VERSION ""

NS_ :

BS_:

BU_: PowertrainControlModule AtmosphericSensor SafetyRestraintSystem2 Aftertreatment_2_GasOutlet Aftertreatment_2_GasIntake DieselParticulateFilterControl Turbocharger SafetyRestraintSystem1 CabDisplay2 Aftertreatment_1_GasOutlet Aftertreatment_1_GasIntake OnBoardDataLogger OffBoardDiagnosticTool2 OffBoardDiagnosticTool1 FileServer ParkingBrakeController SeatController2 FanDriveController SteeringColumnUnit CommunicationUnitRadio CommunicationUnitSatellite CommunicationUnitCellular PropulsionBatteryCharger ChassisController2 ChassisController1 EngineValveControl AuxiliaryHeater2 AuxiliaryHeater1 ClutchUnit RampControl InformationSystem1 SuspensionSystemController2 OilSensor VehicleDynamicStability ExhaustEmissionController TransmissionDisplay2 TransmissionDisplay1 ClimateControl2 WaterPumpController RearAxleSteeringController LightingOperatorControl SeatController1 IgnitionController2 IgnitionController1 TirePressureController CabController2 CabController1 PneumaticSystemController SuspensionSystemController1 HydraulicPumpController EnduranceBrakingSystem RetarderExhaustEngine2 OnBoardDiagnosticUnit HeadwayController RetarderExhaustEngine1 CabDisplay1 ManagementComputer VirtualTerminal OffVehicleGateway PowerTakeOffFront HitchControl AuxiliaryValveControl BodyController TractorTrailerBridge1 StarterSystem ElectricalSystem VehicleSecurity VehicleNavigation AerodynamicControl ElectricalChargingSystem ClimateControl1 TripRecorder InstrumentCluster SuspensionDriveAxle2 SuspensionDriveAxle1 SuspensionSteerAxle SteeringController FuelSystem CruiseControl RetarderDriveline RetarderEngine BrakesDriveAxle2 BrakesDriveAxle1 BrakesSystemController BrakesSteerAxle AxleDrive2 AxleDrive1 AxleSteering PowerTakeOff ShiftConsoleSecondary ShiftConsolePrimary Transmission2 Transmission1 Engine2 Engine1

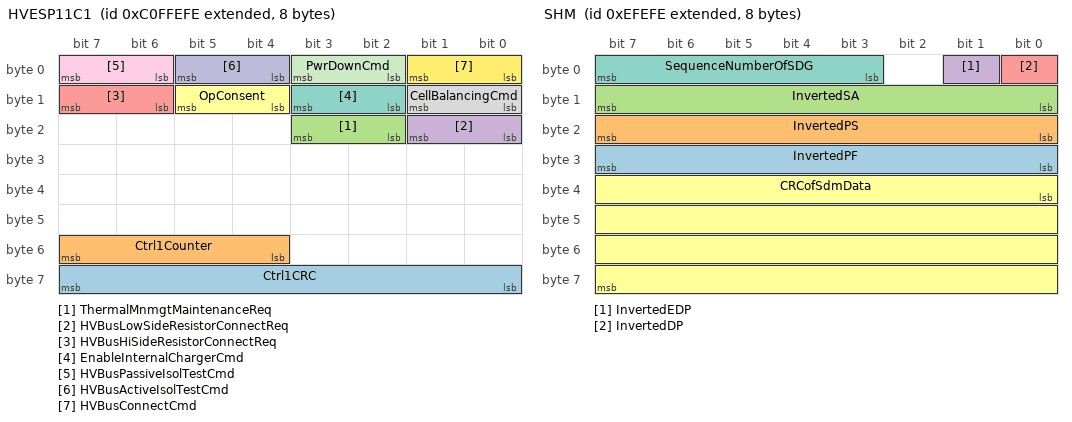
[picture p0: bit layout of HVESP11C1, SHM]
BO_ 2349858558 HVESP11C1: 8 Vector__XXX
 SG_ Ctrl1CRC : 56|8@1+ (1,0) [0|255] "" Vector__XXX
 SG_ Ctrl1Counter : 52|4@1+ (1,0) [0|15] "" Vector__XXX
 SG_ ThermalMnmgtMaintenanceReq : 18|2@1+ (1,0) [0|3] "" Vector__XXX
 SG_ HVBusLowSideResistorConnectReq : 16|2@1+ (1,0) [0|3] "" Vector__XXX
 SG_ HVBusHiSideResistorConnectReq : 14|2@1+ (1,0) [0|3] "" Vector__XXX
 SG_ OpConsent : 12|2@1+ (1,0) [0|3] "" Vector__XXX
 SG_ EnableInternalChargerCmd : 10|2@1+ (1,0) [0|3] "" Vector__XXX
 SG_ CellBalancingCmd : 8|2@1+ (1,0) [0|3] "" Vector__XXX
 SG_ HVBusPassiveIsolTestCmd : 6|2@1+ (1,0) [0|3] "" Vector__XXX
 SG_ HVBusActiveIsolTestCmd : 4|2@1+ (1,0) [0|3] "" Vector__XXX
 SG_ PwrDownCmd : 2|2@1+ (1,0) [0|3] "" Vector__XXX
 SG_ HVBusConnectCmd : 0|2@1+ (1,0) [0|3] "" Vector__XXX

BO_ 2148466430 SHM: 8 Vector__XXX
 SG_ InvertedPF : 24|8@1+ (-1,255) [0|0] "" Vector__XXX
 SG_ InvertedPS : 16|8@1+ (-1,255) [0|0] "" Vector__XXX
 SG_ InvertedSA : 8|8@1+ (-1,255) [0|0] "" Vector__XXX
 SG_ InvertedEDP : 1|1@1+ (-1,1) [0|0] "" Vector__XXX
 SG_ InvertedDP : 0|1@1+ (-1,1) [0|0] "" Vector__XXX
 SG_ CRCofSdmData : 32|32@1+ (1,0) [0|0] "" Vector__XXX
 SG_ SequenceNumberOfSDG : 3|5@1+ (1,0) [0|0] "" Vector__XXX

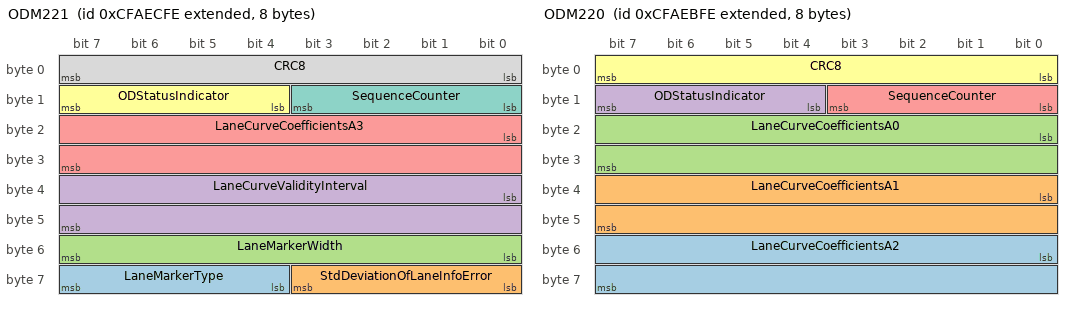
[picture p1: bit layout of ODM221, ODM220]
BO_ 2365254910 ODM221: 8 Vector__XXX
 SG_ LaneMarkerType : 60|4@1- (1,0) [0|15] "" Vector__XXX
 SG_ StdDeviationOfLaneInfoError : 56|4@1- (1,0) [0|15] "" Vector__XXX
 SG_ LaneMarkerWidth : 48|8@1+ (0.01,0) [0|2.5] "m" Vector__XXX
 SG_ LaneCurveValidityInterval : 32|16@1- (0.01,0) [-321.28|321.27] "m" Vector__XXX
 SG_ LaneCurveCoefficientsA3 : 16|16@1- (0.01,0) [-321.28|321.27] "" Vector__XXX
 SG_ ODStatusIndicator : 12|4@1+ (1,0) [0|0] "" Vector__XXX
 SG_ SequenceCounter : 8|4@1+ (1,0) [0|15] "" Vector__XXX
 SG_ CRC8 : 0|8@1+ (1,0) [0|255] "" Vector__XXX

BO_ 2365254654 ODM220: 8 Vector__XXX
 SG_ LaneCurveCoefficientsA2 : 48|16@1- (0.01,0) [-321.28|321.27] "" Vector__XXX
 SG_ LaneCurveCoefficientsA1 : 32|16@1- (0.01,0) [-321.28|321.27] "" Vector__XXX
 SG_ LaneCurveCoefficientsA0 : 16|16@1- (0.01,0) [-321.28|321.27] "" Vector__XXX
 SG_ ODStatusIndicator : 12|4@1+ (1,0) [0|0] "" Vector__XXX
 SG_ SequenceCounter : 8|4@1+ (1,0) [0|15] "" Vector__XXX
 SG_ CRC8 : 0|8@1+ (1,0) [0|255] "" Vector__XXX

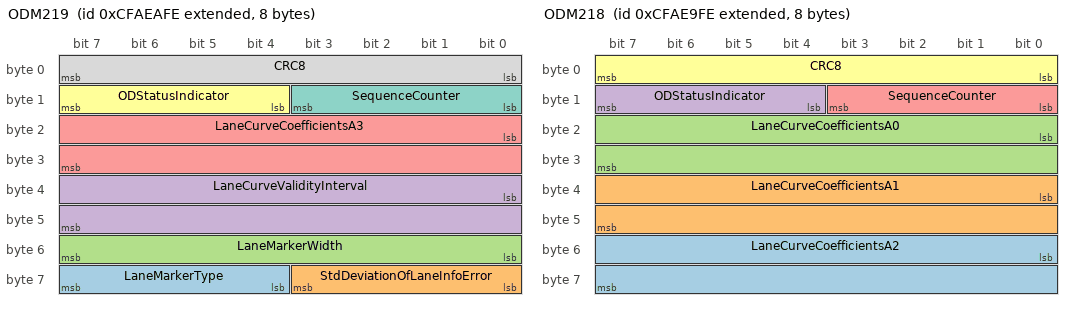
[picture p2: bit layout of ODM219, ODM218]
BO_ 2365254398 ODM219: 8 Vector__XXX
 SG_ LaneMarkerType : 60|4@1- (1,0) [0|15] "" Vector__XXX
 SG_ StdDeviationOfLaneInfoError : 56|4@1- (1,0) [0|15] "" Vector__XXX
 SG_ LaneMarkerWidth : 48|8@1+ (0.01,0) [0|2.5] "m" Vector__XXX
 SG_ LaneCurveValidityInterval : 32|16@1- (0.01,0) [-321.28|321.27] "m" Vector__XXX
 SG_ LaneCurveCoefficientsA3 : 16|16@1- (0.01,0) [-321.28|321.27] "" Vector__XXX
 SG_ ODStatusIndicator : 12|4@1+ (1,0) [0|0] "" Vector__XXX
 SG_ SequenceCounter : 8|4@1+ (1,0) [0|15] "" Vector__XXX
 SG_ CRC8 : 0|8@1+ (1,0) [0|255] "" Vector__XXX

BO_ 2365254142 ODM218: 8 Vector__XXX
 SG_ LaneCurveCoefficientsA2 : 48|16@1- (0.01,0) [-321.28|321.27] "" Vector__XXX
 SG_ LaneCurveCoefficientsA1 : 32|16@1- (0.01,0) [-321.28|321.27] "" Vector__XXX
 SG_ LaneCurveCoefficientsA0 : 16|16@1- (0.01,0) [-321.28|321.27] "" Vector__XXX
 SG_ ODStatusIndicator : 12|4@1+ (1,0) [0|0] "" Vector__XXX
 SG_ SequenceCounter : 8|4@1+ (1,0) [0|15] "" Vector__XXX
 SG_ CRC8 : 0|8@1+ (1,0) [0|255] "" Vector__XXX

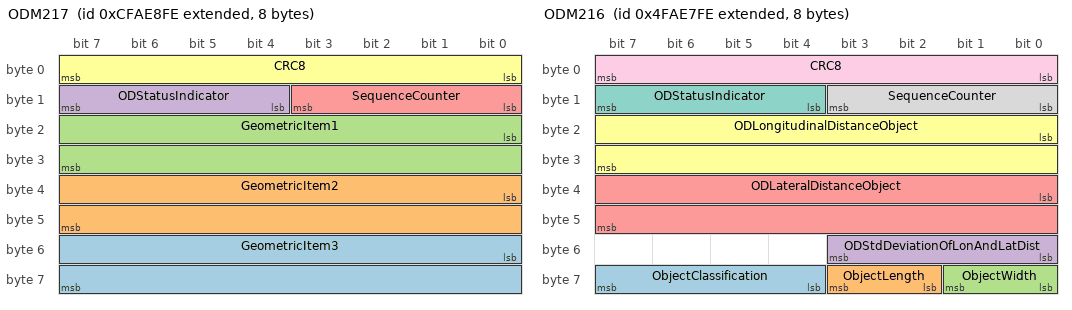
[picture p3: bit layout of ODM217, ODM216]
BO_ 2365253886 ODM217: 8 Vector__XXX
 SG_ GeometricItem3 : 48|16@1- (0.01,0) [-321.28|321.27] "m" Vector__XXX
 SG_ GeometricItem2 : 32|16@1- (0.01,0) [-321.28|321.27] "m" Vector__XXX
 SG_ GeometricItem1 : 16|16@1- (0.01,0) [-321.28|321.27] "m" Vector__XXX
 SG_ ODStatusIndicator : 12|4@1+ (1,0) [0|0] "" Vector__XXX
 SG_ SequenceCounter : 8|4@1+ (1,0) [0|15] "" Vector__XXX
 SG_ CRC8 : 0|8@1+ (1,0) [0|255] "" Vector__XXX

BO_ 2231035902 ODM216: 8 Vector__XXX
 SG_ ObjectClassification : 60|4@1+ (1,0) [0|15] "" Vector__XXX
 SG_ ObjectLength : 58|2@1+ (1,0) [0|3] "" Vector__XXX
 SG_ ObjectWidth : 56|2@1+ (1,0) [0|3] "" Vector__XXX
 SG_ ODStdDeviationOfLonAndLatDist : 48|4@1+ (1,0) [0|15] "" Vector__XXX
 SG_ ODLateralDistanceObject : 32|16@1- (0.01,0) [-321.28|321.27] "m" Vector__XXX
 SG_ ODLongitudinalDistanceObject : 16|16@1- (0.01,0) [-321.28|321.27] "m" Vector__XXX
 SG_ ODStatusIndicator : 12|4@1+ (1,0) [0|0] "" Vector__XXX
 SG_ SequenceCounter : 8|4@1+ (1,0) [0|15] "" Vector__XXX
 SG_ CRC8 : 0|8@1+ (1,0) [0|255] "" Vector__XXX

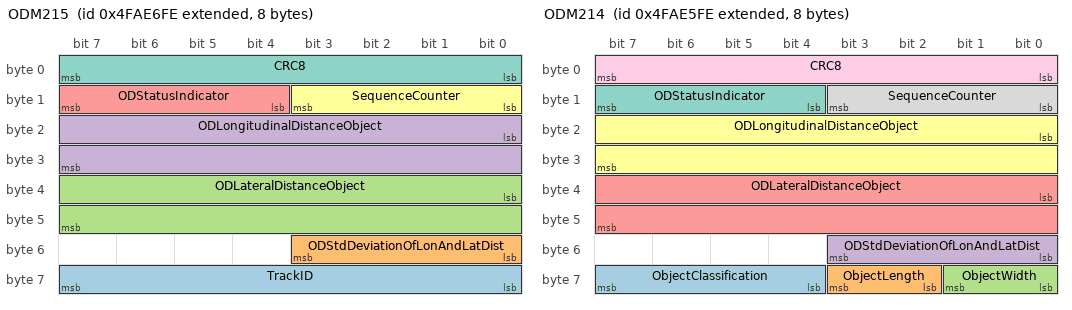
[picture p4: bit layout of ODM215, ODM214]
BO_ 2231035646 ODM215: 8 Vector__XXX
 SG_ TrackID : 56|8@1+ (1,0) [1|250] "" Vector__XXX
 SG_ ODStdDeviationOfLonAndLatDist : 48|4@1+ (1,0) [0|15] "" Vector__XXX
 SG_ ODLateralDistanceObject : 32|16@1- (0.01,0) [-321.28|321.27] "m" Vector__XXX
 SG_ ODLongitudinalDistanceObject : 16|16@1- (0.01,0) [-321.28|321.27] "m" Vector__XXX
 SG_ ODStatusIndicator : 12|4@1+ (1,0) [0|0] "" Vector__XXX
 SG_ SequenceCounter : 8|4@1+ (1,0) [0|15] "" Vector__XXX
 SG_ CRC8 : 0|8@1+ (1,0) [0|255] "" Vector__XXX

BO_ 2231035390 ODM214: 8 Vector__XXX
 SG_ ObjectClassification : 60|4@1+ (1,0) [0|15] "" Vector__XXX
 SG_ ObjectLength : 58|2@1+ (1,0) [0|3] "" Vector__XXX
 SG_ ObjectWidth : 56|2@1+ (1,0) [0|3] "" Vector__XXX
 SG_ ODStdDeviationOfLonAndLatDist : 48|4@1+ (1,0) [0|15] "" Vector__XXX
 SG_ ODLateralDistanceObject : 32|16@1- (0.01,0) [-321.28|321.27] "m" Vector__XXX
 SG_ ODLongitudinalDistanceObject : 16|16@1- (0.01,0) [-321.28|321.27] "m" Vector__XXX
 SG_ ODStatusIndicator : 12|4@1+ (1,0) [0|0] "" Vector__XXX
 SG_ SequenceCounter : 8|4@1+ (1,0) [0|15] "" Vector__XXX
 SG_ CRC8 : 0|8@1+ (1,0) [0|255] "" Vector__XXX

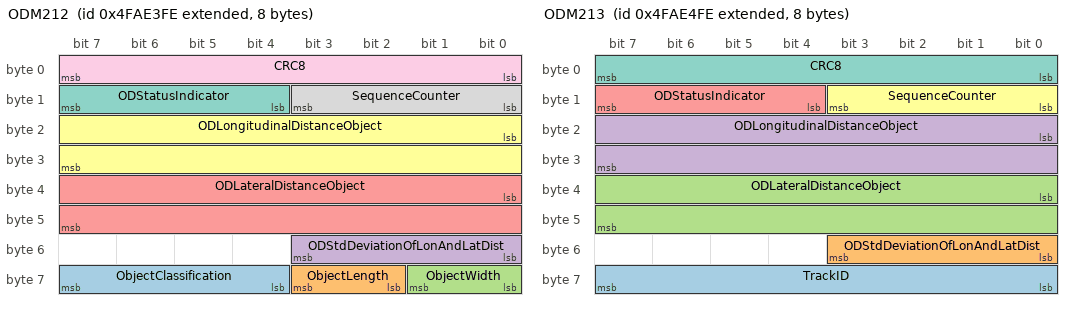
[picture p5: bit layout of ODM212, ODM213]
BO_ 2231034878 ODM212: 8 Vector__XXX
 SG_ ObjectClassification : 60|4@1+ (1,0) [0|15] "" Vector__XXX
 SG_ ObjectLength : 58|2@1+ (1,0) [0|3] "" Vector__XXX
 SG_ ObjectWidth : 56|2@1+ (1,0) [0|3] "" Vector__XXX
 SG_ ODStdDeviationOfLonAndLatDist : 48|4@1+ (1,0) [0|15] "" Vector__XXX
 SG_ ODLateralDistanceObject : 32|16@1- (0.01,0) [-321.28|321.27] "m" Vector__XXX
 SG_ ODLongitudinalDistanceObject : 16|16@1- (0.01,0) [-321.28|321.27] "m" Vector__XXX
 SG_ ODStatusIndicator : 12|4@1+ (1,0) [0|0] "" Vector__XXX
 SG_ SequenceCounter : 8|4@1+ (1,0) [0|15] "" Vector__XXX
 SG_ CRC8 : 0|8@1+ (1,0) [0|255] "" Vector__XXX

BO_ 2231035134 ODM213: 8 Vector__XXX
 SG_ TrackID : 56|8@1+ (1,0) [1|250] "" Vector__XXX
 SG_ ODStdDeviationOfLonAndLatDist : 48|4@1+ (1,0) [0|15] "" Vector__XXX
 SG_ ODLateralDistanceObject : 32|16@1- (0.01,0) [-321.28|321.27] "m" Vector__XXX
 SG_ ODLongitudinalDistanceObject : 16|16@1- (0.01,0) [-321.28|321.27] "m" Vector__XXX
 SG_ ODStatusIndicator : 12|4@1+ (1,0) [0|0] "" Vector__XXX
 SG_ SequenceCounter : 8|4@1+ (1,0) [0|15] "" Vector__XXX
 SG_ CRC8 : 0|8@1+ (1,0) [0|255] "" Vector__XXX

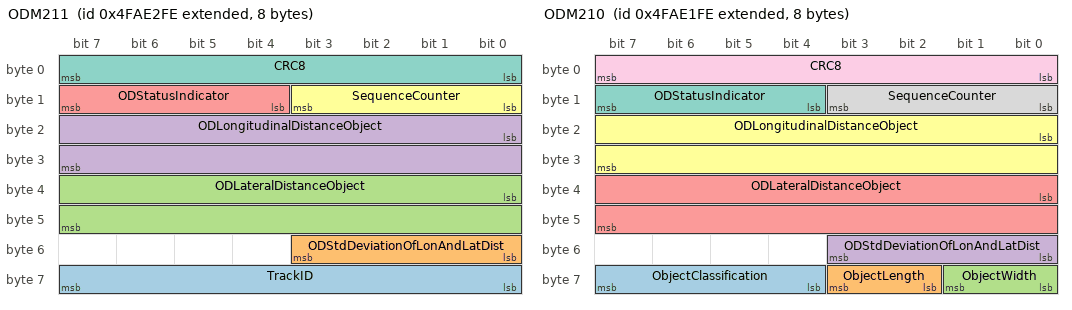
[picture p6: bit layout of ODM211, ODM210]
BO_ 2231034622 ODM211: 8 Vector__XXX
 SG_ TrackID : 56|8@1+ (1,0) [1|250] "" Vector__XXX
 SG_ ODStdDeviationOfLonAndLatDist : 48|4@1+ (1,0) [0|15] "" Vector__XXX
 SG_ ODLateralDistanceObject : 32|16@1- (0.01,0) [-321.28|321.27] "m" Vector__XXX
 SG_ ODLongitudinalDistanceObject : 16|16@1- (0.01,0) [-321.28|321.27] "m" Vector__XXX
 SG_ ODStatusIndicator : 12|4@1+ (1,0) [0|0] "" Vector__XXX
 SG_ SequenceCounter : 8|4@1+ (1,0) [0|15] "" Vector__XXX
 SG_ CRC8 : 0|8@1+ (1,0) [0|255] "" Vector__XXX

BO_ 2231034366 ODM210: 8 Vector__XXX
 SG_ ObjectClassification : 60|4@1+ (1,0) [0|15] "" Vector__XXX
 SG_ ObjectLength : 58|2@1+ (1,0) [0|3] "" Vector__XXX
 SG_ ObjectWidth : 56|2@1+ (1,0) [0|3] "" Vector__XXX
 SG_ ODStdDeviationOfLonAndLatDist : 48|4@1+ (1,0) [0|15] "" Vector__XXX
 SG_ ODLateralDistanceObject : 32|16@1- (0.01,0) [-321.28|321.27] "m" Vector__XXX
 SG_ ODLongitudinalDistanceObject : 16|16@1- (0.01,0) [-321.28|321.27] "m" Vector__XXX
 SG_ ODStatusIndicator : 12|4@1+ (1,0) [0|0] "" Vector__XXX
 SG_ SequenceCounter : 8|4@1+ (1,0) [0|15] "" Vector__XXX
 SG_ CRC8 : 0|8@1+ (1,0) [0|255] "" Vector__XXX

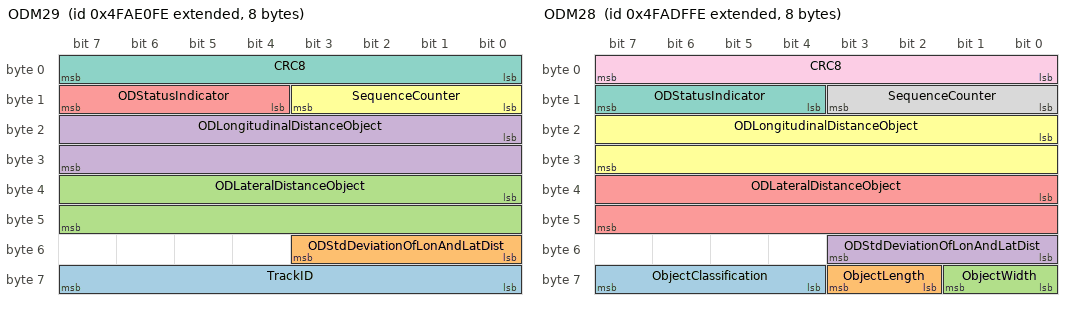
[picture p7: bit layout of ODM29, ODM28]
BO_ 2231034110 ODM29: 8 Vector__XXX
 SG_ TrackID : 56|8@1+ (1,0) [1|250] "" Vector__XXX
 SG_ ODStdDeviationOfLonAndLatDist : 48|4@1+ (1,0) [0|15] "" Vector__XXX
 SG_ ODLateralDistanceObject : 32|16@1- (0.01,0) [-321.28|321.27] "m" Vector__XXX
 SG_ ODLongitudinalDistanceObject : 16|16@1- (0.01,0) [-321.28|321.27] "m" Vector__XXX
 SG_ ODStatusIndicator : 12|4@1+ (1,0) [0|0] "" Vector__XXX
 SG_ SequenceCounter : 8|4@1+ (1,0) [0|15] "" Vector__XXX
 SG_ CRC8 : 0|8@1+ (1,0) [0|255] "" Vector__XXX

BO_ 2231033854 ODM28: 8 Vector__XXX
 SG_ ObjectClassification : 60|4@1+ (1,0) [0|15] "" Vector__XXX
 SG_ ObjectLength : 58|2@1+ (1,0) [0|3] "" Vector__XXX
 SG_ ObjectWidth : 56|2@1+ (1,0) [0|3] "" Vector__XXX
 SG_ ODStdDeviationOfLonAndLatDist : 48|4@1+ (1,0) [0|15] "" Vector__XXX
 SG_ ODLateralDistanceObject : 32|16@1- (0.01,0) [-321.28|321.27] "m" Vector__XXX
 SG_ ODLongitudinalDistanceObject : 16|16@1- (0.01,0) [-321.28|321.27] "m" Vector__XXX
 SG_ ODStatusIndicator : 12|4@1+ (1,0) [0|0] "" Vector__XXX
 SG_ SequenceCounter : 8|4@1+ (1,0) [0|15] "" Vector__XXX
 SG_ CRC8 : 0|8@1+ (1,0) [0|255] "" Vector__XXX

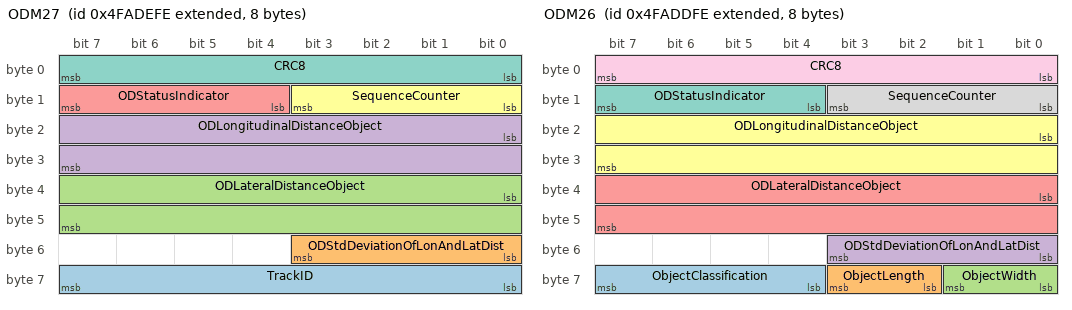
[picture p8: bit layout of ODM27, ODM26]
BO_ 2231033598 ODM27: 8 Vector__XXX
 SG_ TrackID : 56|8@1+ (1,0) [1|250] "" Vector__XXX
 SG_ ODStdDeviationOfLonAndLatDist : 48|4@1+ (1,0) [0|15] "" Vector__XXX
 SG_ ODLateralDistanceObject : 32|16@1- (0.01,0) [-321.28|321.27] "m" Vector__XXX
 SG_ ODLongitudinalDistanceObject : 16|16@1- (0.01,0) [-321.28|321.27] "m" Vector__XXX
 SG_ ODStatusIndicator : 12|4@1+ (1,0) [0|0] "" Vector__XXX
 SG_ SequenceCounter : 8|4@1+ (1,0) [0|15] "" Vector__XXX
 SG_ CRC8 : 0|8@1+ (1,0) [0|255] "" Vector__XXX

BO_ 2231033342 ODM26: 8 Vector__XXX
 SG_ ObjectClassification : 60|4@1+ (1,0) [0|15] "" Vector__XXX
 SG_ ObjectLength : 58|2@1+ (1,0) [0|3] "" Vector__XXX
 SG_ ObjectWidth : 56|2@1+ (1,0) [0|3] "" Vector__XXX
 SG_ ODStdDeviationOfLonAndLatDist : 48|4@1+ (1,0) [0|15] "" Vector__XXX
 SG_ ODLateralDistanceObject : 32|16@1- (0.01,0) [-321.28|321.27] "m" Vector__XXX
 SG_ ODLongitudinalDistanceObject : 16|16@1- (0.01,0) [-321.28|321.27] "m" Vector__XXX
 SG_ ODStatusIndicator : 12|4@1+ (1,0) [0|0] "" Vector__XXX
 SG_ SequenceCounter : 8|4@1+ (1,0) [0|15] "" Vector__XXX
 SG_ CRC8 : 0|8@1+ (1,0) [0|255] "" Vector__XXX

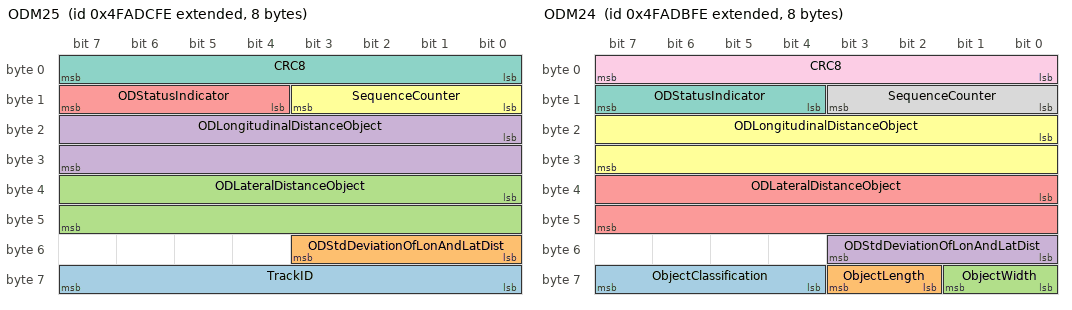
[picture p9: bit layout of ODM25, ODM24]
BO_ 2231033086 ODM25: 8 Vector__XXX
 SG_ TrackID : 56|8@1+ (1,0) [1|250] "" Vector__XXX
 SG_ ODStdDeviationOfLonAndLatDist : 48|4@1+ (1,0) [0|15] "" Vector__XXX
 SG_ ODLateralDistanceObject : 32|16@1- (0.01,0) [-321.28|321.27] "m" Vector__XXX
 SG_ ODLongitudinalDistanceObject : 16|16@1- (0.01,0) [-321.28|321.27] "m" Vector__XXX
 SG_ ODStatusIndicator : 12|4@1+ (1,0) [0|0] "" Vector__XXX
 SG_ SequenceCounter : 8|4@1+ (1,0) [0|15] "" Vector__XXX
 SG_ CRC8 : 0|8@1+ (1,0) [0|255] "" Vector__XXX

BO_ 2231032830 ODM24: 8 Vector__XXX
 SG_ ObjectClassification : 60|4@1+ (1,0) [0|15] "" Vector__XXX
 SG_ ObjectLength : 58|2@1+ (1,0) [0|3] "" Vector__XXX
 SG_ ObjectWidth : 56|2@1+ (1,0) [0|3] "" Vector__XXX
 SG_ ODStdDeviationOfLonAndLatDist : 48|4@1+ (1,0) [0|15] "" Vector__XXX
 SG_ ODLateralDistanceObject : 32|16@1- (0.01,0) [-321.28|321.27] "m" Vector__XXX
 SG_ ODLongitudinalDistanceObject : 16|16@1- (0.01,0) [-321.28|321.27] "m" Vector__XXX
 SG_ ODStatusIndicator : 12|4@1+ (1,0) [0|0] "" Vector__XXX
 SG_ SequenceCounter : 8|4@1+ (1,0) [0|15] "" Vector__XXX
 SG_ CRC8 : 0|8@1+ (1,0) [0|255] "" Vector__XXX

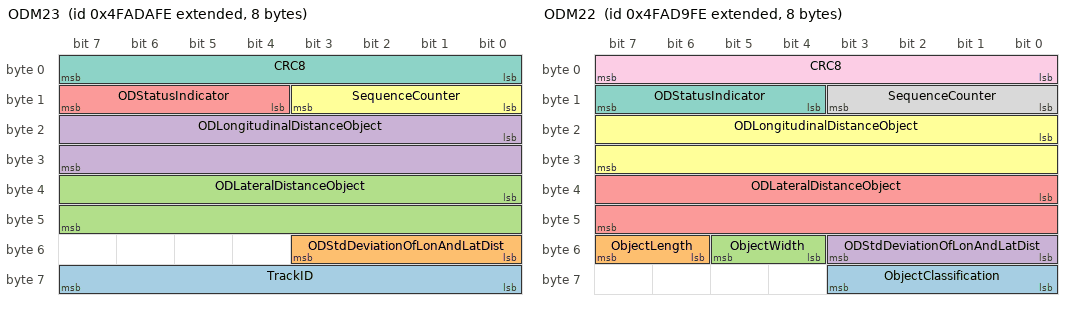
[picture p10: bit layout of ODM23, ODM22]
BO_ 2231032574 ODM23: 8 Vector__XXX
 SG_ TrackID : 56|8@1+ (1,0) [1|250] "" Vector__XXX
 SG_ ODStdDeviationOfLonAndLatDist : 48|4@1+ (1,0) [0|15] "" Vector__XXX
 SG_ ODLateralDistanceObject : 32|16@1- (0.01,0) [-321.28|321.27] "m" Vector__XXX
 SG_ ODLongitudinalDistanceObject : 16|16@1- (0.01,0) [-321.28|321.27] "m" Vector__XXX
 SG_ ODStatusIndicator : 12|4@1+ (1,0) [0|0] "" Vector__XXX
 SG_ SequenceCounter : 8|4@1+ (1,0) [0|15] "" Vector__XXX
 SG_ CRC8 : 0|8@1+ (1,0) [0|255] "" Vector__XXX

BO_ 2231032318 ODM22: 8 Vector__XXX
 SG_ ObjectClassification : 56|4@1+ (1,0) [0|15] "" Vector__XXX
 SG_ ObjectLength : 54|2@1+ (1,0) [0|3] "" Vector__XXX
 SG_ ObjectWidth : 52|2@1+ (1,0) [0|3] "" Vector__XXX
 SG_ ODStdDeviationOfLonAndLatDist : 48|4@1+ (1,0) [0|15] "" Vector__XXX
 SG_ ODLateralDistanceObject : 32|16@1- (0.01,0) [-321.28|321.27] "m" Vector__XXX
 SG_ ODLongitudinalDistanceObject : 16|16@1- (0.01,0) [-321.28|321.27] "m" Vector__XXX
 SG_ ODStatusIndicator : 12|4@1+ (1,0) [0|0] "" Vector__XXX
 SG_ SequenceCounter : 8|4@1+ (1,0) [0|15] "" Vector__XXX
 SG_ CRC8 : 0|8@1+ (1,0) [0|255] "" Vector__XXX

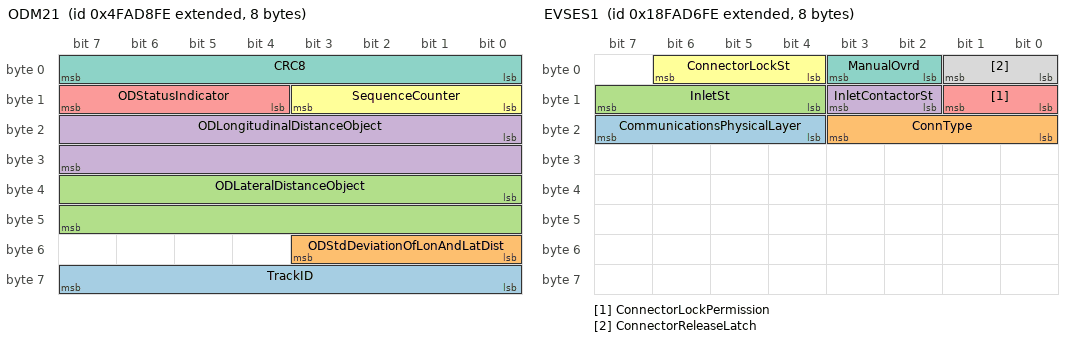
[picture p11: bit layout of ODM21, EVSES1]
BO_ 2231032062 ODM21: 8 Vector__XXX
 SG_ TrackID : 56|8@1+ (1,0) [1|250] "" Vector__XXX
 SG_ ODStdDeviationOfLonAndLatDist : 48|4@1+ (1,0) [0|15] "" Vector__XXX
 SG_ ODLateralDistanceObject : 32|16@1- (0.01,0) [-321.28|321.27] "m" Vector__XXX
 SG_ ODLongitudinalDistanceObject : 16|16@1- (0.01,0) [-321.28|321.27] "m" Vector__XXX
 SG_ ODStatusIndicator : 12|4@1+ (1,0) [0|0] "" Vector__XXX
 SG_ SequenceCounter : 8|4@1+ (1,0) [0|15] "" Vector__XXX
 SG_ CRC8 : 0|8@1+ (1,0) [0|255] "" Vector__XXX

BO_ 2566575870 EVSES1: 8 Vector__XXX
 SG_ CommunicationsPhysicalLayer : 20|4@1+ (1,0) [0|15] "" Vector__XXX
 SG_ ConnType : 16|4@1+ (1,0) [0|15] "" Vector__XXX
 SG_ InletSt : 12|4@1+ (1,0) [0|15] "" Vector__XXX
 SG_ InletContactorSt : 10|2@1+ (1,0) [0|3] "" Vector__XXX
 SG_ ConnectorLockPermission : 8|2@1+ (1,0) [0|3] "" Vector__XXX
 SG_ ConnectorLockSt : 4|3@1+ (1,0) [0|7] "" Vector__XXX
 SG_ ManualOvrd : 2|2@1+ (1,0) [0|3] "" Vector__XXX
 SG_ ConnectorReleaseLatch : 0|2@1+ (1,0) [0|3] "" Vector__XXX

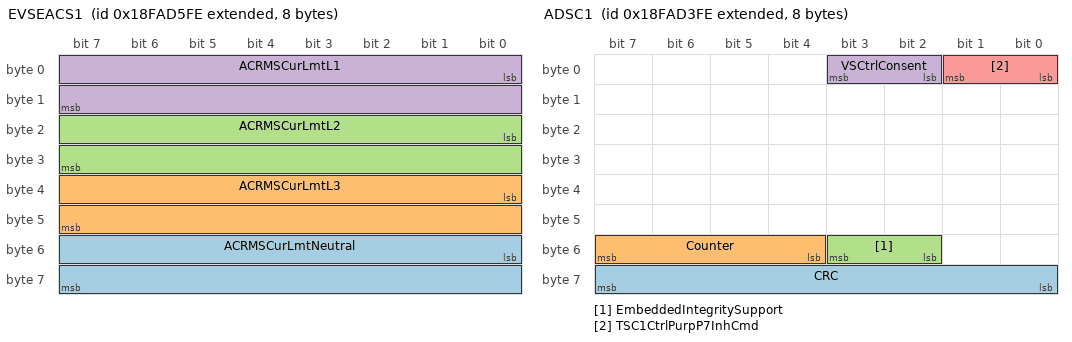
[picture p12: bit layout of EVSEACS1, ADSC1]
BO_ 2566575614 EVSEACS1: 8 Vector__XXX
 SG_ ACRMSCurLmtNeutral : 48|16@1+ (0.0625,0) [0|4015.9375] "A" Vector__XXX
 SG_ ACRMSCurLmtL3 : 32|16@1+ (0.0625,0) [0|4015.9375] "A" Vector__XXX
 SG_ ACRMSCurLmtL2 : 16|16@1+ (0.0625,0) [0|4015.9375] "A" Vector__XXX
 SG_ ACRMSCurLmtL1 : 0|16@1+ (0.0625,0) [0|4015.9375] "A" Vector__XXX

BO_ 2566575358 EVSEACS2: 8 Vector__XXX
 SG_ RMSV : 16|16@1+ (0.05,0) [0|3212.75] "V" Vector__XXX
 SG_ RMSCur : 0|16@1+ (0.05,-1600) [-1600|1612.75] "A" Vector__XXX

BO_ 2566575102 ADSC1: 8 Vector__XXX
 SG_ CRC : 56|8@1+ (1,0) [0|255] "" Vector__XXX
 SG_ Counter : 52|4@1+ (1,0) [0|15] "" Vector__XXX
 SG_ EmbeddedIntegritySupport : 50|2@1+ (1,0) [0|3] "" Vector__XXX
 SG_ VSCtrlConsent : 2|2@1+ (1,0) [0|3] "" Vector__XXX
 SG_ TSC1CtrlPurpP7InhCmd : 0|2@1+ (1,0) [0|3] "" Vector__XXX

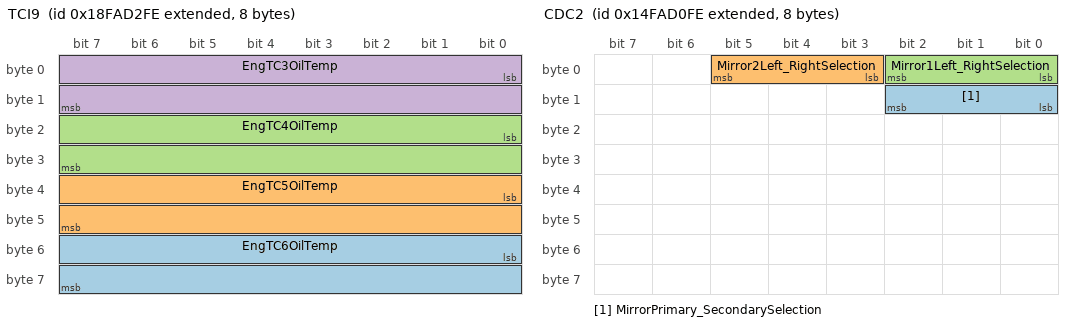
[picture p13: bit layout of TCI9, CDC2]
BO_ 2566574846 TCI9: 8 Vector__XXX
 SG_ EngTC6OilTemp : 48|16@1+ (0.03125,-273) [-273|1734.96875] "°C" Vector__XXX
 SG_ EngTC5OilTemp : 32|16@1+ (0.03125,-273) [-273|1734.96875] "°C" Vector__XXX
 SG_ EngTC4OilTemp : 16|16@1+ (0.03125,-273) [-273|1734.96875] "°C" Vector__XXX
 SG_ EngTC3OilTemp : 0|16@1+ (0.03125,-273) [-273|1734.96875] "°C" Vector__XXX

BO_ 2499465726 EAI2: 8 Vector__XXX
 SG_ CylBank2TempAvg : 32|16@1+ (0.03125,-273) [-273|1734.96875] "°C" Vector__XXX
 SG_ CylBank1TempAvg : 16|16@1+ (0.03125,-273) [-273|1734.96875] "°C" Vector__XXX
 SG_ CylTempAvg : 0|16@1+ (0.03125,-273) [-273|1734.96875] "°C" Vector__XXX

BO_ 2499465470 CDC2: 8 Vector__XXX
 SG_ MirrorPrimary_SecondarySelection : 8|3@1+ (1,0) [0|7] "" Vector__XXX
 SG_ Mirror2Left_RightSelection : 3|3@1+ (1,0) [0|7] "" Vector__XXX
 SG_ Mirror1Left_RightSelection : 0|3@1+ (1,0) [0|7] "" Vector__XXX

BO_ 2566574078 EVCCD1: 12 Vector__XXX
 SG_ CompatibilityCode : 88|4@1+ (1,0) [0|15] "" Vector__XXX
 SG_ InletConnectorTemp : 80|8@1+ (1,-40) [-40|210] "°C" Vector__XXX
 SG_ ProximityCircV : 64|16@1+ (0.01,0) [0|642.55] "V" Vector__XXX
 SG_ CtrlPilotSubSt : 60|4@1+ (1,0) [0|15] "" Vector__XXX
 SG_ CtrlPilotSt : 56|4@1+ (1,0) [0|15] "" Vector__XXX
 SG_ CtrlPilotDutyCycle : 48|8@1+ (0.5,0) [0|125] "%" Vector__XXX
 SG_ CtrlPilotPWMFreq : 32|16@1+ (1,0) [0|64255] "Hz" Vector__XXX
 SG_ CtrlPilotMinV : 16|16@1+ (0.05,-1606) [-1606|1606.75] "V" Vector__XXX
 SG_ CtrlPilotMaxV : 0|16@1+ (0.05,-1606) [-1606|1606.75] "V" Vector__XXX

BO_ 2566573822 PTO2: 8 Vector__XXX
 SG_ TransPTOGearboxStatus : 16|4@1+ (1,0) [0|15] "" Vector__XXX
 SG_ TransPTOGearboxOSS : 0|16@1+ (0.125,0) [0|8031.875] "rpm" Vector__XXX

BO_ 2499464702 A1SCREGP2: 8 Vector__XXX
 SG_ OutPress : 16|16@1+ (0.1,0) [0|6425.5] "kPa" Vector__XXX
 SG_ OutAbsPress : 0|16@1+ (0.1,0) [0|6425.5] "kPa" Vector__XXX

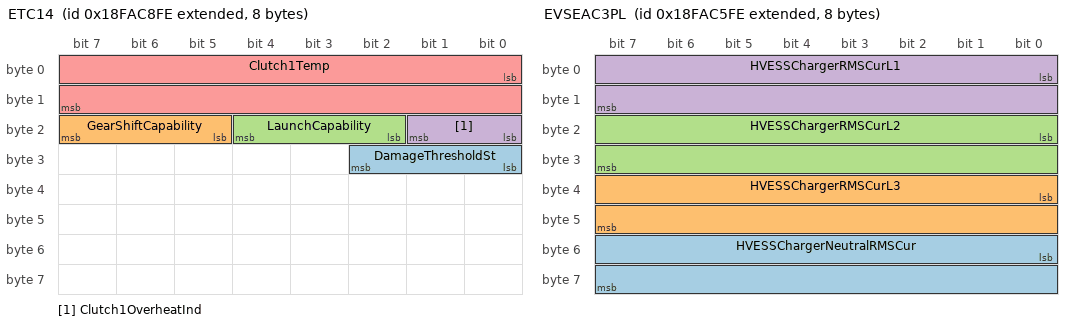
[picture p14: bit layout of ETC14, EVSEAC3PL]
BO_ 2566572286 ETC14: 8 Vector__XXX
 SG_ DamageThresholdSt : 24|3@1+ (1,0) [0|7] "" Vector__XXX
 SG_ GearShiftCapability : 21|3@1+ (1,0) [0|7] "" Vector__XXX
 SG_ LaunchCapability : 18|3@1+ (1,0) [0|7] "" Vector__XXX
 SG_ Clutch1OverheatInd : 16|2@1+ (1,0) [0|3] "" Vector__XXX
 SG_ Clutch1Temp : 0|16@1+ (0.03125,-273) [-273|1734.96875] "°C" Vector__XXX

BO_ 2566572030 DSCVS1: 8 Vector__XXX

BO_ 2499462910 ERC3: 8 Vector__XXX
 SG_ RoadSpdAccelerateSw : 2|2@1+ (1,0) [0|3] "" Vector__XXX
 SG_ RoadSpdDecelerateSw : 0|2@1+ (1,0) [0|3] "" Vector__XXX

BO_ 2566571518 EVSEAC3PL: 8 Vector__XXX
 SG_ HVESSChargerNeutralRMSCur : 48|16@1+ (0.0625,0) [0|4015.9375] "A" Vector__XXX
 SG_ HVESSChargerRMSCurL3 : 32|16@1+ (0.0625,0) [0|4015.9375] "A" Vector__XXX
 SG_ HVESSChargerRMSCurL2 : 16|16@1+ (0.0625,0) [0|4015.9375] "A" Vector__XXX
 SG_ HVESSChargerRMSCurL1 : 0|16@1+ (0.0625,0) [0|4015.9375] "A" Vector__XXX

BO_ 2566571262 EVSEACSV: 8 Vector__XXX
 SG_ NomSupplyFreq : 32|8@1+ (1,0) [0|255] "" Vector__XXX
 SG_ NomRMSVLineToLine : 16|16@1+ (0.05,0) [0|3212.75] "V" Vector__XXX
 SG_ NomRMSVLineToNeutral : 0|16@1+ (0.05,0) [0|3212.75] "V" Vector__XXX

BO_ 2566571006 AIR3: 8 Vector__XXX
 SG_ SuspensionSupplyPress2 : 8|8@1+ (8,0) [0|2000] "kPa" Vector__XXX
 SG_ DryerCartridgeLifeRemaining : 0|8@1+ (0.4,0) [0|100] "%" Vector__XXX

BO_ 2566570750 MG6LD: 16 Vector__XXX
 SG_ TotalChargeGenerated : 96|32@1+ (100,0) [0|421108121500] "Ah" Vector__XXX
 SG_ TotalChargeConsumed : 64|32@1+ (100,0) [0|421108121500] "Ah" Vector__XXX
 SG_ TotalEnergyGenerated : 32|32@1+ (100,0) [0|421108121500] "Wh" Vector__XXX
 SG_ TotalEnergyConsumed : 0|32@1+ (100,0) [0|421108121500] "Wh" Vector__XXX

BO_ 2566570494 MG5LD: 16 Vector__XXX
 SG_ TotalChargeGenerated : 96|32@1+ (100,0) [0|421108121500] "Ah" Vector__XXX
 SG_ TotalChargeConsumed : 64|32@1+ (100,0) [0|421108121500] "Ah" Vector__XXX
 SG_ TotalEnergyGenerated : 32|32@1+ (100,0) [0|421108121500] "Wh" Vector__XXX
 SG_ TotalEnergyConsumed : 0|32@1+ (100,0) [0|421108121500] "Wh" Vector__XXX

BO_ 2566570238 MG4LD: 16 Vector__XXX
 SG_ TotalChargeGenerated : 96|32@1+ (100,0) [0|421108121500] "Ah" Vector__XXX
 SG_ TotalChargeConsumed : 64|32@1+ (100,0) [0|421108121500] "Ah" Vector__XXX
 SG_ TotalEnergyGenerated : 32|32@1+ (100,0) [0|421108121500] "Wh" Vector__XXX
 SG_ TotalEnergyConsumed : 0|32@1+ (100,0) [0|421108121500] "Wh" Vector__XXX

BO_ 2566569982 MG3LD: 16 Vector__XXX
 SG_ TotalChargeGenerated : 96|32@1+ (100,0) [0|421108121500] "Ah" Vector__XXX
 SG_ TotalChargeConsumed : 64|32@1+ (100,0) [0|421108121500] "Ah" Vector__XXX
 SG_ TotalEnergyGenerated : 32|32@1+ (100,0) [0|421108121500] "Wh" Vector__XXX
 SG_ TotalEnergyConsumed : 0|32@1+ (100,0) [0|421108121500] "Wh" Vector__XXX

BO_ 2566569726 MG2LD: 16 Vector__XXX
 SG_ TotalChargeGenerated : 96|32@1+ (100,0) [0|421108121500] "Ah" Vector__XXX
 SG_ TotalChargeConsumed : 64|32@1+ (100,0) [0|421108121500] "Ah" Vector__XXX
 SG_ TotalEnergyGenerated : 32|32@1+ (100,0) [0|421108121500] "Wh" Vector__XXX
 SG_ TotalEnergyConsumed : 0|32@1+ (100,0) [0|421108121500] "Wh" Vector__XXX

BO_ 2566569470 MG1LD: 16 Vector__XXX
 SG_ TotalChargeGenerated : 96|32@1+ (100,0) [0|421108121500] "Ah" Vector__XXX
 SG_ TotalChargeConsumed : 64|32@1+ (100,0) [0|421108121500] "Ah" Vector__XXX
 SG_ TotalEnergyGenerated : 32|32@1+ (100,0) [0|421108121500] "Wh" Vector__XXX
 SG_ TotalEnergyConsumed : 0|32@1+ (100,0) [0|421108121500] "Wh" Vector__XXX

BO_ 2566569214 DLCD3: 8 Vector__XXX
 SG_ TransOilPressLowLamp : 2|2@1+ (1,0) [0|3] "" Vector__XXX
 SG_ TransOilTempHiLamp : 0|2@1+ (1,0) [0|3] "" Vector__XXX

BO_ 2566568958 DLCC3: 8 Vector__XXX
 SG_ TransOilPressLowLamp : 2|2@1+ (1,0) [0|3] "" Vector__XXX
 SG_ TransOilTempHiLamp : 0|2@1+ (1,0) [0|3] "" Vector__XXX

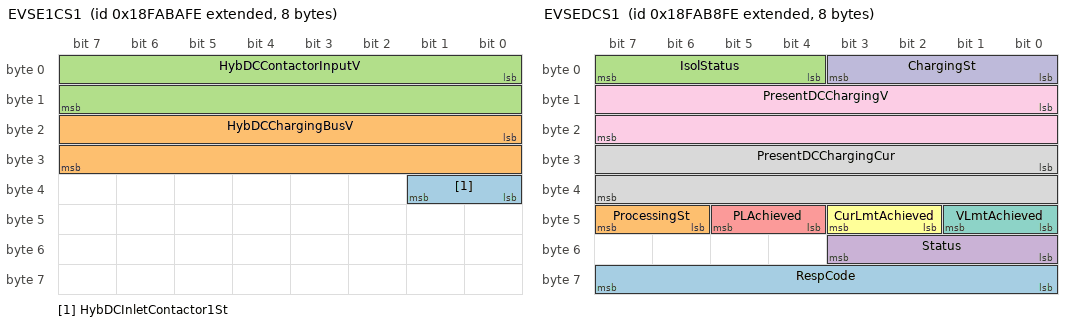
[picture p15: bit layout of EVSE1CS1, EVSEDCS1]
BO_ 2566568702 EVSE1CS1: 8 Vector__XXX
 SG_ HybDCInletContactor1St : 32|2@1+ (1,0) [0|3] "" Vector__XXX
 SG_ HybDCChargingBusV : 16|16@1+ (0.05,0) [0|3212.75] "V" Vector__XXX
 SG_ HybDCContactorInputV : 0|16@1+ (0.05,0) [0|3212.75] "V" Vector__XXX

BO_ 2566568446 EVSE1CC1: 8 Vector__XXX
 SG_ HybDCInletContactor1Cmd : 0|2@1+ (1,0) [0|3] "" Vector__XXX

BO_ 2566568190 EVSEDCS1: 8 Vector__XXX
 SG_ RespCode : 56|8@1+ (1,0) [0|255] "" Vector__XXX
 SG_ ProcessingSt : 46|2@1+ (1,0) [0|3] "" Vector__XXX
 SG_ IsolStatus : 4|4@1+ (1,0) [0|15] "" Vector__XXX
 SG_ Status : 48|4@1+ (1,0) [0|15] "" Vector__XXX
 SG_ PLAchieved : 44|2@1+ (1,0) [0|3] "" Vector__XXX
 SG_ CurLmtAchieved : 42|2@1+ (1,0) [0|3] "" Vector__XXX
 SG_ VLmtAchieved : 40|2@1+ (1,0) [0|3] "" Vector__XXX
 SG_ PresentDCChargingCur : 24|16@1+ (0.05,-1600) [-1600|1612.75] "A" Vector__XXX
 SG_ PresentDCChargingV : 8|16@1+ (0.05,0) [0|3212.75] "V" Vector__XXX
 SG_ ChargingSt : 0|4@1+ (1,0) [0|15] "" Vector__XXX

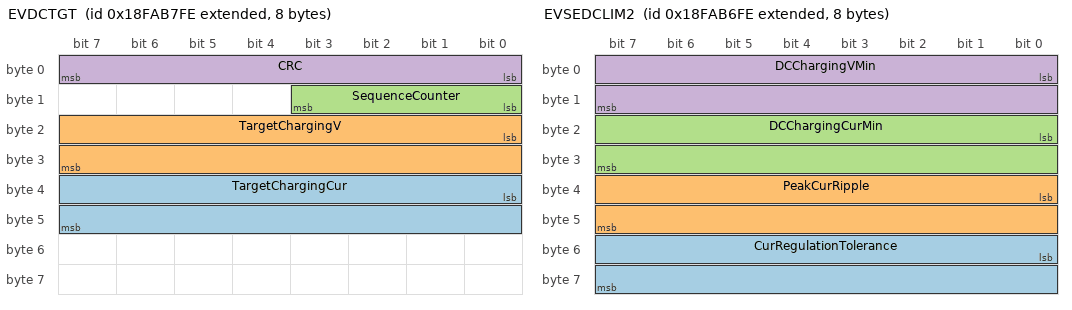
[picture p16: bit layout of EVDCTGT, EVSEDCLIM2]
BO_ 2566567934 EVDCTGT: 8 Vector__XXX
 SG_ TargetChargingCur : 32|16@1+ (0.0625,0) [0|4015.9375] "A" Vector__XXX
 SG_ TargetChargingV : 16|16@1+ (0.05,0) [0|3212.75] "V" Vector__XXX
 SG_ SequenceCounter : 8|4@1+ (1,0) [0|15] "" Vector__XXX
 SG_ CRC : 0|8@1+ (1,0) [0|255] "" Vector__XXX

BO_ 2566567678 EVSEDCLIM2: 8 Vector__XXX
 SG_ CurRegulationTolerance : 48|16@1+ (0.0625,0) [0|4015.9375] "A" Vector__XXX
 SG_ PeakCurRipple : 32|16@1+ (0.0625,0) [0|4015.9375] "A" Vector__XXX
 SG_ DCChargingCurMin : 16|16@1+ (0.0625,0) [0|4015.9375] "A" Vector__XXX
 SG_ DCChargingVMin : 0|16@1+ (0.05,0) [0|3212.75] "V" Vector__XXX

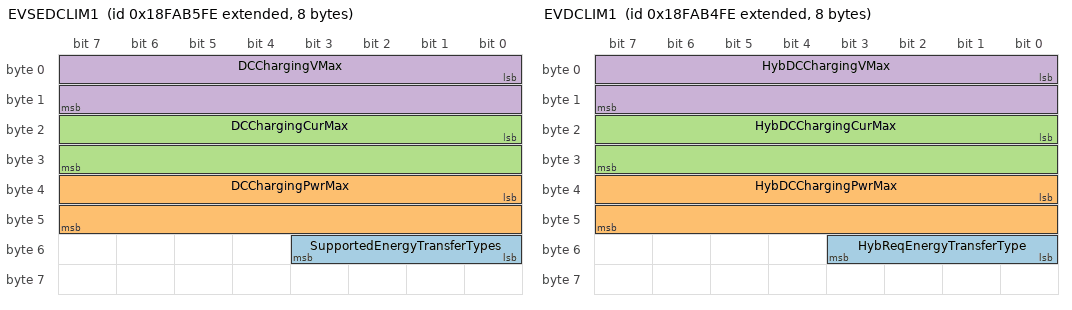
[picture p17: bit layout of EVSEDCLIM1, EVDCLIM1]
BO_ 2566567422 EVSEDCLIM1: 8 Vector__XXX
 SG_ SupportedEnergyTransferTypes : 48|4@1+ (1,0) [0|15] "" Vector__XXX
 SG_ DCChargingPwrMax : 32|16@1+ (0.05,0) [0|3212.75] "kW" Vector__XXX
 SG_ DCChargingCurMax : 16|16@1+ (0.0625,0) [0|4015.9375] "A" Vector__XXX
 SG_ DCChargingVMax : 0|16@1+ (0.05,0) [0|3212.75] "V" Vector__XXX

BO_ 2566567166 EVDCLIM1: 8 Vector__XXX
 SG_ HybReqEnergyTransferType : 48|4@1+ (1,0) [0|15] "" Vector__XXX
 SG_ HybDCChargingPwrMax : 32|16@1+ (0.05,0) [0|3212.75] "kW" Vector__XXX
 SG_ HybDCChargingCurMax : 16|16@1+ (0.0625,0) [0|4015.9375] "A" Vector__XXX
 SG_ HybDCChargingVMax : 0|16@1+ (0.05,0) [0|3212.75] "V" Vector__XXX

BO_ 2566566910 CanTSyn: 8 Vector__XXX

BO_ 2633675518 HVESP7HIST: 19 Vector__XXX
 SG_ TotalEnergyOut : 120|32@1+ (1,0) [0|4211081215] "kWh" Vector__XXX
 SG_ TotalEnergyInput : 88|32@1+ (1,0) [0|4211081215] "kWh" Vector__XXX
 SG_ TotalAccumulatedCharge : 56|32@1+ (100,0) [0|421108121500] "Ah" Vector__XXX
 SG_ TotalEnergyThroughput : 24|32@1+ (100,0) [0|421108121500] "Wh" Vector__XXX
 SG_ ContactorOpenUnderLoadCount : 8|16@1+ (1,0) [0|64255] "" Vector__XXX
 SG_ StOfHealth : 0|8@1+ (0.4,0) [0|100] "%" Vector__XXX

BO_ 2566566398 HVESP7CFG: 19 Vector__XXX
 SG_ NomRatedCapacity : 128|24@1+ (0.001,0) [0|16449.535] "kWh" Vector__XXX
 SG_ CellMinVLmt : 120|8@1+ (0.02044,0) [0|5.11] "V" Vector__XXX
 SG_ CellMaxVLmt : 112|8@1+ (0.02044,0) [0|5.11] "V" Vector__XXX
 SG_ RecommendedMinOperatingTemp : 96|16@1+ (0.03125,-273) [-273|1734.96875] "°C" Vector__XXX
 SG_ RecommendedMaxOperatingTemp : 80|16@1+ (0.03125,-273) [-273|1734.96875] "°C" Vector__XXX
 SG_ RecommendedMaxStOfCharge : 64|16@1+ (0.0015625,0) [0|100.3984375] "%" Vector__XXX
 SG_ RecommendedMinStOfCharge : 48|16@1+ (0.0015625,0) [0|100.3984375] "%" Vector__XXX
 SG_ RecommendedMaxOperatingV : 32|16@1+ (0.05,0) [0|3212.75] "V" Vector__XXX
 SG_ RecommendedMinOperatingV : 16|16@1+ (0.05,0) [0|3212.75] "V" Vector__XXX
 SG_ NomV : 0|16@1+ (0.05,0) [0|3212.75] "V" Vector__XXX

BO_ 2633675006 HVESP8HIST: 19 Vector__XXX
 SG_ TotalEnergyOut : 120|32@1+ (1,0) [0|4211081215] "kWh" Vector__XXX
 SG_ TotalEnergyInput : 88|32@1+ (1,0) [0|4211081215] "kWh" Vector__XXX
 SG_ TotalAccumulatedCharge : 56|32@1+ (100,0) [0|421108121500] "Ah" Vector__XXX
 SG_ TotalEnergyThroughput : 24|32@1+ (100,0) [0|421108121500] "Wh" Vector__XXX
 SG_ ContactorOpenUnderLoadCount : 8|16@1+ (1,0) [0|64255] "" Vector__XXX
 SG_ StOfHealth : 0|8@1+ (0.4,0) [0|100] "%" Vector__XXX

BO_ 2566565886 HVESP8CFG: 19 Vector__XXX
 SG_ NomRatedCapacity : 128|24@1+ (0.001,0) [0|16449.535] "kWh" Vector__XXX
 SG_ CellMinVLmt : 120|8@1+ (0.02044,0) [0|5.11] "V" Vector__XXX
 SG_ CellMaxVLmt : 112|8@1+ (0.02044,0) [0|5.11] "V" Vector__XXX
 SG_ RecommendedMinOperatingTemp : 96|16@1+ (0.03125,-273) [-273|1734.96875] "°C" Vector__XXX
 SG_ RecommendedMaxOperatingTemp : 80|16@1+ (0.03125,-273) [-273|1734.96875] "°C" Vector__XXX
 SG_ RecommendedMaxStOfCharge : 64|16@1+ (0.0015625,0) [0|100.3984375] "%" Vector__XXX
 SG_ RecommendedMinStOfCharge : 48|16@1+ (0.0015625,0) [0|100.3984375] "%" Vector__XXX
 SG_ RecommendedMaxOperatingV : 32|16@1+ (0.05,0) [0|3212.75] "V" Vector__XXX
 SG_ RecommendedMinOperatingV : 16|16@1+ (0.05,0) [0|3212.75] "V" Vector__XXX
 SG_ NomV : 0|16@1+ (0.05,0) [0|3212.75] "V" Vector__XXX

BO_ 2633674494 HVESP9HIST: 19 Vector__XXX
 SG_ TotalEnergyOut : 120|32@1+ (1,0) [0|4211081215] "kWh" Vector__XXX
 SG_ TotalEnergyInput : 88|32@1+ (1,0) [0|4211081215] "kWh" Vector__XXX
 SG_ TotalAccumulatedCharge : 56|32@1+ (100,0) [0|421108121500] "Ah" Vector__XXX
 SG_ TotalEnergyThroughput : 24|32@1+ (100,0) [0|421108121500] "Wh" Vector__XXX
 SG_ ContactorOpenUnderLoadCount : 8|16@1+ (1,0) [0|64255] "" Vector__XXX
 SG_ StOfHealth : 0|8@1+ (0.4,0) [0|100] "%" Vector__XXX

BO_ 2566565374 HVESP9CFG: 19 Vector__XXX
 SG_ NomRatedCapacity : 128|24@1+ (0.001,0) [0|16449.535] "kWh" Vector__XXX
 SG_ CellMinVLmt : 120|8@1+ (0.02044,0) [0|5.11] "V" Vector__XXX
 SG_ CellMaxVLmt : 112|8@1+ (0.02044,0) [0|5.11] "V" Vector__XXX
 SG_ RecommendedMinOperatingTemp : 96|16@1+ (0.03125,-273) [-273|1734.96875] "°C" Vector__XXX
 SG_ RecommendedMaxOperatingTemp : 80|16@1+ (0.03125,-273) [-273|1734.96875] "°C" Vector__XXX
 SG_ RecommendedMaxStOfCharge : 64|16@1+ (0.0015625,0) [0|100.3984375] "%" Vector__XXX
 SG_ RecommendedMinStOfCharge : 48|16@1+ (0.0015625,0) [0|100.3984375] "%" Vector__XXX
 SG_ RecommendedMaxOperatingV : 32|16@1+ (0.05,0) [0|3212.75] "V" Vector__XXX
 SG_ RecommendedMinOperatingV : 16|16@1+ (0.05,0) [0|3212.75] "V" Vector__XXX
 SG_ NomV : 0|16@1+ (0.05,0) [0|3212.75] "V" Vector__XXX

BO_ 2633673982 HVESP10HIST: 19 Vector__XXX
 SG_ TotalEnergyOut : 120|32@1+ (1,0) [0|4211081215] "kWh" Vector__XXX
 SG_ TotalEnergyInput : 88|32@1+ (1,0) [0|4211081215] "kWh" Vector__XXX
 SG_ TotalAccumulatedCharge : 56|32@1+ (100,0) [0|421108121500] "Ah" Vector__XXX
 SG_ TotalEnergyThroughput : 24|32@1+ (100,0) [0|421108121500] "Wh" Vector__XXX
 SG_ ContactorOpenUnderLoadCount : 8|16@1+ (1,0) [0|64255] "" Vector__XXX
 SG_ StOfHealth : 0|8@1+ (0.4,0) [0|100] "%" Vector__XXX

BO_ 2566564862 HVESP10CFG: 19 Vector__XXX
 SG_ NomRatedCapacity : 128|24@1+ (0.001,0) [0|16449.535] "kWh" Vector__XXX
 SG_ CellMinVLmt : 120|8@1+ (0.02044,0) [0|5.11] "V" Vector__XXX
 SG_ CellMaxVLmt : 112|8@1+ (0.02044,0) [0|5.11] "V" Vector__XXX
 SG_ RecommendedMinOperatingTemp : 96|16@1+ (0.03125,-273) [-273|1734.96875] "°C" Vector__XXX
 SG_ RecommendedMaxOperatingTemp : 80|16@1+ (0.03125,-273) [-273|1734.96875] "°C" Vector__XXX
 SG_ RecommendedMaxStOfCharge : 64|16@1+ (0.0015625,0) [0|100.3984375] "%" Vector__XXX
 SG_ RecommendedMinStOfCharge : 48|16@1+ (0.0015625,0) [0|100.3984375] "%" Vector__XXX
 SG_ RecommendedMaxOperatingV : 32|16@1+ (0.05,0) [0|3212.75] "V" Vector__XXX
 SG_ RecommendedMinOperatingV : 16|16@1+ (0.05,0) [0|3212.75] "V" Vector__XXX
 SG_ NomV : 0|16@1+ (0.05,0) [0|3212.75] "V" Vector__XXX

BO_ 2364690430 HVESP10D11: 8 Vector__XXX
 SG_ ActualChargeRate : 32|16@1+ (0.05,0) [0|3212.75] "kW" Vector__XXX
 SG_ LvlNegToChassisGroundV : 16|16@1+ (0.05,0) [0|3212.75] "V" Vector__XXX
 SG_ BusVNegToChassisGroundV : 0|16@1+ (0.05,0) [0|3212.75] "V" Vector__XXX

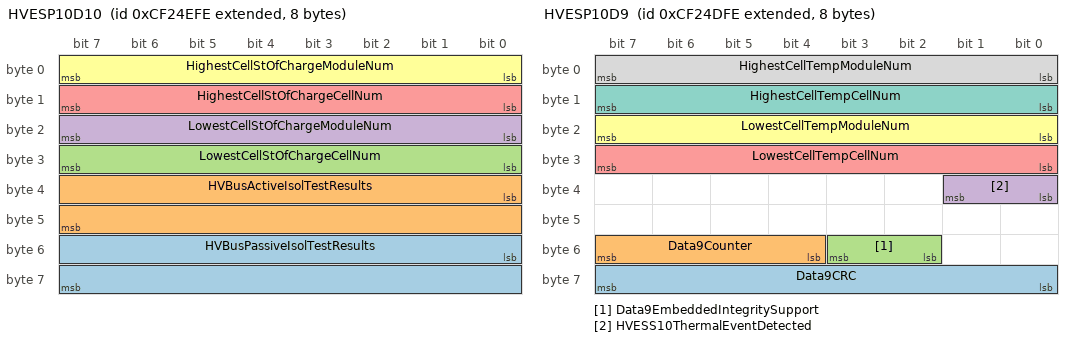
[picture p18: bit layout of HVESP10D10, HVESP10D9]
BO_ 2364690174 HVESP10D10: 8 Vector__XXX
 SG_ HVBusPassiveIsolTestResults : 48|16@1+ (0.1,0) [0|6425.5] "Ohm/V" Vector__XXX
 SG_ HVBusActiveIsolTestResults : 32|16@1+ (0.1,0) [0|6425.5] "Ohm/V" Vector__XXX
 SG_ LowestCellStOfChargeCellNum : 24|8@1+ (1,0) [0|250] "" Vector__XXX
 SG_ LowestCellStOfChargeModuleNum : 16|8@1+ (1,0) [0|250] "" Vector__XXX
 SG_ HighestCellStOfChargeCellNum : 8|8@1+ (1,0) [0|250] "" Vector__XXX
 SG_ HighestCellStOfChargeModuleNum : 0|8@1+ (1,0) [0|250] "" Vector__XXX

BO_ 2364689918 HVESP10D9: 8 Vector__XXX
 SG_ Data9CRC : 56|8@1+ (1,0) [0|255] "" Vector__XXX
 SG_ Data9Counter : 52|4@1+ (1,0) [0|15] "" Vector__XXX
 SG_ Data9EmbeddedIntegritySupport : 50|2@1+ (1,0) [0|3] "" Vector__XXX
 SG_ HVESS10ThermalEventDetected : 32|2@1+ (1,0) [0|3] "" Vector__XXX
 SG_ LowestCellTempCellNum : 24|8@1+ (1,0) [0|250] "" Vector__XXX
 SG_ LowestCellTempModuleNum : 16|8@1+ (1,0) [0|250] "" Vector__XXX
 SG_ HighestCellTempCellNum : 8|8@1+ (1,0) [0|250] "" Vector__XXX
 SG_ HighestCellTempModuleNum : 0|8@1+ (1,0) [0|250] "" Vector__XXX

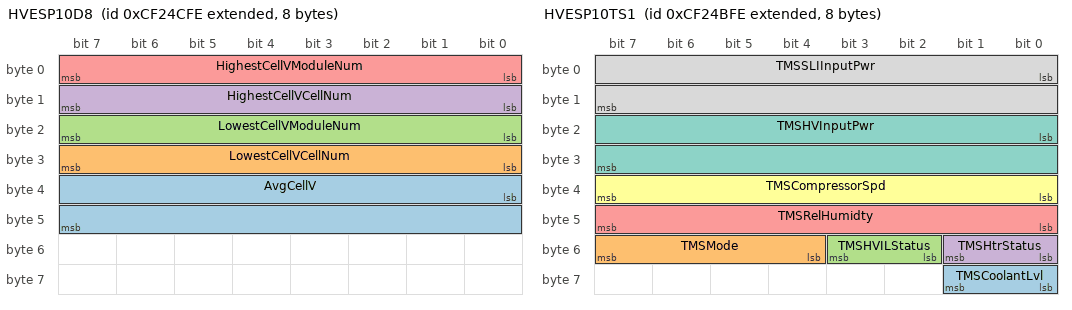
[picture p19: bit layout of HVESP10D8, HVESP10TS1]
BO_ 2364689662 HVESP10D8: 8 Vector__XXX
 SG_ AvgCellV : 32|16@1+ (0.001,0) [0|64.255] "V" Vector__XXX
 SG_ LowestCellVCellNum : 24|8@1+ (1,0) [0|250] "" Vector__XXX
 SG_ LowestCellVModuleNum : 16|8@1+ (1,0) [0|250] "" Vector__XXX
 SG_ HighestCellVCellNum : 8|8@1+ (1,0) [0|250] "" Vector__XXX
 SG_ HighestCellVModuleNum : 0|8@1+ (1,0) [0|250] "" Vector__XXX

BO_ 2364689406 HVESP10TS1: 8 Vector__XXX
 SG_ TMSCoolantLvl : 56|2@1+ (1,0) [0|3] "" Vector__XXX
 SG_ TMSMode : 52|4@1+ (1,0) [0|15] "" Vector__XXX
 SG_ TMSHVILStatus : 50|2@1+ (1,0) [0|3] "" Vector__XXX
 SG_ TMSHtrStatus : 48|2@1+ (1,0) [0|3] "" Vector__XXX
 SG_ TMSRelHumidty : 40|8@1+ (0.4,0) [0|100] "%" Vector__XXX
 SG_ TMSCompressorSpd : 32|8@1+ (32,0) [0|8000] "rpm" Vector__XXX
 SG_ TMSHVInputPwr : 16|16@1+ (0.5,0) [0|32127.5] "W" Vector__XXX
 SG_ TMSSLIInputPwr : 0|16@1+ (0.5,0) [0|32127.5] "W" Vector__XXX

BO_ 2364689150 HVESP10MS1: 8 Vector__XXX
 SG_ Module32OperationalStatus : 62|2@1+ (1,0) [0|3] "" Vector__XXX
 SG_ Module31OperationalStatus : 60|2@1+ (1,0) [0|3] "" Vector__XXX
 SG_ Module30OperationalStatus : 58|2@1+ (1,0) [0|3] "" Vector__XXX
 SG_ Module29OperationalStatus : 56|2@1+ (1,0) [0|3] "" Vector__XXX
 SG_ Module28OperationalStatus : 54|2@1+ (1,0) [0|3] "" Vector__XXX
 SG_ Module27OperationalStatus : 52|2@1+ (1,0) [0|3] "" Vector__XXX
 SG_ Module26OperationalStatus : 50|2@1+ (1,0) [0|3] "" Vector__XXX
 SG_ Module25OperationalStatus : 48|2@1+ (1,0) [0|3] "" Vector__XXX
 SG_ Module24OperationalStatus : 46|2@1+ (1,0) [0|3] "" Vector__XXX
 SG_ Module23OperationalStatus : 44|2@1+ (1,0) [0|3] "" Vector__XXX
 SG_ Module22OperationalStatus : 42|2@1+ (1,0) [0|3] "" Vector__XXX
 SG_ Module21OperationalStatus : 40|2@1+ (1,0) [0|3] "" Vector__XXX
 SG_ Module20OperationalStatus : 38|2@1+ (1,0) [0|3] "" Vector__XXX
 SG_ Module19OperationalStatus : 36|2@1+ (1,0) [0|3] "" Vector__XXX
 SG_ Module18OperationalStatus : 34|2@1+ (1,0) [0|3] "" Vector__XXX
 SG_ Module17OperationalStatus : 32|2@1+ (1,0) [0|3] "" Vector__XXX
 SG_ Module16OperationalStatus : 30|2@1+ (1,0) [0|3] "" Vector__XXX
 SG_ Module15OperationalStatus : 28|2@1+ (1,0) [0|3] "" Vector__XXX
 SG_ Module14OperationalStatus : 26|2@1+ (1,0) [0|3] "" Vector__XXX
 SG_ Module13OperationalStatus : 24|2@1+ (1,0) [0|3] "" Vector__XXX
 SG_ Module12OperationalStatus : 22|2@1+ (1,0) [0|3] "" Vector__XXX
 SG_ Module11OperationalStatus : 20|2@1+ (1,0) [0|3] "" Vector__XXX
 SG_ Module10OperationalStatus : 18|2@1+ (1,0) [0|3] "" Vector__XXX
 SG_ Module9OperationalStatus : 16|2@1+ (1,0) [0|3] "" Vector__XXX
 SG_ Module8OperationalStatus : 14|2@1+ (1,0) [0|3] "" Vector__XXX
 SG_ Module7OperationalStatus : 12|2@1+ (1,0) [0|3] "" Vector__XXX
 SG_ Module6OperationalStatus : 10|2@1+ (1,0) [0|3] "" Vector__XXX
 SG_ Module5OperationalStatus : 8|2@1+ (1,0) [0|3] "" Vector__XXX
 SG_ Module4OperationalStatus : 6|2@1+ (1,0) [0|3] "" Vector__XXX
 SG_ Module3OperationalStatus : 4|2@1+ (1,0) [0|3] "" Vector__XXX
 SG_ Module2OperationalStatus : 2|2@1+ (1,0) [0|3] "" Vector__XXX
 SG_ Module1OperationalStatus : 0|2@1+ (1,0) [0|3] "" Vector__XXX

BO_ 2364688894 HVESP10D7: 8 Vector__XXX
 SG_ MaxChargeVLmt : 48|16@1+ (0.05,0) [0|3212.75] "V" Vector__XXX
 SG_ ChargeEnergyCapacity : 24|24@1+ (0.001,0) [0|16449.535] "kWh" Vector__XXX
 SG_ DisEnergyCapacity : 0|24@1+ (0.001,0) [0|16449.535] "kWh" Vector__XXX

CM_ BO_ 2349858558 "High Voltage Energy Storage Pack 11 Control 1
Control commands to be sent to High Voltage Energy Storage Pack 11.";
CM_ SG_ 2349858558 Ctrl1CRC "The CRC is defined as follows:
• Length: 8 bits
• Polynomial: x^8+x^5+x^3+x^2+x+1
• Initial Value: FFh
• Input Data Reflection: Not reflected
• Result Data Reflection: Not reflected
• XOR value: FFh
SAE makes no claim of the functional safety ...";
CM_ SG_ 2349858558 Ctrl1Counter "The message counter is used to detect situations where the transmitting ECU malfunction repeats the same frame all the time. The receiver of the information may use the counter parameter to detect this situation. The transmitting device will ...";
CM_ SG_ 2349858558 ThermalMnmgtMaintenanceReq "Request to engage Thermal Management Maintenance Mode for this High Voltage Energy Storage System Pack instance.
00b = HVESS Thermal Management Maintenance Mode is not requested
01b = HVESS Thermal Management Maintenance Mode is requested
10b = ...";
CM_ SG_ 2349858558 HVBusLowSideResistorConnectReq "This parameter is used to request connection of this HVES instance High-Voltage bus low side resistor in order to perform an isolation test. See also SPN 15276 (HVESP11 High-Voltage Bus High Side Resistor Connect Request).
This parameter is for one ...";
CM_ SG_ 2349858558 HVBusHiSideResistorConnectReq "This parameter is used to request connection of this HVES instance High-Voltage bus high side resistor in order to perform an isolation test. See also SPN 15277 (HVESP11 High-Voltage Bus Low Side Resistor Connect Request).
This parameter is for one ...";
CM_ SG_ 2349858558 OpConsent "This parameter provides an indication to this High Voltage Energy Storage Pack instance that an external device is ready for this HVES instance to proceed with normal operation.  In applications which support this parameter, the HVES instance may ...";
CM_ SG_ 2349858558 EnableInternalChargerCmd "When the HVES has an internal charger this parameter will enable it.   External chargers may use the External Energy Source Connection Demand (SPN 7890) and related SPs.
This parameter is for one of multiple packs in an HVESS.  If there is only one ...";
CM_ SG_ 2349858558 CellBalancingCmd "Command for this High Voltage Energy Storage Pack instance to perform cell balancing.
This parameter is for one of multiple packs in an HVESS.  If there is only one pack in the system, the HVESS parameters should be used. If there are multiple ...";
CM_ SG_ 2349858558 HVBusPassiveIsolTestCmd "Command for this High Voltage Energy Storage Pack instance to perform a passive electrical isolation test on the high voltage bus.
A passive isolation test uses additional circuitry (e.g. a high impedance network) to monitor the delta between the ...";
CM_ SG_ 2349858558 HVBusActiveIsolTestCmd "Command for this High Voltage Energy Storage Pack instance to perform an active electrical isolation test on the high voltage bus.
An active isolation test might use a generated signal (e.g. an injected AC signal) and then monitor changes in the ...";
CM_ SG_ 2349858558 PwrDownCmd "Command to shut down this High Voltage Energy Storage Pack instance.  A normal power-down may involve steps that take some period of time (tests, writing of data, etc.).  However, an emergency power-down should shut down the storage system as ...";
CM_ SG_ 2349858558 HVBusConnectCmd "Command to connect this High Voltage Energy Storage Pack instance to the high-voltage bus.  The emergency contactor closure request may be used in situations where one or more faults in the hybrid powertrain prevent normal operation, but the vehicle ...";
CM_ SG_ 2148466430 InvertedPF "Inverted PDU Format of SDM";
CM_ SG_ 2148466430 InvertedPS "Inverted PDU Specific of SDM";
CM_ SG_ 2148466430 InvertedSA "Inverted Source Address of SDM";
CM_ SG_ 2148466430 InvertedEDP "Inverted Extended Data Page of SDM";
CM_ SG_ 2148466430 InvertedDP "Inverted Data Page of SDM";
CM_ SG_ 2148466430 CRCofSdmData "32-bit CRC of the data field of SDM";
CM_ SG_ 2148466430 SequenceNumberOfSDG "Sequence Number of Safety Data Group";
CM_ BO_ 2365254910 "Object Detection Message #2/19
Contains information on the first lane detected on the right side of the vehicle longitudinal central axis.
";
CM_ BO_ 2365254654 "Object Detection Message #2/20
Contains information on the first lane detected on the right side of the vehicle longitudinal central axis.";
CM_ BO_ 2365254398 "Object Detection Message #2/19
Contains information on the first lane detected on the left side of the vehicle longitudinal central axis";
CM_ BO_ 2365254142 "Object Detection Message #2/18
Contains information on the first lane detected on the left side of the vehicle longitudinal central axis";
CM_ BO_ 2365253886 "Object Detection Message #2/17
The towed vehicle provides information regarding its geometry and the coverage of the observed area
";
CM_ BO_ 2231035902 "Object Detection Message #2/16
Towed vehicle velocity information message for object #8";
CM_ BO_ 2231035646 "Object Detection Message #2/15
Towed vehicle position information message for object #8";
CM_ BO_ 2231035390 "Object Detection Message #2/14
Towed vehicle velocity information message for object #7";
CM_ BO_ 2231034878 "Object Detection Message #2/12
Towed vehicle velocity information message for object #6";
CM_ BO_ 2231035134 "Object Detection Message #2/13
Towed vehicle position information message for object #7";
CM_ BO_ 2231034622 "Object Detection Message #2/11
Towed vehicle position information message for object #6";
CM_ BO_ 2231034366 "Object Detection Message #2/10
Towed vehicle velocity information message for object #5";
CM_ BO_ 2231034110 "Object Detection Message #2/9
Towed vehicle position information message for object #5";
CM_ BO_ 2231033854 "Object Detection Message #2/8
Towed vehicle velocity information message for object #4";
CM_ BO_ 2231033598 "Object Detection Message #2/7
Towed vehicle position information message for object #4";
CM_ BO_ 2231033342 "Object Detection Message #2/6
Towed vehicle velocity information message for object #3";
CM_ BO_ 2231033086 "Object Detection Message #2/5
Towed vehicle position information message for object #3";
CM_ BO_ 2231032830 "Object Detection Message #2/4
Towed vehicle velocity information message for object #2";
CM_ BO_ 2231032574 "Object Detection Message #2/3
Towed vehicle position information message for object #2";
CM_ BO_ 2231032318 "Object Detection Message #2/2
Towed vehicle velocity information message for object #1";
CM_ BO_ 2231032062 "Object Detection Message #2/1
Towed vehicle position information message for object #1
";
CM_ BO_ 2566575870 "EVSE Status 1
This message is sent by the CA that manages the connection to Electric Vehicle Supply Equipment (EVSE).

This PG is related to the physical connection and is generic to all types of EVSE (AC or DC).";
CM_ SG_ 2566575870 CommunicationsPhysicalLayer "Type of communications established with the EVSE.
0000b = Protocol yet to be determined
0001b = Control Pilot PWM (e.g. as used by single phase AC systems)
0010b = LIN Bus (e.g. as used by 3-phase systems supporting J3068)
0011b = PLC comms ...";
CM_ SG_ 2566575870 ConnType "Indicates the type of the connected EVSE.
If the CA only supports one type of EVSE this SP may be statically set to the appropriate value.  For systems that support multiple concurrently active connections this SP must be used instead of SPN 13154 ...";
CM_ SG_ 2566575870 InletSt "Overall state for this EVSE power connection.
For systems that support multiple concurrently active power connections, this SP shall be used instead of SPN 7890 in PGN 32768 (HSC1).
Validating: Indicates that there is a new connection and the EVCC ...";
CM_ SG_ 2566575870 InletContactorSt "The state of the contactors fitted to this power inlet.
If the EVCC controls contactors fitted to its associated power inlet then this SP shall report their state.
00b = Contactor Open
01b = Contactor Closed
10b = Error - Contactor fault ...";
CM_ SG_ 2566575870 ConnectorLockPermission "Indicates whether the connector lock is currently able to be controlled by EVSE Connector Lock Request, SPN 12864.
This SP should be used in conjunction with the EVSE Connector Lock State, SPN 12863.
Some charging standards mandate that the ...";
CM_ SG_ 2566575870 ConnectorLockSt "Indicates the state of this EVSE Connector Lock (if present).
000b = Unlocked
001b = Locked
010b = In transition to/from Locked
011b = Reserved
100b = Reserved
101b = No locking mechanism is available on this vehicle
110b = Error
111b = Not ...";
CM_ SG_ 2566575870 ManualOvrd "Indicates the state of a manual override switch on the vehicle, if present. The switch may be used to disable charging and unlock the the connector.

00b = Manual override not active
01b = Manual override active
10b = Error
11b = Not available";
CM_ SG_ 2566575870 ConnectorReleaseLatch "Indicates the Release Latch status of this EVSE Connector.
SAE J1772 and IEC-61851-1 describes a momentary push-to-break switch (S3) that will be opened when the Release Latch is operated prior to removal of the connector.
00b = Latch released (S3 ...";
CM_ BO_ 2566575614 "EVSE AC Status 1
This message is sent by a CA that manages the connection to an AC Electric Vehicle Supply Equipment (EVSE).
The on-change transmission of this message is only needed for SP changes that require a time critical response.  For ...";
CM_ SG_ 2566575614 ACRMSCurLmtNeutral "Maximum AC RMS current that can carried on the neutral connection from the EVSE.

If this parameter is set to 0 A then only symmetrical 3-phase operation is allowed.";
CM_ SG_ 2566575614 ACRMSCurLmtL3 "Maximum AC RMS current that can be supplied by the EVSE on L3 of a 3-phase AC supply.";
CM_ SG_ 2566575614 ACRMSCurLmtL2 "Maximum AC RMS current that can be supplied by the EVSE on L2 of a 3-phase AC supply.";
CM_ SG_ 2566575614 ACRMSCurLmtL1 "Maximum AC RMS current that can be supplied by the EVSE on a single phase AC supply or L1 of a 3-phase AC supply.";
CM_ BO_ 2566575358 "EVSE AC Status 2
This message contains diagnostic information about power supplied from the EVSE.";
CM_ SG_ 2566575358 RMSV "AC RMS Voltage of this connected EVSE supply.";
CM_ SG_ 2566575358 RMSCur "AC RMS current being drawn from the EVSE.

Negative values indicate power being drained from the vehicle and returned to the grid.";
CM_ BO_ 2566575102 "Automated Driving System Control 1
Sent by the controller application which desires to affect the automated driving system functionality.";
CM_ SG_ 2566575102 CRC "The CRC is defined as follows:
• Length: 8 bits
• Polynomial: x^8+x^5+x^3+x^2+x+1
• Initial Value: FFh
• Input Data Reflection: Not reflected
• Result Data Reflection: Not reflected
• XOR value: FFh
SAE makes no claim of the functional safety ...";
CM_ SG_ 2566575102 Counter "The message counter is used to detect situations where the transmitting ECU malfunction repeats the same frame all the time. The receiver of the information may use the counter parameter to detect this situation. The transmitting device will ...";
CM_ SG_ 2566575102 EmbeddedIntegritySupport "Indicates that SPN 22267 (ADSC1 CRC) and SPN 22266 (ADSC1 Counter) are supported by the sender.
00b = ADSC1 embedded CRC and Counter are supported by the sender
01b = ADSC1 protection is supported using J1939-76 SHM
10b = Reserved
11b = ADSC2 ...";
CM_ SG_ 2566575102 VSCtrlConsent "Indicates the consent for ADS Vehicle Speed Control Command (SPN 15248) of the automated driving system (ADS)
Devices shall not send ADS Vehicle Speed Control Command when ADS Vehicle Speed Control Consent (SPN 15247) is received as 00b. ADS ...";
CM_ SG_ 2566575102 TSC1CtrlPurpP7InhCmd "Signal which indicates sending TSC1 Control Purpose P7 is inhibited or not.
Devices shall not send TSC1 Control Purpose P7 when the received SPN 12868 (TSC1 Control Purpose P7 Inhibit Command) is 01b. If those devices send TSC1 Control Purpose P7 ...";
CM_ BO_ 2566574846 "Turbocharger Information 9
Turbocharger information";
CM_ SG_ 2566574846 EngTC6OilTemp "Temperature of the lubricant for the sixth turbocharger.";
CM_ SG_ 2566574846 EngTC5OilTemp "Temperature of the lubricant for the fifth turbocharger.";
CM_ SG_ 2566574846 EngTC4OilTemp "Temperature of the lubricant for the fourth turbocharger.";
CM_ SG_ 2566574846 EngTC3OilTemp "Temperature of the lubricant for the third turbocharger.";
CM_ BO_ 2499465726 "Engine Average Information 2
Reports averaged engine information";
CM_ SG_ 2499465726 CylBank2TempAvg "The calculated average temperature based upon all of the Bank 2 (right bank) engine cylinders measured at the head of each cylinder. This is the average temperature measurement of each of the engine cylinders on the left bank.
Note: Use SPN 4152 - ...";
CM_ SG_ 2499465726 CylBank1TempAvg "The calculated average temperature based upon all of the Bank 1 (left bank) engine cylinders measured at the head of each cylinder. This is the average temperature measurement of each of the engine cylinders on the left bank.
Note: Use SPN 4153 - ...";
CM_ SG_ 2499465726 CylTempAvg "The calculated average temperature based upon all of the engine cylinder temperatures measured at the head of each cylinder. This is the average temperature based upon the measurements in each of the engine cylinders.
Note: Use SPN 4151 - Engine ...";
CM_ BO_ 2499465470 "Cab Door Control 2
This message requests or commands the cabin door functionality; door latches, windows, and mirrors. Doors are numbered left to right, front to back.";
CM_ SG_ 2499465470 MirrorPrimary_SecondarySelection "Indicates the position of a switch that selects between primary and secondary mirror sets. Signal may be used to provide visual indication of selected mirror.
000b = No Mirror Selected (Neutral Position)
001b = Primary Mirror Set Selected
010b = ...";
CM_ SG_ 2499465470 Mirror2Left_RightSelection "Indicates the position of a switch that selects between left or right mirror control. Signal may be used to provide visual indication of selected mirror.
000b = No Mirror Selected (Neutral Position)
001b = Mirror 2 Left Selected
010b = Mirror 2 ...";
CM_ SG_ 2499465470 Mirror1Left_RightSelection "Indicates the position of a switch that selects between left or right mirror control. Signal may be used to provide visual indication of selected mirror.
000b = No Mirror Selected (Neutral Position)
001b = Mirror 1 Left Selected
010b = Mirror 1 ...";
CM_ BO_ 2566574078 "EVCC Diagnostic Data 1
Reports this EVCC internal parameters for diagnostic purposes.";
CM_ SG_ 2566574078 CompatibilityCode "Indicates incompatability between the vehicle and the EVSE.
0000b = EVSE is compatible
0001b = Digital Communications. The EVSE has attempted to establish commuications but the protocol is not supported by the EVCC.
0010b = Ventilation. The EVSE ...";
CM_ SG_ 2566574078 InletConnectorTemp "Temperature reading at the vehicle inlet connector.";
CM_ SG_ 2566574078 ProximityCircV "The cable from the EVSE may contain a resistive proximity circuit.  Resistors are built into both the cable and inlet sides of the connectors and are supplied from a DC source.
The voltage interpretation will depend on the connection standard in ...";
CM_ SG_ 2566574078 CtrlPilotSubSt "Indicates the EVSE sub-state as determined by the frequency of the Control Pilot as defined by IEC-61851 and J1772.
0000b = Sub-state 1 - DC Level, EVSE not ready/able to enable power
0001b = Sub-state 2 - Valid PWM, EVSE Ready to supply power
 ...";
CM_ SG_ 2566574078 CtrlPilotSt "Indicates the EVSE state as determined by the peak voltage level of the Control Pilot and representing states A to F as defined by IEC-61851 and J1772.
0000b = State A, EVSE Disconnected
0001b = State B, EVSE Connected, Power Disabled
0010b = ...";
CM_ SG_ 2566574078 CtrlPilotDutyCycle "The control pilot from the off-board EVSE is either a DC signal or a square wave. This parameter contains the duty cycle of the PWM square wave.";
CM_ SG_ 2566574078 CtrlPilotPWMFreq "The control pilot from the off-board EVSE is either a DC signal or a square wave. This parameter contains either zero when a DC value or the frequency when a square wave.";
CM_ SG_ 2566574078 CtrlPilotMinV "The control pilot from the off-board EVSE is either a DC signal or a square wave. This parameter contains the DC value or the minimum voltage of the square wave.";
CM_ SG_ 2566574078 CtrlPilotMaxV "The control pilot from the off-board EVSE is either a DC signal or a square wave. This parameter contains the DC value or the maximum voltage of the square wave.";
CM_ BO_ 2566573822 "PTO Information 2
Information relating to PTO systems.";
CM_ SG_ 2566573822 TransPTOGearboxStatus "Feedback from the PTO gearbox driven by the transmission PTO.
0000b = Neutral
0001b = 1st range, or \"Low\" in a 2-speed gearbox
0010b = 2nd range, or \"High\" in a 2-speed gearbox
0011b = 3rd range
0100b = 4th range
0101b = Reserved
0110b = ...";
CM_ SG_ 2566573822 TransPTOGearboxOSS "Output shaft speed of a PTO gearbox driven by the transmission PTO.";
CM_ BO_ 2499464702 "Aftertreatment 1 SCR Exhaust Gas Pressures 2
This message contains SCR catalyst exhaust gas pressure information for aftertreatment system 1 (or bank 1).";
CM_ SG_ 2499464702 OutPress "The gage pressure at the outlet of the selective catalytic reduction system of Aftertreatment 1.";
CM_ SG_ 2499464702 OutAbsPress "The pressure at the catalyst outlet of the selective catalytic reduction system of aftertreatment 1.";
CM_ BO_ 2566572286 "Electronic Transmission Controller 14
Electronic Transmission Controller 14";
CM_ SG_ 2566572286 DamageThresholdSt "Indicates whether the transmission has exceeded a damage threshold. This information may be important to an Automated Driving System (ADS) so that it can determine its plan of action, e.g. limit an extreme operating condition or find a safe place to ...";
CM_ SG_ 2566572286 GearShiftCapability "Indicates whether the transmission has the operational capability to shift gears when the vehicle is moving. The capability may be degraded due to a component failure (e.g. failed clutch mechanism or hydraulic solenoid) or a temporary fault ...";
CM_ SG_ 2566572286 LaunchCapability "Indicates whether the transmission has the current operational capability to launch the vehicle from stationary. The capability may be degraded due to a component failure or temporary fault condition (such as low air pressure due to a high usage ...";
CM_ SG_ 2566572286 Clutch1OverheatInd "Signal used to indicate the transmission clutch 1 temperature is above normal acceptable limits.  Transmission clutch 1 is typically the primary transmission input clutch.
00b = Clutch overheat indicator is off
01b = Clutch overheat indicator is ...";
CM_ SG_ 2566572286 Clutch1Temp "Indicates temperature of the transmission clutch 1. This is typically the primary transmission input clutch.";
CM_ BO_ 2566572030 "Downhill Speed Control 1
System integrators must exercise caution to avoid control conflicts with existing cruise control systems that may already incorporate downhill speed control logic. For example a system integrator might choose to only allow ...";
CM_ BO_ 2499462910 "Electronic Retarder Controller 3
This message will be transmitted by several types of retarding devices such as engine compression release brakes, exhaust system restriction brakes, and driveline retarders using hydraulic, electric, or mechanical ...";
CM_ SG_ 2499462910 RoadSpdAccelerateSw "Switch signal of the retarder road speed activator which indicates that the activator is in the position \"accelerate\".
00b = Retarder road speed activator not in the position \"accelerate\"
01b = Retarder road speed activator in position ...";
CM_ SG_ 2499462910 RoadSpdDecelerateSw "Switch signal of the retarder road speed activator which indicates that the activator is in the position \"decelerate\".
00b = Retarder road speed activator not in the position \"decelerate\"
01b = Retarder road speed activator in position ...";
CM_ BO_ 2566571518 "EVSE AC 3-Phase Load
This message from an HVESS Charger that is connected to 3-Phase AC Electric Vehicle Supply (EVSE) 1.";
CM_ SG_ 2566571518 HVESSChargerNeutralRMSCur "Current flowing through the neutral connection.
For a balanced 3-phase load this value will be set to 0 A.
If the HVESS charger is only drawing single phase current between L1 and neutral then this parameter will have the same value as SPN 13009 ...";
CM_ SG_ 2566571518 HVESSChargerRMSCurL3 "Current presently being drawn from L3 of a three phase supply.";
CM_ SG_ 2566571518 HVESSChargerRMSCurL2 "Current presently being drawn from L2 of a three phase supply.";
CM_ SG_ 2566571518 HVESSChargerRMSCurL1 "Current presently being drawn from a single phase EVSE or from L1 of a three phase supply.";
CM_ BO_ 2566571262 "EVSE AC Supply Voltage
This message is sent by a CA that manages the connection to 3-phase AC Electric Vehicle Supply Equipment (EVSE).";
CM_ SG_ 2566571262 NomSupplyFreq "Indicates the supply frequency.

00h = 50 Hz
02h = 60 Hz
03h - FDh = Reserved
FEh = Error
FFh = Not available";
CM_ SG_ 2566571262 NomRMSVLineToLine "Indicates the nominal line to line RMS voltage.  For single phase supplies this is set to Not Available.";
CM_ SG_ 2566571262 NomRMSVLineToNeutral "Indicates the nominal RMS voltage between contacts L1 and Neutral.

For 3-phase supplies the same nominal line to neutral voltage is assumed for L2 and L3";
CM_ BO_ 2566571006 "Air Supply Pressure 3
Includes information related to the air supply parameters.";
CM_ SG_ 2566571006 SuspensionSupplyPress2 "The pneumatic pressure in the second circuit for the electronically controlled air suspension system.";
CM_ SG_ 2566571006 DryerCartridgeLifeRemaining "The air dryer cartridge life remaining based on compressor air processed through the desiccant material.  100% life remaining indicates a new or fresh air dryer cartridge and 0% life remaining indicates a worn air dryer cartridge that should be ...";
CM_ BO_ 2566570750 "Motor/Generator 6 Lifetime Data
Contains data accumulated over the lifetime of this Motor/Generator.";
CM_ SG_ 2566570750 TotalChargeGenerated "Indicates the total lifetime charge generated by this Motor/Generator.  For example, this would include the charge created during regerative braking in a propulsion motor.";
CM_ SG_ 2566570750 TotalChargeConsumed "Indicates the total lifetime charge consumed by this Motor/Generator.  For example, this would include the charge used for propulsion in a propulsion motor.";
CM_ SG_ 2566570750 TotalEnergyGenerated "Indicates the total lifetime energy generated by this Motor/Generator.  For example, this would include the energy created during regerative braking in a propulsion motor.";
CM_ SG_ 2566570750 TotalEnergyConsumed "Indicates the total lifetime energy consumed by this Motor/Generator.  For example, this would include the energy used for propulsion in a propulsion motor.";
CM_ BO_ 2566570494 "Motor/Generator 5 Lifetime Data
Contains data accumulated over the lifetime of this Motor/Generator.";
CM_ SG_ 2566570494 TotalChargeGenerated "Indicates the total lifetime charge generated by this Motor/Generator.  For example, this would include the charge created during regerative braking in a propulsion motor.";
CM_ SG_ 2566570494 TotalChargeConsumed "Indicates the total lifetime charge consumed by this Motor/Generator.  For example, this would include the charge used for propulsion in a propulsion motor.";
CM_ SG_ 2566570494 TotalEnergyGenerated "Indicates the total lifetime energy generated by this Motor/Generator.  For example, this would include the energy created during regerative braking in a propulsion motor.";
CM_ SG_ 2566570494 TotalEnergyConsumed "Indicates the total lifetime energy consumed by this Motor/Generator.  For example, this would include the energy used for propulsion in a propulsion motor.";
CM_ BO_ 2566570238 "Motor/Generator 4 Lifetime Data
Contains data accumulated over the lifetime of this Motor/Generator.";
CM_ SG_ 2566570238 TotalChargeGenerated "Indicates the total lifetime charge generated by this Motor/Generator.  For example, this would include the charge created during regerative braking in a propulsion motor.";
CM_ SG_ 2566570238 TotalChargeConsumed "Indicates the total lifetime charge consumed by this Motor/Generator.  For example, this would include the charge used for propulsion in a propulsion motor.";
CM_ SG_ 2566570238 TotalEnergyGenerated "Indicates the total lifetime energy generated by this Motor/Generator.  For example, this would include the energy created during regerative braking in a propulsion motor.";
CM_ SG_ 2566570238 TotalEnergyConsumed "Indicates the total lifetime energy consumed by this Motor/Generator.  For example, this would include the energy used for propulsion in a propulsion motor.";
CM_ BO_ 2566569982 "Motor/Generator 3 Lifetime Data
Contains data accumulated over the lifetime of this Motor/Generator.";
CM_ SG_ 2566569982 TotalChargeGenerated "Indicates the total lifetime charge generated by this Motor/Generator.  For example, this would include the charge created during regerative braking in a propulsion motor.";
CM_ SG_ 2566569982 TotalChargeConsumed "Indicates the total lifetime charge consumed by this Motor/Generator.  For example, this would include the charge used for propulsion in a propulsion motor.";
CM_ SG_ 2566569982 TotalEnergyGenerated "Indicates the total lifetime energy generated by this Motor/Generator.  For example, this would include the energy created during regerative braking in a propulsion motor.";
CM_ SG_ 2566569982 TotalEnergyConsumed "Indicates the total lifetime energy consumed by this Motor/Generator.  For example, this would include the energy used for propulsion in a propulsion motor.";
CM_ BO_ 2566569726 "Motor/Generator 2 Lifetime Data
Contains data accumulated over the lifetime of this Motor/Generator.";
CM_ SG_ 2566569726 TotalChargeGenerated "Indicates the total lifetime charge generated by this Motor/Generator.  For example, this would include the charge created during regerative braking in a propulsion motor.";
CM_ SG_ 2566569726 TotalChargeConsumed "Indicates the total lifetime charge consumed by this Motor/Generator.  For example, this would include the charge used for propulsion in a propulsion motor.";
CM_ SG_ 2566569726 TotalEnergyGenerated "Indicates the total lifetime energy generated by this Motor/Generator.  For example, this would include the energy created during regerative braking in a propulsion motor.";
CM_ SG_ 2566569726 TotalEnergyConsumed "Indicates the total lifetime energy consumed by this Motor/Generator.  For example, this would include the energy used for propulsion in a propulsion motor.";
CM_ BO_ 2566569470 "Motor/Generator 1 Lifetime Data
Contains data accumulated over the lifetime of this Motor/Generator.";
CM_ SG_ 2566569470 TotalChargeGenerated "Indicates the total lifetime charge generated by this Motor/Generator.  For example, this would include the charge created during regerative braking in a propulsion motor.";
CM_ SG_ 2566569470 TotalChargeConsumed "Indicates the total lifetime charge consumed by this Motor/Generator.  For example, this would include the charge used for propulsion in a propulsion motor.";
CM_ SG_ 2566569470 TotalEnergyGenerated "Indicates the total lifetime energy generated by this Motor/Generator.  For example, this would include the energy created during regerative braking in a propulsion motor.";
CM_ SG_ 2566569470 TotalEnergyConsumed "Indicates the total lifetime energy consumed by this Motor/Generator.  For example, this would include the energy used for propulsion in a propulsion motor.";
CM_ BO_ 2566569214 "Direct Lamp Control Data 3
This message will be transmitted by the controller that is illuminating the lamps. 

It is not required to be used with PGN 64774.";
CM_ SG_ 2566569214 TransOilPressLowLamp "This parameter provides measured data from the Transmission Oil Pressure Lamp.

00b = Lamp deactivated (Off)
01b = Lamp activated (On)
10b = Error
11b = Not available";
CM_ SG_ 2566569214 TransOilTempHiLamp "This parameter provides measured data from the Transmission Oil Temperature Lamp.

00b = Lamp deactivated (Off)
01b = Lamp activated (On)
10b = Error
11b = Not available";
CM_ BO_ 2566568958 "Direct Lamp Control Command 3
Message that directly controls the driver indicator lamps. See also PGNs 64775 and 64774 for additional lamps and PGN 64188 for the feedback information about these lamps.
Note: Since this message is direct lamp ...";
CM_ SG_ 2566568958 TransOilPressLowLamp "Command signal directly controlling the Transmission Oil Pressure Lamp.

00b = Lamp Off
01b = Lamp On
10b = Reserved
11b = Not available";
CM_ SG_ 2566568958 TransOilTempHiLamp "Command signal directly controlling the Transmission Oil Temperature Lamp.

00b = Lamp Off
01b = Lamp On
10b = Reserved
11b = Not available";
CM_ BO_ 2566568702 "EVSE 1 Contactor Status 1
Status of the DC Charging Inlet Contactors, which are used to isolate vehicle's internal DC bus from the EVSE Inlet Connector.
There may be multiple senders of this PG in the system. However, typically each SP will only ...";
CM_ SG_ 2566568702 HybDCInletContactor1St "Indicates the state of DC Inlet Contactor 1.

00b = Contactor Open
01b = Contactor Closed
10b = Error- Contactor fault detected
11b = Not available";
CM_ SG_ 2566568702 HybDCChargingBusV "Voltage measured on the HVES side of the DC Charging Inlet Contactors.";
CM_ SG_ 2566568702 HybDCContactorInputV "Voltage measured on the inlet side of the DC Charging Inlet Contactors. 

If provided, this value should be in agreement with SPN 13172 (EVSE Present DC Charging Voltage).";
CM_ BO_ 2566568446 "EVSE 1 Contactor Cmd 1
Command sent to control the DC Charging Inlet Contactors, which are used to isolate vehicle's internal DC bus from the EVSE Inlet Connector.";
CM_ SG_ 2566568446 HybDCInletContactor1Cmd "Contactor command.

00b = Open Contactor
01b = Close Contactor
10b = Reserved
11b = Don't Care / Take no action";
CM_ BO_ 2566568190 "EVSE DC Status 1
This message is sent from the EVCC containing status information receved from the DC EVSE.

If this PG is requested, e.g. using RQST, when no EVSE is connected then specific values or states are provided in each parameter.";
CM_ SG_ 2566568190 RespCode "The response code of the EVSE to the last request from the EV.
Typically the values are only significant once current operation progress indicates \"Finished\"
See J2847-2 201504 Sect 4.2.78
0 = OK
1 = OK New Session Established
2 = OK Old ...";
CM_ SG_ 2566568190 ProcessingSt "The progress of the EVSE within its current DC Charging State, as reported by SPN 13171.
For example, if the EVSE is doing a cable check SPN 13171 = 9, Cable check and this SP will indicate 01b, Ongoing. On completion of the cable check this SP ...";
CM_ SG_ 2566568190 IsolStatus "Isolation Status as returned from this instance of EVSE.
The EVSE checks its internal isolation during the Cable Check phase of establishing the DC connection. On completion of the cable check, the value would change from 14 to one of either 0, 1 ...";
CM_ SG_ 2566568190 Status "Status of the DC EVSE as returned from the EVSE
0 = EVSE Not Ready
1 = EVSE Ready
2 = EVSE Shutdown
3 = Utility Interrupt Event
4 = Isolation Monitoring Active
5 = Emergency Shutdown
6 = Malfunction
7 = Reserved
8 = Reserved
9 = Reserved
 ...";
CM_ SG_ 2566568190 PLAchieved "Indicates if the output power from the EVSE has reached the negotiated power limit as determined by the lower of SPN 13161 (EVSE DC Charging Power Maximum) and SPN 13157 (Hybrid DC Charging Power Maximum).
00b = Not limited or no EVSE connected - ...";
CM_ SG_ 2566568190 CurLmtAchieved "Indicates if the output current from the EVSE has reached the negotiated current limit as determined by SPN 13160 (EVSE DC Charging Current Maximum) and SPN 13156 (Hybrid DC Charging Current Maximum).
00b = Not limited or no EVSE connected - see ...";
CM_ SG_ 2566568190 VLmtAchieved "Indicates if the output voltage from the EVSE has reached the negotiated voltage limit as determined by SPN 13159 (EVSE DC Charging Voltage Maximum) and SPN 13155 (Hybrid DC Charging Voltage Maximum).
00b = Not limited or no EVSE connected - see ...";
CM_ SG_ 2566568190 PresentDCChargingCur "High Voltage DC current at the output of the EVSE as measured by the EVSE 

FB00h = Parameter supported, but no current provided by EVSE

See J2847-2 201504 Sect 4.2.51";
CM_ SG_ 2566568190 PresentDCChargingV "High Voltage DC voltage at the output of the EVSE as measured by the EVSE

FB00h = Parameter supported, but no voltage provided by EVSE

See J2847-2 201504 Sect 4.2.50";
CM_ SG_ 2566568190 ChargingSt "Overall State of the DC charging system
0 = Idle. No EVSE connected
1 = Charging
2 = Standby
3 = Reserved
4 = Power Delivery (Start-up)
5 = Authorizing.  A sub-state of Initializing that could take significant time, therefore the EVCC reports ...";
CM_ BO_ 2566567934 "EV DC Charging Target
This message is sent to the EVCC (and forwarded to the EVSE) and sets the instantaneous limits to be applied during the charge cycle.";
CM_ SG_ 2566567934 TargetChargingCur "Hybrid or Electric vehicle's instantaneous requested DC output current limit.
See also:
SPN 13160 (EVSE DC Charging Current Maximum)
SPN 13164 (EVSE DC Charging Current Minimum)
SPN 13156 (Hybrid DC Charging Current Maximum)
SPN 13169 (DC ...";
CM_ SG_ 2566567934 TargetChargingV "Hybrid or Electric vehicle's instantaneous requested DC output voltage limit.
See also:
SPN 13159 (EVSE DC Charging Voltage Maximum)
SPN 13163 (EVSE DC Charging Voltage Minimum)
SPN 13155 (Hybrid DC Charging Voltage Maximum)
SPN 13170 (DC ...";
CM_ SG_ 2566567934 SequenceCounter "The message counter is used to detect situations where the transmitting ECU malfunction repeats the same frame all the time. The receiver of the information may use the counter parameter to detect this situation. The transmitting device will ...";
CM_ SG_ 2566567934 CRC "The CRC is defined as follows:
• Length: 8 bits
• Polynomial: x^8+x^5+x^3+x^2+x+1
• Initial Value: FFh
• Input Data Reflection: Not reflected
• Result Data Reflection: Not reflected
• XOR value: FFh
SAE makes no claim of the functional safety ...";
CM_ BO_ 2566567678 "EVSE DC Charging Limits 2
This message is sent the from EVCC and reports the minimum charging limits and tolerances of a DC EVSE.";
CM_ SG_ 2566567678 CurRegulationTolerance "Regulated current tolerance of the EVSE.

FB00h = Parameter supported, but no tolerance provided by EVSE

See J2847-2 201504 Sect 4.2.38";
CM_ SG_ 2566567678 PeakCurRipple "Maximum peak to peak ripple current amplitude on the EVSE output.

FB00h = Parameter supported, but no value provided by EVSE

See J2847-2 201504 Sect 4.2.48";
CM_ SG_ 2566567678 DCChargingCurMin "Minimum stable DC output current that can be supplied by the EVSE.

FB00h = Parameter supported, but no value provided by EVSE

See J2847-2 201504 Sect 4.2.45";
CM_ SG_ 2566567678 DCChargingVMin "Minimum stable DC output voltage that can be supplied by the EVSE.

FB00h = Parameter supported, but no value provided by EVSE

See J2847-2 201504 Sect 4.2.46";
CM_ BO_ 2566567422 "EVSE DC Charging Limits 1
Data from the EVCC that reports the maximum charging limits of a DC EVSE.

If this PG is requested, e.g. using RQST, when no EVSE is connected then specific values or states are provided in each parameter.";
CM_ SG_ 2566567422 SupportedEnergyTransferTypes "Energy transfer types supported by the EVSE
0000b = DC-Extended
0001b = DC-Core
0010b = AC-Single-phase-core
0011b = AC-three-phase-core
0100b = Reserved
0101b = Reserved
0110b = Reserved
0111b = Reserved
1000b = Reserved
1001b = Reserved
 ...";
CM_ SG_ 2566567422 DCChargingPwrMax "EVSE's maximum rated DC output power.
This is communicated to the hybrid vehicle during initial exchange of parameters.
When charging, the smallest value of this and SPN 13157 (Hybrid DC Charging Power Maximum) will be used.
FB00h = Parameter ...";
CM_ SG_ 2566567422 DCChargingCurMax "EVSE's maximum rated DC output current.
This is communicated to the hybrid vehicle during initial exchange of parameters.
When charging, the smallest value of this and SPN 13156 (Hybrid DC Charging Current Maximum) will be used.
FB00h = Parameter ...";
CM_ SG_ 2566567422 DCChargingVMax "EVSE's maximum rated DC output voltage.
This is communicated to the hybrid vehicle during initial exchange of parameters.
When charging, the smallest value of this and SPN 13155 (Hybrid DC Charging Voltage Maximum) will be used.
FB00h = Parameter ...";
CM_ BO_ 2566567166 "EV DC Charging Limits 1
Data used by the EVCC when negotiating charging limits with an EVSE that supports DC charging.
This data is sent to the EVSE on initial connection and may be dynamically updated during charging.  The original implementation ...";
CM_ SG_ 2566567166 HybReqEnergyTransferType "Hybrid  or Electric vehicle's required Energy transfer type
0000b = DC-Extended
0001b = DC-Core
0010b = Reserved
0011b = Reserved
0100b = Reserved
0101b = Reserved
0110b = Reserved
0111b = Reserved
1000b = Reserved
1001b = Reserved
1010b ...";
CM_ SG_ 2566567166 HybDCChargingPwrMax "Hybrid or Electric Vehicle's maximum rated DC charging input power.
This is communicated to a DC EVSE during initial exchange of parameters and may optionally be dynamically updated during charging.
When charging, the smallest value of this and ...";
CM_ SG_ 2566567166 HybDCChargingCurMax "Hybrid or Electric Vehicle's maximum rated DC charging input current.
This is communicated to a DC EVSE during initial exchange of parameters and may optionally be dynamically updated during charging.
When charging, the smallest value of this and ...";
CM_ SG_ 2566567166 HybDCChargingVMax "Hybrid or Electric Vehicle's maximum allowed DC charging input voltage.
This is communicated to a DC EVSE during initial exchange of parameters and may optionally be dynamically updated during charging.
When charging, the smallest value of this ...";
CM_ BO_ 2566566910 "AUTOSAR Time Syncronization
Message used to implement on J1939 the AUTOSAR CanTSyn of the AUTOSAR Time Synchronization over CAN protocol.
At the time of assignment, the AUTOSAR Time Synchronization over CAN reference was \"AUTOSAR Time ...";
CM_ BO_ 2633675518 "High Voltage Energy Storage Pack 7 History
Historical data for High Voltage Energy Storage Pack 7.";
CM_ SG_ 2633675518 TotalEnergyOut "The cumulative energy which has flowed out of this High Voltage Energy Storage Pack instance over the lifetime of the battery pack. This parameter is the sum of the Energy out of this HVES instance. This value is reset when the pack is replaced. For ...";
CM_ SG_ 2633675518 TotalEnergyInput "The cumulative energy which has flowed into this High Voltage Energy Storage Pack instance over the lifetime of the battery pack. This parameter is the sum of the Energy into this HVES instance.
This value is reset when the pack is replaced. For ...";
CM_ SG_ 2633675518 TotalAccumulatedCharge "The total accumulated amp hours which have flowed through this High Voltage Energy Storage Pack instance.  This parameter is the sum of the absolute values of the Ampere hours into and out of this HVES instance.
This parameter is for one of ...";
CM_ SG_ 2633675518 TotalEnergyThroughput "The total energy throughput which has flowed through this High Voltage Energy Storage Pack instance.  This parameter is the sum of the absolute values of the Energy into and out of this HVES instance.
This parameter is for one of multiple packs in ...";
CM_ SG_ 2633675518 ContactorOpenUnderLoadCount "This signal represents the number of times the contactors inside this High Voltage Energy Storage Pack instance have opened while current is flowing through them.  The current level (that determines if an opening event will be counted) shall be ...";
CM_ SG_ 2633675518 StOfHealth "This signal represents the expected remaining \"Life\" of this High Voltage Energy Storage Pack instance, in percent.  Battery life is a manufacturer-specific measure of how well the energy storage system is functioning relative to its nominal (rated) ...";
CM_ BO_ 2566566398 "High Voltage Energy Storage Pack 7 Configuration
Configuration data for High Voltage Energy Storage Pack 7.  Note that configuration data should not dynamically change during vehicle operation.";
CM_ SG_ 2566566398 NomRatedCapacity "Per the HVES manufacturer, this is the manufacturer's nominal rated capacity of this instance of the energy storage system.  The rated capacity does not change over the life of the HVES.
This parameter is for one of multiple packs in an HVESS.  If ...";
CM_ SG_ 2566566398 CellMinVLmt "Per the HVES manufacturer, this is the minimum cell voltage for this High Voltage Energy Storage Pack instance operation.  Operating below this value may damage HVES hardware, or compromise HVES life.
This parameter is for one of multiple packs in ...";
CM_ SG_ 2566566398 CellMaxVLmt "Per the HVES manufacturer, this is the maximum cell voltage for this High Voltage Energy Storage Pack instance operation.  Operating above this value may damage HVES hardware, or compromise HVES life.
This parameter is for one of multiple packs in ...";
CM_ SG_ 2566566398 RecommendedMinOperatingTemp "Per the HVES manufacturer, this is the recommended minimum temperature for this High Voltage Energy Storage Pack instance operation.  Operating below this value may damage HVES hardware, or compromise HVES life.
This parameter is for one of ...";
CM_ SG_ 2566566398 RecommendedMaxOperatingTemp "Per the HVES manufacturer, this is the recommended maximum temperature for this High Voltage Energy Storage Pack instance operation.  Operating above this value may damage HVES hardware, or compromise HVES life.
This parameter is for one of ...";
CM_ SG_ 2566566398 RecommendedMaxStOfCharge "Per the HVES manufacturer, this is the recommended maximum state of charge for this High Voltage Energy Storage Pack instance operation.  Operating above this value may compromise HVES life.
This parameter is for one of multiple packs in an HVESS ...";
CM_ SG_ 2566566398 RecommendedMinStOfCharge "Per the HVES manufacturer, this is the recommended minimum state of charge for this High Voltage Energy Storage Pack instance operation.  Operating below this value may compromise HVES life.
This parameter is for one of multiple packs in an HVESS ...";
CM_ SG_ 2566566398 RecommendedMaxOperatingV "Per the HVES manufacturer, this is the maximum recommended voltage level for this High Voltage Energy Storage Pack instance operation.  Operating above this value may compromise HVES life.
This parameter is for one of multiple packs in an HVESS ...";
CM_ SG_ 2566566398 RecommendedMinOperatingV "Per the HVES manufacturer, this is the minimum recommended voltage level for this High Voltage Energy Storage Pack instance operation.  Operating below this value may compromise HVES life.
This parameter is for one of multiple packs in an HVESS ...";
CM_ SG_ 2566566398 NomV "Per the HVES manufacturer, this is the nominal operating voltage of this High Voltage Energy Storage Pack instance, e.g. “300V” or “600V”.
This parameter is for one of multiple packs in an HVESS.  If there is only one pack in the system, the HVESS ...";
CM_ BO_ 2633675006 "High Voltage Energy Storage Pack 8 History
Historical data for High Voltage Energy Storage Pack 8.";
CM_ SG_ 2633675006 TotalEnergyOut "The cumulative energy which has flowed out of this High Voltage Energy Storage Pack instance over the lifetime of the battery pack. This parameter is the sum of the Energy out of this HVES instance. This value is reset when the pack is replaced. For ...";
CM_ SG_ 2633675006 TotalEnergyInput "The cumulative energy which has flowed into this High Voltage Energy Storage Pack instance over the lifetime of the battery pack. This parameter is the sum of the Energy into this HVES instance.
This value is reset when the pack is replaced. For ...";
CM_ SG_ 2633675006 TotalAccumulatedCharge "The total accumulated amp hours which have flowed through this High Voltage Energy Storage Pack instance.  This parameter is the sum of the absolute values of the Ampere hours into and out of this HVES instance.
This parameter is for one of ...";
CM_ SG_ 2633675006 TotalEnergyThroughput "The total energy throughput which has flowed through this High Voltage Energy Storage Pack instance.  This parameter is the sum of the absolute values of the Energy into and out of this HVES instance.
This parameter is for one of multiple packs in ...";
CM_ SG_ 2633675006 ContactorOpenUnderLoadCount "This signal represents the number of times the contactors inside this High Voltage Energy Storage Pack instance have opened while current is flowing through them.  The current level (that determines if an opening event will be counted) shall be ...";
CM_ SG_ 2633675006 StOfHealth "This signal represents the expected remaining \"Life\" of this High Voltage Energy Storage Pack instance, in percent.  Battery life is a manufacturer-specific measure of how well the energy storage system is functioning relative to its nominal (rated) ...";
CM_ BO_ 2566565886 "High Voltage Energy Storage Pack 8 Configuration
Configuration data for High Voltage Energy Storage Pack 8.  Note that configuration data should not dynamically change during vehicle operation.";
CM_ SG_ 2566565886 NomRatedCapacity "Per the HVES manufacturer, this is the manufacturer's nominal rated capacity of this instance of the energy storage system.  The rated capacity does not change over the life of the HVES.
This parameter is for one of multiple packs in an HVESS.  If ...";
CM_ SG_ 2566565886 CellMinVLmt "Per the HVES manufacturer, this is the minimum cell voltage for this High Voltage Energy Storage Pack instance operation.  Operating below this value may damage HVES hardware, or compromise HVES life.
This parameter is for one of multiple packs in ...";
CM_ SG_ 2566565886 CellMaxVLmt "Per the HVES manufacturer, this is the maximum cell voltage for this High Voltage Energy Storage Pack instance operation.  Operating above this value may damage HVES hardware, or compromise HVES life.
This parameter is for one of multiple packs in ...";
CM_ SG_ 2566565886 RecommendedMinOperatingTemp "Per the HVES manufacturer, this is the recommended minimum temperature for this High Voltage Energy Storage Pack instance operation.  Operating below this value may damage HVES hardware, or compromise HVES life.
This parameter is for one of ...";
CM_ SG_ 2566565886 RecommendedMaxOperatingTemp "Per the HVES manufacturer, this is the recommended maximum temperature for this High Voltage Energy Storage Pack instance operation.  Operating above this value may damage HVES hardware, or compromise HVES life.
This parameter is for one of ...";
CM_ SG_ 2566565886 RecommendedMaxStOfCharge "Per the HVES manufacturer, this is the recommended maximum state of charge for this High Voltage Energy Storage Pack instance operation.  Operating above this value may compromise HVES life.
This parameter is for one of multiple packs in an HVESS ...";
CM_ SG_ 2566565886 RecommendedMinStOfCharge "Per the HVES manufacturer, this is the recommended minimum state of charge for this High Voltage Energy Storage Pack instance operation.  Operating below this value may compromise HVES life.
This parameter is for one of multiple packs in an HVESS ...";
CM_ SG_ 2566565886 RecommendedMaxOperatingV "Per the HVES manufacturer, this is the maximum recommended voltage level for this High Voltage Energy Storage Pack instance operation.  Operating above this value may compromise HVES life.
This parameter is for one of multiple packs in an HVESS ...";
CM_ SG_ 2566565886 RecommendedMinOperatingV "Per the HVES manufacturer, this is the minimum recommended voltage level for this High Voltage Energy Storage Pack instance operation.  Operating below this value may compromise HVES life.
This parameter is for one of multiple packs in an HVESS ...";
CM_ SG_ 2566565886 NomV "Per the HVES manufacturer, this is the nominal operating voltage of this High Voltage Energy Storage Pack instance, e.g. “300V” or “600V”.
This parameter is for one of multiple packs in an HVESS.  If there is only one pack in the system, the HVESS ...";
CM_ BO_ 2633674494 "High Voltage Energy Storage Pack 9 History
Historical data for High Voltage Energy Storage Pack 9.";
CM_ SG_ 2633674494 TotalEnergyOut "The cumulative energy which has flowed out of this High Voltage Energy Storage Pack instance over the lifetime of the battery pack. This parameter is the sum of the Energy out of this HVES instance. This value is reset when the pack is replaced. For ...";
CM_ SG_ 2633674494 TotalEnergyInput "The cumulative energy which has flowed into this High Voltage Energy Storage Pack instance over the lifetime of the battery pack. This parameter is the sum of the Energy into this HVES instance.
This value is reset when the pack is replaced. For ...";
CM_ SG_ 2633674494 TotalAccumulatedCharge "The total accumulated amp hours which have flowed through this High Voltage Energy Storage Pack instance.  This parameter is the sum of the absolute values of the Ampere hours into and out of this HVES instance.
This parameter is for one of ...";
CM_ SG_ 2633674494 TotalEnergyThroughput "The total energy throughput which has flowed through this High Voltage Energy Storage Pack instance.  This parameter is the sum of the absolute values of the Energy into and out of this HVES instance.
This parameter is for one of multiple packs in ...";
CM_ SG_ 2633674494 ContactorOpenUnderLoadCount "This signal represents the number of times the contactors inside this High Voltage Energy Storage Pack instance have opened while current is flowing through them.  The current level (that determines if an opening event will be counted) shall be ...";
CM_ SG_ 2633674494 StOfHealth "This signal represents the expected remaining \"Life\" of this High Voltage Energy Storage Pack instance, in percent.  Battery life is a manufacturer-specific measure of how well the energy storage system is functioning relative to its nominal (rated) ...";
CM_ BO_ 2566565374 "High Voltage Energy Storage Pack 9 Configuration
Configuration data for High Voltage Energy Storage Pack 9.  Note that configuration data should not dynamically change during vehicle operation.";
CM_ SG_ 2566565374 NomRatedCapacity "Per the HVES manufacturer, this is the manufacturer's nominal rated capacity of this instance of the energy storage system.  The rated capacity does not change over the life of the HVES.
This parameter is for one of multiple packs in an HVESS.  If ...";
CM_ SG_ 2566565374 CellMinVLmt "Per the HVES manufacturer, this is the minimum cell voltage for this High Voltage Energy Storage Pack instance operation.  Operating below this value may damage HVES hardware, or compromise HVES life.
This parameter is for one of multiple packs in ...";
CM_ SG_ 2566565374 CellMaxVLmt "Per the HVES manufacturer, this is the maximum cell voltage for this High Voltage Energy Storage Pack instance operation.  Operating above this value may damage HVES hardware, or compromise HVES life.
This parameter is for one of multiple packs in ...";
CM_ SG_ 2566565374 RecommendedMinOperatingTemp "Per the HVES manufacturer, this is the recommended minimum temperature for this High Voltage Energy Storage Pack instance operation.  Operating below this value may damage HVES hardware, or compromise HVES life.
This parameter is for one of ...";
CM_ SG_ 2566565374 RecommendedMaxOperatingTemp "Per the HVES manufacturer, this is the recommended maximum temperature for this High Voltage Energy Storage Pack instance operation.  Operating above this value may damage HVES hardware, or compromise HVES life.
This parameter is for one of ...";
CM_ SG_ 2566565374 RecommendedMaxStOfCharge "Per the HVES manufacturer, this is the recommended maximum state of charge for this High Voltage Energy Storage Pack instance operation.  Operating above this value may compromise HVES life.
This parameter is for one of multiple packs in an HVESS ...";
CM_ SG_ 2566565374 RecommendedMinStOfCharge "Per the HVES manufacturer, this is the recommended minimum state of charge for this High Voltage Energy Storage Pack instance operation.  Operating below this value may compromise HVES life.
This parameter is for one of multiple packs in an HVESS ...";
CM_ SG_ 2566565374 RecommendedMaxOperatingV "Per the HVES manufacturer, this is the maximum recommended voltage level for this High Voltage Energy Storage Pack instance operation.  Operating above this value may compromise HVES life.
This parameter is for one of multiple packs in an HVESS ...";
CM_ SG_ 2566565374 RecommendedMinOperatingV "Per the HVES manufacturer, this is the minimum recommended voltage level for this High Voltage Energy Storage Pack instance operation.  Operating below this value may compromise HVES life.
This parameter is for one of multiple packs in an HVESS ...";
CM_ SG_ 2566565374 NomV "Per the HVES manufacturer, this is the nominal operating voltage of this High Voltage Energy Storage Pack instance, e.g. “300V” or “600V”.
This parameter is for one of multiple packs in an HVESS.  If there is only one pack in the system, the HVESS ...";
CM_ BO_ 2633673982 "High Voltage Energy Storage Pack 10 History
Historical data for High Voltage Energy Storage Pack 10.";
CM_ SG_ 2633673982 TotalEnergyOut "The cumulative energy which has flowed out of this High Voltage Energy Storage Pack instance over the lifetime of the battery pack. This parameter is the sum of the Energy out of this HVES instance. This value is reset when the pack is replaced. For ...";
CM_ SG_ 2633673982 TotalEnergyInput "The cumulative energy which has flowed into this High Voltage Energy Storage Pack instance over the lifetime of the battery pack. This parameter is the sum of the Energy into this HVES instance.
This value is reset when the pack is replaced. For ...";
CM_ SG_ 2633673982 TotalAccumulatedCharge "The total accumulated amp hours which have flowed through this High Voltage Energy Storage Pack instance.  This parameter is the sum of the absolute values of the Ampere hours into and out of this HVES instance.
This parameter is for one of ...";
CM_ SG_ 2633673982 TotalEnergyThroughput "The total energy throughput which has flowed through this High Voltage Energy Storage Pack instance.  This parameter is the sum of the absolute values of the Energy into and out of this HVES instance.
This parameter is for one of multiple packs in ...";
CM_ SG_ 2633673982 ContactorOpenUnderLoadCount "This signal represents the number of times the contactors inside this High Voltage Energy Storage Pack instance have opened while current is flowing through them.  The current level (that determines if an opening event will be counted) shall be ...";
CM_ SG_ 2633673982 StOfHealth "This signal represents the expected remaining \"Life\" of this High Voltage Energy Storage Pack instance, in percent.  Battery life is a manufacturer-specific measure of how well the energy storage system is functioning relative to its nominal (rated) ...";
CM_ BO_ 2566564862 "High Voltage Energy Storage Pack 10 Configuration
Configuration data for High Voltage Energy Storage Pack 10.  Note that configuration data should not dynamically change during vehicle operation.";
CM_ SG_ 2566564862 NomRatedCapacity "Per the HVES manufacturer, this is the manufacturer's nominal rated capacity of this instance of the energy storage system.  The rated capacity does not change over the life of the HVES.
This parameter is for one of multiple packs in an HVESS.  If ...";
CM_ SG_ 2566564862 CellMinVLmt "Per the HVES manufacturer, this is the minimum cell voltage for this High Voltage Energy Storage Pack instance operation.  Operating below this value may damage HVES hardware, or compromise HVES life.
This parameter is for one of multiple packs in ...";
CM_ SG_ 2566564862 CellMaxVLmt "Per the HVES manufacturer, this is the maximum cell voltage for this High Voltage Energy Storage Pack instance operation.  Operating above this value may damage HVES hardware, or compromise HVES life.
This parameter is for one of multiple packs in ...";
CM_ SG_ 2566564862 RecommendedMinOperatingTemp "Per the HVES manufacturer, this is the recommended minimum temperature for this High Voltage Energy Storage Pack instance operation.  Operating below this value may damage HVES hardware, or compromise HVES life.
This parameter is for one of ...";
CM_ SG_ 2566564862 RecommendedMaxOperatingTemp "Per the HVES manufacturer, this is the recommended maximum temperature for this High Voltage Energy Storage Pack instance operation.  Operating above this value may damage HVES hardware, or compromise HVES life.
This parameter is for one of ...";
CM_ SG_ 2566564862 RecommendedMaxStOfCharge "Per the HVES manufacturer, this is the recommended maximum state of charge for this High Voltage Energy Storage Pack instance operation.  Operating above this value may compromise HVES life.
This parameter is for one of multiple packs in an HVESS ...";
CM_ SG_ 2566564862 RecommendedMinStOfCharge "Per the HVES manufacturer, this is the recommended minimum state of charge for this High Voltage Energy Storage Pack instance operation.  Operating below this value may compromise HVES life.
This parameter is for one of multiple packs in an HVESS ...";
CM_ SG_ 2566564862 RecommendedMaxOperatingV "Per the HVES manufacturer, this is the maximum recommended voltage level for this High Voltage Energy Storage Pack instance operation.  Operating above this value may compromise HVES life.
This parameter is for one of multiple packs in an HVESS ...";
CM_ SG_ 2566564862 RecommendedMinOperatingV "Per the HVES manufacturer, this is the minimum recommended voltage level for this High Voltage Energy Storage Pack instance operation.  Operating below this value may compromise HVES life.
This parameter is for one of multiple packs in an HVESS ...";
CM_ SG_ 2566564862 NomV "Per the HVES manufacturer, this is the nominal operating voltage of this High Voltage Energy Storage Pack instance, e.g. “300V” or “600V”.
This parameter is for one of multiple packs in an HVESS.  If there is only one pack in the system, the HVESS ...";
CM_ BO_ 2364690430 "High Voltage Energy Storage Pack 10 Data 11
Data set 11 (electrical data) for High Voltage Energy Storage Pack 10.";
CM_ SG_ 2364690430 ActualChargeRate "This signal represents the actual present charge rate of this High Voltage Energy Storage Pack instance.
This parameter is for one of multiple packs in an HVESS. If there is only one pack in the system, the HVESS parameters should be used. If there ...";
CM_ SG_ 2364690430 LvlNegToChassisGroundV "Voltage difference between the most negative terminal of the HVES battery and chassis measured at the battery side of any HVES contained output contactor.  This voltage may be used for system level monitoring of battery shorts to chassis within the ...";
CM_ SG_ 2364690430 BusVNegToChassisGroundV "Voltage difference between the most negative terminal of the HVES battery and chassis measured on the hybrid system bus side (not the battery side) of any HVES contained output contactor.  This voltage may be used for system level monitoring of ...";
CM_ BO_ 2364690174 "High Voltage Energy Storage Pack 10 Data 10
Data set 10 (electrical) for High Voltage Energy Storage Pack 10.";
CM_ SG_ 2364690174 HVBusPassiveIsolTestResults "The isolation resistance expressed in Ohms per Volt that resulted from the High-Voltage Bus Passive Isolation Test.
See SPN 14520 (HVESP10 High-Voltage Bus Passive Isolation Test Status) for test status and SPN 14468 (HVESP10 High-Voltage Bus ...";
CM_ SG_ 2364690174 HVBusActiveIsolTestResults "The isolation resistance expressed in Ohms per Volt that resulted from the High-Voltage Bus Active Isolation Test.
See SPN 14519 (HVESP10 High-Voltage Bus Active Isolation Test Status) for test status and SPN 14468 (HVESP10 High-Voltage Bus Active ...";
CM_ SG_ 2364690174 LowestCellStOfChargeCellNum "Identifies the location of SPN 14506 (HVESP10 Lowest Cell State of Charge) within SPN 14585 (HVESP10 Lowest Cell State of Charge Module Number).
This parameter is for one of multiple packs in an HVESS. If there is only one pack in the system, the ...";
CM_ SG_ 2364690174 LowestCellStOfChargeModuleNum "Identifies the location of the module containing SPN 14506 (HVESP10 Lowest Cell State of Charge).
This parameter is for one of multiple packs in an HVESS. If there is only one pack in the system, the HVESS parameters should be used. If there are ...";
CM_ SG_ 2364690174 HighestCellStOfChargeCellNum "Identifies the location of SPN 14507 (HVESP10 Highest Cell State of Charge) within SPN 14583 (HVESP10 Highest Cell State of Charge Module Number).
This parameter is for one of multiple packs in an HVESS. If there is only one pack in the system, the ...";
CM_ SG_ 2364690174 HighestCellStOfChargeModuleNum "Identifies the location of the module containing SPN 14507 (HVESP10 Highest Cell State of Charge).
This parameter is for one of multiple packs in an HVESS. If there is only one pack in the system, the HVESS parameters should be used. If there are ...";
CM_ BO_ 2364689918 "High Voltage Energy Storage Pack 10 Data 9
Data set 9 (thermal) for High Voltage Energy Storage Pack 10.";
CM_ SG_ 2364689918 Data9CRC "The CRC is defined as follows:
• Length: 8 bits
• Polynomial: x^8+x^5+x^3+x^2+x+1
• Initial Value: FFh
• Input Data Reflection: Not reflected
• Result Data Reflection: Not reflected
• XOR value: FFh
SAE makes no claim of the functional safety ...";
CM_ SG_ 2364689918 Data9Counter "The message counter is used to detect situations where the transmitting ECU malfunction repeats the same frame all the time. The receiver of the information may use the counter parameter to detect this situation. The transmitting device will ...";
CM_ SG_ 2364689918 Data9EmbeddedIntegritySupport "Indicates SPN 23003 (HVESP10 Data 9 CRC) and SPN 23002 (HVESP10 Data 9 Counter) are supported by the sender.
00b = Embedded CRC and Counter are supported by the sender
01b = Protection is supported using J1939-76 SHM
10b = Reserved
11b = CRC and ...";
CM_ SG_ 2364689918 HVESS10ThermalEventDetected "A sensor has detected the presence of a thermal event at or near High Voltage Energy Storage Pack instance.
00b = No Thermal Event Detected
01b = Thermal Event Detected
10b = Error
11b = Not available
This parameter is for one of multiple packs ...";
CM_ SG_ 2364689918 LowestCellTempCellNum "Identifies the location of SPN 14498 (HVESP10 Lowest Cell Temperature) within SPN 14581 (HVESP10 Lowest Cell Temperature Module Number).
This parameter is for one of multiple packs in an HVESS. If there is only one pack in the system, the HVESS ...";
CM_ SG_ 2364689918 LowestCellTempModuleNum "Identifies the location of the module containing SPN 14498 (HVESP10 Lowest Cell Temperature).
This parameter is for one of multiple packs in an HVESS. If there is only one pack in the system, the HVESS parameters should be used. If there are ...";
CM_ SG_ 2364689918 HighestCellTempCellNum "Identifies the location of SPN 14497 (HVESP10 Highest Cell Temperature) within SPN 14579 (HVESP10 Highest Cell Temperature Module Number).
This parameter is for one of multiple packs in an HVESS. If there is only one pack in the system, the HVESS ...";
CM_ SG_ 2364689918 HighestCellTempModuleNum "Identifies the location of the module containing SPN 14497 (HVESP10 Highest Cell Temperature).
This parameter is for one of multiple packs in an HVESS. If there is only one pack in the system, the HVESS parameters should be used. If there are ...";
CM_ BO_ 2364689662 "High Voltage Energy Storage Pack 10 Data 8
Data set 8 (electrical data) for High Voltage Energy Storage Pack 10.";
CM_ SG_ 2364689662 AvgCellV "The average cell voltage in this High Voltage Energy Storage Pack instance.
This parameter is for one of multiple packs in an HVESS.  If there is only one pack in the system, the HVESS parameters should be used. If there are multiple packs in the ...";
CM_ SG_ 2364689662 LowestCellVCellNum "Identifies the location of SPN 14495 (HVESP10 Lowest Cell Voltage) within SPN 14576 (HVESP10 Lowest Cell Voltage Module Number).
This parameter is for one of multiple packs in an HVESS. If there is only one pack in the system, the HVESS parameters ...";
CM_ SG_ 2364689662 LowestCellVModuleNum "Identifies the location of the module containing SPN 14495 (HVESP10 Lowest Cell Voltage).
This parameter is for one of multiple packs in an HVESS. If there is only one pack in the system, the HVESS parameters should be used. If there are multiple ...";
CM_ SG_ 2364689662 HighestCellVCellNum "Identifies the location of SPN 14494 (HVESP10 Highest Cell Voltage) within SPN 14574 (HVESP10 Highest Cell Voltage Module Number).
This parameter is for one of multiple packs in an HVESS. If there is only one pack in the system, the HVESS ...";
CM_ SG_ 2364689662 HighestCellVModuleNum "Identifies the location of the module containing SPN 14494 (HVESP10 Highest Cell Voltage).
This parameter is for one of multiple packs in an HVESS. If there is only one pack in the system, the HVESS parameters should be used. If there are multiple ...";
CM_ BO_ 2364689406 "High Voltage Energy Storage Pack 10 Thermal Management System Status 1
Collection of data the High Voltage Energy Storage Pack 10 Thermal Management System sends to the Hybrid Controller.";
CM_ SG_ 2364689406 TMSCoolantLvl "Indicates the coolant level in this HVES Thermal Management System (TMS).
This parameter is for one of multiple packs in an HVESS.  If there is only one pack in the system, the HVESS parameters should be used. If there are multiple packs in the ...";
CM_ SG_ 2364689406 TMSMode "Indicates the operating mode of the Thermal Management System.  The heat transfer medium may be (e.g. liquid or air).  The cooling system may be fans, liquid coolant, or a combination of mediums.  The system may include an air and/or liquid ...";
CM_ SG_ 2364689406 TMSHVILStatus "In multiple HVES configurations, this is the status of the High Voltage Interlock Loop from the viewpoint of this Thermal Management System.
00b = HVIL Closed
01b = HVIL Open
10b = Error
11b = Not Available
This parameter is for one of multiple ...";
CM_ SG_ 2364689406 TMSHtrStatus "The state of this High Voltage Energy Storage Pack heater
This parameter is for one of multiple packs in an HVESS.  If there is only one pack in the system, the HVESS parameters should be used. If there are multiple packs in the system, then both ...";
CM_ SG_ 2364689406 TMSRelHumidty "When this High Voltage Energy Storage Pack Thermal Management System is equipped with a relative humidity sensor, this is the  measured Relative Humidity.
This parameter is for one of multiple packs in an HVESS.  If there is only one pack in the ...";
CM_ SG_ 2364689406 TMSCompressorSpd "When this High Voltage Energy Storage Pack Thermal Management System is equipped with an active cooling system (e.g. air conditioner), this is the Compressor Speed.
This parameter is for one of multiple packs in an HVESS.  If there is only one pack ...";
CM_ SG_ 2364689406 TMSHVInputPwr "This is the high-voltage power consumed by this HVES Thermal Management System (TMS).
This parameter is for one of multiple packs in an HVESS.  If there is only one pack in the system, the HVESS parameters should be used. If there are multiple ...";
CM_ SG_ 2364689406 TMSSLIInputPwr "This is the low-voltage power consumed by this HVES Thermal Management System (TMS).
This parameter is for one of multiple packs in an HVESS.  If there is only one pack in the system, the HVESS parameters should be used.  If there are multiple ...";
CM_ BO_ 2364689150 "High Voltage Energy Storage Pack 10 Module Status 1
Module Status message 1 for High Voltage Energy Storage Pack 10.";
CM_ SG_ 2364689150 Module32OperationalStatus "Operational Status of Module 32 in this High Voltage Energy Storage Pack Instance.  Not Operational is used when the module is initializing or not able to function (e.g. internal module level monitors have failed).  Operational indicates that the ...";
CM_ SG_ 2364689150 Module31OperationalStatus "Operational Status of Module 31 in this High Voltage Energy Storage Pack Instance.  Not Operational is used when the module is initializing or not able to function (e.g. internal module level monitors have failed).  Operational indicates that the ...";
CM_ SG_ 2364689150 Module30OperationalStatus "Operational Status of Module 30 in this High Voltage Energy Storage Pack Instance.  Not Operational is used when the module is initializing or not able to function (e.g. internal module level monitors have failed).  Operational indicates that the ...";
CM_ SG_ 2364689150 Module29OperationalStatus "Operational Status of Module 29 in this High Voltage Energy Storage Pack Instance.  Not Operational is used when the module is initializing or not able to function (e.g. internal module level monitors have failed).  Operational indicates that the ...";
CM_ SG_ 2364689150 Module28OperationalStatus "Operational Status of Module 28 in this High Voltage Energy Storage Pack Instance.  Not Operational is used when the module is initializing or not able to function (e.g. internal module level monitors have failed).  Operational indicates that the ...";
CM_ SG_ 2364689150 Module27OperationalStatus "Operational Status of Module 27 in this High Voltage Energy Storage Pack Instance.  Not Operational is used when the module is initializing or not able to function (e.g. internal module level monitors have failed).  Operational indicates that the ...";
CM_ SG_ 2364689150 Module26OperationalStatus "Operational Status of Module 26 in this High Voltage Energy Storage Pack Instance.  Not Operational is used when the module is initializing or not able to function (e.g. internal module level monitors have failed).  Operational indicates that the ...";
CM_ SG_ 2364689150 Module25OperationalStatus "Operational Status of Module 25 in this High Voltage Energy Storage Pack Instance.  Not Operational is used when the module is initializing or not able to function (e.g. internal module level monitors have failed).  Operational indicates that the ...";
CM_ SG_ 2364689150 Module24OperationalStatus "Operational Status of Module 24 in this High Voltage Energy Storage Pack Instance.  Not Operational is used when the module is initializing or not able to function (e.g. internal module level monitors have failed).  Operational indicates that the ...";
CM_ SG_ 2364689150 Module23OperationalStatus "Operational Status of Module 23 in this High Voltage Energy Storage Pack Instance.  Not Operational is used when the module is initializing or not able to function (e.g. internal module level monitors have failed).  Operational indicates that the ...";
CM_ SG_ 2364689150 Module22OperationalStatus "Operational Status of Module 22 in this High Voltage Energy Storage Pack Instance.  Not Operational is used when the module is initializing or not able to function (e.g. internal module level monitors have failed).  Operational indicates that the ...";
CM_ SG_ 2364689150 Module21OperationalStatus "Operational Status of Module 21 in this High Voltage Energy Storage Pack Instance.  Not Operational is used when the module is initializing or not able to function (e.g. internal module level monitors have failed).  Operational indicates that the ...";
CM_ SG_ 2364689150 Module20OperationalStatus "Operational Status of Module 20 in this High Voltage Energy Storage Pack Instance.  Not Operational is used when the module is initializing or not able to function (e.g. internal module level monitors have failed).  Operational indicates that the ...";
CM_ SG_ 2364689150 Module19OperationalStatus "Operational Status of Module 19 in this High Voltage Energy Storage Pack Instance.  Not Operational is used when the module is initializing or not able to function (e.g. internal module level monitors have failed).  Operational indicates that the ...";
CM_ SG_ 2364689150 Module18OperationalStatus "Operational Status of Module 18 in this High Voltage Energy Storage Pack Instance.  Not Operational is used when the module is initializing or not able to function (e.g. internal module level monitors have failed).  Operational indicates that the ...";
CM_ SG_ 2364689150 Module17OperationalStatus "Operational Status of Module 17 in this High Voltage Energy Storage Pack Instance.  Not Operational is used when the module is initializing or not able to function (e.g. internal module level monitors have failed).  Operational indicates that the ...";
CM_ SG_ 2364689150 Module16OperationalStatus "Operational Status of Module 16 in this High Voltage Energy Storage Pack Instance.  Not Operational is used when the module is initializing or not able to function (e.g. internal module level monitors have failed).  Operational indicates that the ...";
CM_ SG_ 2364689150 Module15OperationalStatus "Operational Status of Module 15 in this High Voltage Energy Storage Pack Instance.  Not Operational is used when the module is initializing or not able to function (e.g. internal module level monitors have failed).  Operational indicates that the ...";
CM_ SG_ 2364689150 Module14OperationalStatus "Operational Status of Module 14 in this High Voltage Energy Storage Pack Instance.  Not Operational is used when the module is initializing or not able to function (e.g. internal module level monitors have failed).  Operational indicates that the ...";
CM_ SG_ 2364689150 Module13OperationalStatus "Operational Status of Module 13 in this High Voltage Energy Storage Pack Instance.  Not Operational is used when the module is initializing or not able to function (e.g. internal module level monitors have failed).  Operational indicates that the ...";
CM_ SG_ 2364689150 Module12OperationalStatus "Operational Status of Module 12 in this High Voltage Energy Storage Pack Instance.  Not Operational is used when the module is initializing or not able to function (e.g. internal module level monitors have failed).  Operational indicates that the ...";
CM_ SG_ 2364689150 Module11OperationalStatus "Operational Status of Module 11 in this High Voltage Energy Storage Pack Instance.  Not Operational is used when the module is initializing or not able to function (e.g. internal module level monitors have failed).  Operational indicates that the ...";
CM_ SG_ 2364689150 Module10OperationalStatus "Operational Status of Module 10 in this High Voltage Energy Storage Pack Instance.  Not Operational is used when the module is initializing or not able to function (e.g. internal module level monitors have failed).  Operational indicates that the ...";
CM_ SG_ 2364689150 Module9OperationalStatus "Operational Status of Module 9 in this High Voltage Energy Storage Pack Instance.  Not Operational is used when the module is initializing or not able to function (e.g. internal module level monitors have failed).  Operational indicates that the ...";
CM_ SG_ 2364689150 Module8OperationalStatus "Operational Status of Module 8 in this High Voltage Energy Storage Pack Instance.  Not Operational is used when the module is initializing or not able to function (e.g. internal module level monitors have failed).  Operational indicates that the ...";
CM_ SG_ 2364689150 Module7OperationalStatus "Operational Status of Module 7 in this High Voltage Energy Storage Pack Instance.  Not Operational is used when the module is initializing or not able to function (e.g. internal module level monitors have failed).  Operational indicates that the ...";
CM_ SG_ 2364689150 Module6OperationalStatus "Operational Status of Module 6 in this High Voltage Energy Storage Pack Instance.  Not Operational is used when the module is initializing or not able to function (e.g. internal module level monitors have failed).  Operational indicates that the ...";
CM_ SG_ 2364689150 Module5OperationalStatus "Operational Status of Module 5 in this High Voltage Energy Storage Pack Instance.  Not Operational is used when the module is initializing or not able to function (e.g. internal module level monitors have failed).  Operational indicates that the ...";
CM_ SG_ 2364689150 Module4OperationalStatus "Operational Status of Module 4 in this High Voltage Energy Storage Pack Instance.  Not Operational is used when the module is initializing or not able to function (e.g. internal module level monitors have failed).  Operational indicates that the ...";
CM_ SG_ 2364689150 Module3OperationalStatus "Operational Status of Module 3 in this High Voltage Energy Storage Pack Instance.  Not Operational is used when the module is initializing or not able to function (e.g. internal module level monitors have failed).  Operational indicates that the ...";
CM_ SG_ 2364689150 Module2OperationalStatus "Operational Status of Module 2 in this High Voltage Energy Storage Pack Instance.  Not Operational is used when the module is initializing or not able to function (e.g. internal module level monitors have failed).  Operational indicates that the ...";
CM_ SG_ 2364689150 Module1OperationalStatus "Operational Status of Module 1 in this High Voltage Energy Storage Pack Instance.  Not Operational is used when the module is initializing or not able to function (e.g. internal module level monitors have failed).  Operational indicates that the ...";
CM_ BO_ 2364688894 "High Voltage Energy Storage Pack 10 Data 7
Data set 7 (electrical) for High Voltage Energy Storage Pack 10.";
CM_ SG_ 2364688894 MaxChargeVLmt "The maximum voltage level not to be exceeded while charging this High Voltage Energy Storage Pack instance. If this parameter is not supported, the maximum charge voltage should be limited to SPN 14602 (HVESP10 Recommended Maximum Operating ...";
CM_ SG_ 2364688894 ChargeEnergyCapacity "The amount of unused electrical energy storage available to be filled by charging this High Voltage Energy Storage Pack instance, i.e. “how much empty space is remaining in the tank”. See SPN 14502 (HVESP10 Charge Capacity) for Ampere-hours (Ah).
 ...";
CM_ SG_ 2364688894 DisEnergyCapacity "The amount of stored electrical energy in this High Voltage Energy Storage Pack instance that is available for use by the hybrid system, i.e. “how full is the tank”. See SPN 14501 (HVESP10 Discharge Capacity) for Ampere-hours (Ah).
This parameter ...";
BA_DEF_ SG_  "GenSigInactiveValue" INT 0 0;
BA_DEF_ SG_  "SigType" ENUM  "Default","Range","RangeSigned","ASCII","Discrete","Control","ReferencePGN","DTC","StringDelimiter","StringLength","StringLengthControl","MessageCounter","MessageChecksum";
BA_DEF_ SG_  "GenSigStartValue" INT 0 2147483647;
BA_DEF_ SG_  "GenSigSendType" ENUM  "Cyclic","OnWrite","OnWriteWithRepetition","OnChange","OnChangeWithRepetition","IfActive","IfActiveWithRepetition","NoSigSendType";
BA_DEF_ SG_  "GenSigILSupport" ENUM  "No","Yes";
BA_DEF_ SG_  "SPN" INT 0 524287;
BA_DEF_ BO_  "J1939CPgSendTimeout" INT -1 3600000;
BA_DEF_ BO_  "J1939CPgTOS" INT 0 7;
BA_DEF_ BO_  "J1939PgAppearanceOnBus" ENUM  "Default","CAN_Extended","CANFD_Extended";
BA_DEF_ BO_  "FsJ1939UseCrcAndCounter" STRING ;
BA_DEF_ BO_  "TpJ1939VarDlc" ENUM  "No","Yes";
BA_DEF_ BO_  "GenMsgNrOfRepetition" INT 0 1000000;
BA_DEF_ BO_  "GenMsgCycleTimeFast" INT 0 3600000;
BA_DEF_ BO_  "GenMsgFastOnStart" INT 0 100000;
BA_DEF_ BO_  "GenMsgStartDelayTime" INT 0 100000;
BA_DEF_ BO_  "GenMsgILSupport" ENUM  "No","Yes";
BA_DEF_ BO_  "GenMsgDelayTime" INT 0 1000;
BA_DEF_ BO_  "GenMsgRequestable" INT 0 1;
BA_DEF_ BO_  "GenMsgSendType" ENUM  "cyclic","NotUsed","NotUsed","NotUsed","NotUsed","NotUsed","NotUsed","IfActive","noMsgSendType";
BA_DEF_ BO_  "VFrameFormat" ENUM  "StandardCAN","ExtendedCAN","reserved","J1939PG","reserved","reserved","reserved","reserved","reserved","reserved","reserved","reserved","reserved","reserved","StandardCAN_FD","ExtendedCAN_FD";
BA_DEF_ BO_  "SingleFrame" INT 0 1;
BA_DEF_ BO_  "GenMsgCycleTime" INT 0 3600000;
BA_DEF_ SG_  "SystemSignalLongSymbol" STRING ;
BA_DEF_DEF_  "GenSigInactiveValue" 0;
BA_DEF_DEF_  "SigType" "Default";
BA_DEF_DEF_  "GenSigStartValue" 0;
BA_DEF_DEF_  "GenSigSendType" "NoSigSendType";
BA_DEF_DEF_  "GenSigILSupport" "Yes";
BA_DEF_DEF_  "SPN" 0;
BA_DEF_DEF_  "J1939CPgSendTimeout" -1;
BA_DEF_DEF_  "J1939CPgTOS" 2;
BA_DEF_DEF_  "J1939PgAppearanceOnBus" "Default";
BA_DEF_DEF_  "FsJ1939UseCrcAndCounter" "";
BA_DEF_DEF_  "TpJ1939VarDlc" "No";
BA_DEF_DEF_  "GenMsgNrOfRepetition" 0;
BA_DEF_DEF_  "GenMsgCycleTimeFast" 0;
BA_DEF_DEF_  "GenMsgFastOnStart" 0;
BA_DEF_DEF_  "GenMsgStartDelayTime" 0;
BA_DEF_DEF_  "GenMsgILSupport" "Yes";
BA_DEF_DEF_  "GenMsgDelayTime" 0;
BA_DEF_DEF_  "GenMsgRequestable" 1;
BA_DEF_DEF_  "GenMsgSendType" "noMsgSendType";
BA_DEF_DEF_  "VFrameFormat" "J1939PG";
BA_DEF_DEF_  "SingleFrame" 1;
BA_DEF_DEF_  "GenMsgCycleTime" 0;
BA_DEF_DEF_  "SystemSignalLongSymbol" "";
BA_ "FsJ1939UseCrcAndCounter" BO_ 2349858558 "Aa";
BA_ "GenMsgSendType" BO_ 2349858558 0;
BA_ "GenMsgCycleTime" BO_ 2349858558 20;
BA_ "GenMsgSendType" BO_ 2365254910 0;
BA_ "GenMsgCycleTime" BO_ 2365254910 100;
BA_ "GenMsgSendType" BO_ 2365254654 0;
BA_ "GenMsgCycleTime" BO_ 2365254654 100;
BA_ "GenMsgSendType" BO_ 2365254398 0;
BA_ "GenMsgCycleTime" BO_ 2365254398 100;
BA_ "GenMsgSendType" BO_ 2365254142 0;
BA_ "GenMsgCycleTime" BO_ 2365254142 100;
BA_ "GenMsgSendType" BO_ 2365253886 0;
BA_ "GenMsgCycleTime" BO_ 2365253886 100;
BA_ "GenMsgSendType" BO_ 2231035902 0;
BA_ "GenMsgCycleTime" BO_ 2231035902 50;
BA_ "GenMsgSendType" BO_ 2231035646 0;
BA_ "GenMsgCycleTime" BO_ 2231035646 50;
BA_ "GenMsgSendType" BO_ 2231035390 0;
BA_ "GenMsgCycleTime" BO_ 2231035390 50;
BA_ "GenMsgSendType" BO_ 2231034878 0;
BA_ "GenMsgCycleTime" BO_ 2231034878 50;
BA_ "GenMsgSendType" BO_ 2231035134 0;
BA_ "GenMsgCycleTime" BO_ 2231035134 50;
BA_ "GenMsgSendType" BO_ 2231034622 0;
BA_ "GenMsgCycleTime" BO_ 2231034622 50;
BA_ "GenMsgSendType" BO_ 2231034366 0;
BA_ "GenMsgCycleTime" BO_ 2231034366 50;
BA_ "GenMsgSendType" BO_ 2231034110 0;
BA_ "GenMsgCycleTime" BO_ 2231034110 50;
BA_ "GenMsgSendType" BO_ 2231033854 0;
BA_ "GenMsgCycleTime" BO_ 2231033854 50;
BA_ "GenMsgSendType" BO_ 2231033598 0;
BA_ "GenMsgCycleTime" BO_ 2231033598 50;
BA_ "GenMsgSendType" BO_ 2231033342 0;
BA_ "GenMsgCycleTime" BO_ 2231033342 50;
BA_ "GenMsgSendType" BO_ 2231033086 0;
BA_ "GenMsgCycleTime" BO_ 2231033086 50;
BA_ "GenMsgSendType" BO_ 2231032830 0;
BA_ "GenMsgCycleTime" BO_ 2231032830 50;
BA_ "GenMsgSendType" BO_ 2231032574 0;
BA_ "GenMsgCycleTime" BO_ 2231032574 50;
BA_ "GenMsgSendType" BO_ 2231032318 0;
BA_ "GenMsgCycleTime" BO_ 2231032318 50;
BA_ "GenMsgSendType" BO_ 2231032062 0;
BA_ "GenMsgCycleTime" BO_ 2231032062 50;
BA_ "GenMsgSendType" BO_ 2566575870 0;
BA_ "GenMsgCycleTime" BO_ 2566575870 1000;
BA_ "GenMsgDelayTime" BO_ 2566575614 10;
BA_ "GenMsgSendType" BO_ 2566575614 0;
BA_ "GenMsgCycleTime" BO_ 2566575614 100;
BA_ "FsJ1939UseCrcAndCounter" BO_ 2566575102 "Aa";
BA_ "GenMsgDelayTime" BO_ 2566575102 100;
BA_ "GenMsgSendType" BO_ 2566575102 0;
BA_ "GenMsgCycleTime" BO_ 2566575102 1000;
BA_ "GenMsgSendType" BO_ 2566574846 0;
BA_ "GenMsgCycleTime" BO_ 2566574846 1000;
BA_ "GenMsgSendType" BO_ 2499465726 0;
BA_ "GenMsgCycleTime" BO_ 2499465726 500;
BA_ "GenMsgDelayTime" BO_ 2499465470 100;
BA_ "GenMsgSendType" BO_ 2499465470 0;
BA_ "GenMsgCycleTime" BO_ 2499465470 1000;
BA_ "GenMsgSendType" BO_ 2566573822 0;
BA_ "GenMsgCycleTime" BO_ 2566573822 100;
BA_ "GenMsgSendType" BO_ 2499464702 0;
BA_ "GenMsgCycleTime" BO_ 2499464702 500;
BA_ "GenMsgSendType" BO_ 2566572286 0;
BA_ "GenMsgCycleTime" BO_ 2566572286 1000;
BA_ "GenMsgSendType" BO_ 2566572030 0;
BA_ "GenMsgCycleTime" BO_ 2566572030 100;
BA_ "GenMsgSendType" BO_ 2499462910 0;
BA_ "GenMsgCycleTime" BO_ 2499462910 100;
BA_ "GenMsgSendType" BO_ 2566571518 0;
BA_ "GenMsgCycleTime" BO_ 2566571518 100;
BA_ "GenMsgSendType" BO_ 2566571006 0;
BA_ "GenMsgCycleTime" BO_ 2566571006 1000;
BA_ "GenMsgDelayTime" BO_ 2566569214 100;
BA_ "GenMsgSendType" BO_ 2566569214 0;
BA_ "GenMsgCycleTime" BO_ 2566569214 1000;
BA_ "GenMsgDelayTime" BO_ 2566568958 100;
BA_ "GenMsgSendType" BO_ 2566568958 0;
BA_ "GenMsgCycleTime" BO_ 2566568958 1000;
BA_ "GenMsgDelayTime" BO_ 2566568702 50;
BA_ "GenMsgSendType" BO_ 2566568702 0;
BA_ "GenMsgCycleTime" BO_ 2566568702 100;
BA_ "GenMsgSendType" BO_ 2566568446 0;
BA_ "GenMsgCycleTime" BO_ 2566568446 1000;
BA_ "GenMsgSendType" BO_ 2566568190 0;
BA_ "GenMsgCycleTime" BO_ 2566568190 100;
BA_ "FsJ1939UseCrcAndCounter" BO_ 2566567934 "Bc";
BA_ "GenMsgSendType" BO_ 2566567934 0;
BA_ "GenMsgCycleTime" BO_ 2566567934 20;
BA_ "GenMsgDelayTime" BO_ 2566567422 100;
BA_ "GenMsgSendType" BO_ 2566567422 0;
BA_ "GenMsgCycleTime" BO_ 2566567422 1000;
BA_ "GenMsgDelayTime" BO_ 2566567166 100;
BA_ "GenMsgSendType" BO_ 2566567166 0;
BA_ "GenMsgCycleTime" BO_ 2566567166 1000;
BA_ "GenMsgSendType" BO_ 2364690430 0;
BA_ "GenMsgCycleTime" BO_ 2364690430 100;
BA_ "GenMsgSendType" BO_ 2364690174 0;
BA_ "GenMsgCycleTime" BO_ 2364690174 100;
BA_ "FsJ1939UseCrcAndCounter" BO_ 2364689918 "Aa";
BA_ "GenMsgSendType" BO_ 2364689918 0;
BA_ "GenMsgCycleTime" BO_ 2364689918 100;
BA_ "GenMsgSendType" BO_ 2364689662 0;
BA_ "GenMsgCycleTime" BO_ 2364689662 100;
BA_ "GenMsgSendType" BO_ 2364689406 0;
BA_ "GenMsgCycleTime" BO_ 2364689406 100;
BA_ "GenMsgSendType" BO_ 2364689150 0;
BA_ "GenMsgCycleTime" BO_ 2364689150 100;
BA_ "GenMsgSendType" BO_ 2364688894 0;
BA_ "GenMsgCycleTime" BO_ 2364688894 100;
BA_ "SigType" SG_ 2349858558 Ctrl1CRC 12;
BA_ "SPN" SG_ 2349858558 Ctrl1CRC 15279;
BA_ "SigType" SG_ 2349858558 Ctrl1Counter 11;
BA_ "SPN" SG_ 2349858558 Ctrl1Counter 15278;
BA_ "SigType" SG_ 2349858558 ThermalMnmgtMaintenanceReq 5;
BA_ "SPN" SG_ 2349858558 ThermalMnmgtMaintenanceReq 20889;
BA_ "SigType" SG_ 2349858558 HVBusLowSideResistorConnectReq 5;
BA_ "SPN" SG_ 2349858558 HVBusLowSideResistorConnectReq 15277;
BA_ "SigType" SG_ 2349858558 HVBusHiSideResistorConnectReq 5;
BA_ "SPN" SG_ 2349858558 HVBusHiSideResistorConnectReq 15276;
BA_ "SigType" SG_ 2349858558 OpConsent 4;
BA_ "SPN" SG_ 2349858558 OpConsent 15275;
BA_ "SigType" SG_ 2349858558 EnableInternalChargerCmd 5;
BA_ "SPN" SG_ 2349858558 EnableInternalChargerCmd 15274;
BA_ "SigType" SG_ 2349858558 CellBalancingCmd 5;
BA_ "SPN" SG_ 2349858558 CellBalancingCmd 15273;
BA_ "SigType" SG_ 2349858558 HVBusPassiveIsolTestCmd 5;
BA_ "SPN" SG_ 2349858558 HVBusPassiveIsolTestCmd 15272;
BA_ "SigType" SG_ 2349858558 HVBusActiveIsolTestCmd 5;
BA_ "SPN" SG_ 2349858558 HVBusActiveIsolTestCmd 15271;
BA_ "SigType" SG_ 2349858558 PwrDownCmd 5;
BA_ "SPN" SG_ 2349858558 PwrDownCmd 15270;
BA_ "SigType" SG_ 2349858558 HVBusConnectCmd 5;
BA_ "SPN" SG_ 2349858558 HVBusConnectCmd 15269;
BA_ "GenSigStartValue" SG_ 2148466430 InvertedPF 255;
BA_ "GenSigStartValue" SG_ 2148466430 InvertedPS 255;
BA_ "GenSigStartValue" SG_ 2148466430 InvertedSA 255;
BA_ "GenSigStartValue" SG_ 2148466430 InvertedEDP 1;
BA_ "GenSigStartValue" SG_ 2148466430 InvertedDP 1;
BA_ "GenSigStartValue" SG_ 2365254910 CRC8 255;
BA_ "GenSigStartValue" SG_ 2365254654 CRC8 255;
BA_ "GenSigStartValue" SG_ 2365254398 CRC8 255;
BA_ "GenSigStartValue" SG_ 2365254142 CRC8 255;
BA_ "GenSigStartValue" SG_ 2365253886 CRC8 255;
BA_ "GenSigStartValue" SG_ 2231035902 CRC8 255;
BA_ "GenSigStartValue" SG_ 2231035646 TrackID 1;
BA_ "GenSigStartValue" SG_ 2231035646 CRC8 255;
BA_ "GenSigStartValue" SG_ 2231035390 CRC8 255;
BA_ "GenSigStartValue" SG_ 2231034878 CRC8 255;
BA_ "GenSigStartValue" SG_ 2231035134 TrackID 1;
BA_ "GenSigStartValue" SG_ 2231035134 CRC8 255;
BA_ "GenSigStartValue" SG_ 2231034622 TrackID 1;
BA_ "GenSigStartValue" SG_ 2231034622 CRC8 255;
BA_ "GenSigStartValue" SG_ 2231034366 CRC8 255;
BA_ "GenSigStartValue" SG_ 2231034110 TrackID 1;
BA_ "GenSigStartValue" SG_ 2231034110 CRC8 255;
BA_ "GenSigStartValue" SG_ 2231033854 CRC8 255;
BA_ "GenSigStartValue" SG_ 2231033598 TrackID 1;
BA_ "GenSigStartValue" SG_ 2231033598 CRC8 255;
BA_ "GenSigStartValue" SG_ 2231033342 CRC8 255;
BA_ "GenSigStartValue" SG_ 2231033086 TrackID 1;
BA_ "GenSigStartValue" SG_ 2231033086 CRC8 255;
BA_ "GenSigStartValue" SG_ 2231032830 CRC8 255;
BA_ "GenSigStartValue" SG_ 2231032574 TrackID 1;
BA_ "GenSigStartValue" SG_ 2231032574 CRC8 255;
BA_ "GenSigStartValue" SG_ 2231032318 CRC8 255;
BA_ "GenSigStartValue" SG_ 2231032062 TrackID 1;
BA_ "GenSigStartValue" SG_ 2231032062 CRC8 255;
BA_ "SPN" SG_ 2566575870 CommunicationsPhysicalLayer 22691;
BA_ "SPN" SG_ 2566575870 ConnType 22690;
BA_ "SPN" SG_ 2566575870 InletSt 22689;
BA_ "SigType" SG_ 2566575870 InletContactorSt 5;
BA_ "SPN" SG_ 2566575870 InletContactorSt 22688;
BA_ "SigType" SG_ 2566575870 ConnectorLockPermission 5;
BA_ "SPN" SG_ 2566575870 ConnectorLockPermission 21086;
BA_ "SPN" SG_ 2566575870 ConnectorLockSt 12863;
BA_ "SigType" SG_ 2566575870 ManualOvrd 4;
BA_ "SPN" SG_ 2566575870 ManualOvrd 12862;
BA_ "SigType" SG_ 2566575870 ConnectorReleaseLatch 5;
BA_ "SPN" SG_ 2566575870 ConnectorReleaseLatch 12861;
BA_ "SigType" SG_ 2566575614 ACRMSCurLmtNeutral 1;
BA_ "SPN" SG_ 2566575614 ACRMSCurLmtNeutral 13005;
BA_ "SigType" SG_ 2566575614 ACRMSCurLmtL3 1;
BA_ "SPN" SG_ 2566575614 ACRMSCurLmtL3 13004;
BA_ "SigType" SG_ 2566575614 ACRMSCurLmtL2 1;
BA_ "SPN" SG_ 2566575614 ACRMSCurLmtL2 13003;
BA_ "SigType" SG_ 2566575614 ACRMSCurLmtL1 1;
BA_ "SPN" SG_ 2566575614 ACRMSCurLmtL1 12865;
BA_ "SigType" SG_ 2566575358 RMSV 1;
BA_ "SPN" SG_ 2566575358 RMSV 12867;
BA_ "SigType" SG_ 2566575358 RMSCur 1;
BA_ "SPN" SG_ 2566575358 RMSCur 12866;
BA_ "SigType" SG_ 2566575102 CRC 12;
BA_ "SPN" SG_ 2566575102 CRC 22267;
BA_ "SigType" SG_ 2566575102 Counter 11;
BA_ "SPN" SG_ 2566575102 Counter 22266;
BA_ "SigType" SG_ 2566575102 EmbeddedIntegritySupport 5;
BA_ "SPN" SG_ 2566575102 EmbeddedIntegritySupport 22265;
BA_ "SigType" SG_ 2566575102 VSCtrlConsent 5;
BA_ "SPN" SG_ 2566575102 VSCtrlConsent 15247;
BA_ "SigType" SG_ 2566575102 TSC1CtrlPurpP7InhCmd 5;
BA_ "SPN" SG_ 2566575102 TSC1CtrlPurpP7InhCmd 12868;
BA_ "SigType" SG_ 2566574846 EngTC6OilTemp 1;
BA_ "SPN" SG_ 2566574846 EngTC6OilTemp 12892;
BA_ "SigType" SG_ 2566574846 EngTC5OilTemp 1;
BA_ "SPN" SG_ 2566574846 EngTC5OilTemp 12891;
BA_ "SigType" SG_ 2566574846 EngTC4OilTemp 1;
BA_ "SPN" SG_ 2566574846 EngTC4OilTemp 12890;
BA_ "SigType" SG_ 2566574846 EngTC3OilTemp 1;
BA_ "SPN" SG_ 2566574846 EngTC3OilTemp 12889;
BA_ "SigType" SG_ 2499465726 CylBank2TempAvg 1;
BA_ "SPN" SG_ 2499465726 CylBank2TempAvg 12896;
BA_ "SigType" SG_ 2499465726 CylBank1TempAvg 1;
BA_ "SPN" SG_ 2499465726 CylBank1TempAvg 12895;
BA_ "SigType" SG_ 2499465726 CylTempAvg 1;
BA_ "SPN" SG_ 2499465726 CylTempAvg 12894;
BA_ "SPN" SG_ 2499465470 MirrorPrimary_SecondarySelection 12925;
BA_ "SPN" SG_ 2499465470 Mirror2Left_RightSelection 12924;
BA_ "SPN" SG_ 2499465470 Mirror1Left_RightSelection 12923;
BA_ "SPN" SG_ 2566574078 CompatibilityCode 12935;
BA_ "SigType" SG_ 2566574078 InletConnectorTemp 1;
BA_ "SPN" SG_ 2566574078 InletConnectorTemp 12934;
BA_ "SigType" SG_ 2566574078 ProximityCircV 1;
BA_ "SPN" SG_ 2566574078 ProximityCircV 12933;
BA_ "SPN" SG_ 2566574078 CtrlPilotSubSt 12932;
BA_ "SPN" SG_ 2566574078 CtrlPilotSt 12931;
BA_ "SigType" SG_ 2566574078 CtrlPilotDutyCycle 1;
BA_ "SPN" SG_ 2566574078 CtrlPilotDutyCycle 12930;
BA_ "SigType" SG_ 2566574078 CtrlPilotPWMFreq 1;
BA_ "SPN" SG_ 2566574078 CtrlPilotPWMFreq 12929;
BA_ "SigType" SG_ 2566574078 CtrlPilotMinV 1;
BA_ "SPN" SG_ 2566574078 CtrlPilotMinV 12928;
BA_ "SigType" SG_ 2566574078 CtrlPilotMaxV 1;
BA_ "SPN" SG_ 2566574078 CtrlPilotMaxV 12927;
BA_ "SPN" SG_ 2566573822 TransPTOGearboxStatus 12961;
BA_ "SigType" SG_ 2566573822 TransPTOGearboxOSS 1;
BA_ "SPN" SG_ 2566573822 TransPTOGearboxOSS 12960;
BA_ "SigType" SG_ 2499464702 OutPress 1;
BA_ "SPN" SG_ 2499464702 OutPress 11775;
BA_ "SigType" SG_ 2499464702 OutAbsPress 1;
BA_ "SPN" SG_ 2499464702 OutAbsPress 11773;
BA_ "SPN" SG_ 2566572286 DamageThresholdSt 21220;
BA_ "SPN" SG_ 2566572286 GearShiftCapability 21219;
BA_ "SPN" SG_ 2566572286 LaunchCapability 21218;
BA_ "SigType" SG_ 2566572286 Clutch1OverheatInd 5;
BA_ "SPN" SG_ 2566572286 Clutch1OverheatInd 12965;
BA_ "SigType" SG_ 2566572286 Clutch1Temp 1;
BA_ "SPN" SG_ 2566572286 Clutch1Temp 5939;
BA_ "SigType" SG_ 2499462910 RoadSpdAccelerateSw 4;
BA_ "SPN" SG_ 2499462910 RoadSpdAccelerateSw 12989;
BA_ "SigType" SG_ 2499462910 RoadSpdDecelerateSw 4;
BA_ "SPN" SG_ 2499462910 RoadSpdDecelerateSw 12988;
BA_ "SigType" SG_ 2566571518 HVESSChargerNeutralRMSCur 1;
BA_ "SPN" SG_ 2566571518 HVESSChargerNeutralRMSCur 13012;
BA_ "SigType" SG_ 2566571518 HVESSChargerRMSCurL3 1;
BA_ "SPN" SG_ 2566571518 HVESSChargerRMSCurL3 13011;
BA_ "SigType" SG_ 2566571518 HVESSChargerRMSCurL2 1;
BA_ "SPN" SG_ 2566571518 HVESSChargerRMSCurL2 13010;
BA_ "SigType" SG_ 2566571518 HVESSChargerRMSCurL1 1;
BA_ "SPN" SG_ 2566571518 HVESSChargerRMSCurL1 13009;
BA_ "SPN" SG_ 2566571262 NomSupplyFreq 13008;
BA_ "SigType" SG_ 2566571262 NomRMSVLineToLine 1;
BA_ "SPN" SG_ 2566571262 NomRMSVLineToLine 13007;
BA_ "SigType" SG_ 2566571262 NomRMSVLineToNeutral 1;
BA_ "SPN" SG_ 2566571262 NomRMSVLineToNeutral 13006;
BA_ "SigType" SG_ 2566571006 SuspensionSupplyPress2 1;
BA_ "SPN" SG_ 2566571006 SuspensionSupplyPress2 13132;
BA_ "SigType" SG_ 2566571006 DryerCartridgeLifeRemaining 1;
BA_ "SPN" SG_ 2566571006 DryerCartridgeLifeRemaining 13073;
BA_ "SigType" SG_ 2566570750 TotalChargeGenerated 1;
BA_ "SPN" SG_ 2566570750 TotalChargeGenerated 13104;
BA_ "SigType" SG_ 2566570750 TotalChargeConsumed 1;
BA_ "SPN" SG_ 2566570750 TotalChargeConsumed 13103;
BA_ "SigType" SG_ 2566570750 TotalEnergyGenerated 1;
BA_ "SPN" SG_ 2566570750 TotalEnergyGenerated 13102;
BA_ "SigType" SG_ 2566570750 TotalEnergyConsumed 1;
BA_ "SPN" SG_ 2566570750 TotalEnergyConsumed 13101;
BA_ "SigType" SG_ 2566570494 TotalChargeGenerated 1;
BA_ "SPN" SG_ 2566570494 TotalChargeGenerated 13100;
BA_ "SigType" SG_ 2566570494 TotalChargeConsumed 1;
BA_ "SPN" SG_ 2566570494 TotalChargeConsumed 13099;
BA_ "SigType" SG_ 2566570494 TotalEnergyGenerated 1;
BA_ "SPN" SG_ 2566570494 TotalEnergyGenerated 13098;
BA_ "SigType" SG_ 2566570494 TotalEnergyConsumed 1;
BA_ "SPN" SG_ 2566570494 TotalEnergyConsumed 13097;
BA_ "SigType" SG_ 2566570238 TotalChargeGenerated 1;
BA_ "SPN" SG_ 2566570238 TotalChargeGenerated 13096;
BA_ "SigType" SG_ 2566570238 TotalChargeConsumed 1;
BA_ "SPN" SG_ 2566570238 TotalChargeConsumed 13095;
BA_ "SigType" SG_ 2566570238 TotalEnergyGenerated 1;
BA_ "SPN" SG_ 2566570238 TotalEnergyGenerated 13094;
BA_ "SigType" SG_ 2566570238 TotalEnergyConsumed 1;
BA_ "SPN" SG_ 2566570238 TotalEnergyConsumed 13093;
BA_ "SigType" SG_ 2566569982 TotalChargeGenerated 1;
BA_ "SPN" SG_ 2566569982 TotalChargeGenerated 13092;
BA_ "SigType" SG_ 2566569982 TotalChargeConsumed 1;
BA_ "SPN" SG_ 2566569982 TotalChargeConsumed 13091;
BA_ "SigType" SG_ 2566569982 TotalEnergyGenerated 1;
BA_ "SPN" SG_ 2566569982 TotalEnergyGenerated 13090;
BA_ "SigType" SG_ 2566569982 TotalEnergyConsumed 1;
BA_ "SPN" SG_ 2566569982 TotalEnergyConsumed 13089;
BA_ "SigType" SG_ 2566569726 TotalChargeGenerated 1;
BA_ "SPN" SG_ 2566569726 TotalChargeGenerated 13088;
BA_ "SigType" SG_ 2566569726 TotalChargeConsumed 1;
BA_ "SPN" SG_ 2566569726 TotalChargeConsumed 13087;
BA_ "SigType" SG_ 2566569726 TotalEnergyGenerated 1;
BA_ "SPN" SG_ 2566569726 TotalEnergyGenerated 13086;
BA_ "SigType" SG_ 2566569726 TotalEnergyConsumed 1;
BA_ "SPN" SG_ 2566569726 TotalEnergyConsumed 13085;
BA_ "SigType" SG_ 2566569470 TotalChargeGenerated 1;
BA_ "SPN" SG_ 2566569470 TotalChargeGenerated 13084;
BA_ "SigType" SG_ 2566569470 TotalChargeConsumed 1;
BA_ "SPN" SG_ 2566569470 TotalChargeConsumed 13083;
BA_ "SigType" SG_ 2566569470 TotalEnergyGenerated 1;
BA_ "SPN" SG_ 2566569470 TotalEnergyGenerated 13082;
BA_ "SigType" SG_ 2566569470 TotalEnergyConsumed 1;
BA_ "SPN" SG_ 2566569470 TotalEnergyConsumed 13081;
BA_ "SigType" SG_ 2566569214 TransOilPressLowLamp 4;
BA_ "SPN" SG_ 2566569214 TransOilPressLowLamp 13130;
BA_ "SigType" SG_ 2566569214 TransOilTempHiLamp 4;
BA_ "SPN" SG_ 2566569214 TransOilTempHiLamp 13129;
BA_ "SigType" SG_ 2566568958 TransOilPressLowLamp 5;
BA_ "SPN" SG_ 2566568958 TransOilPressLowLamp 13117;
BA_ "SigType" SG_ 2566568958 TransOilTempHiLamp 5;
BA_ "SPN" SG_ 2566568958 TransOilTempHiLamp 13116;
BA_ "SigType" SG_ 2566568702 HybDCInletContactor1St 5;
BA_ "SPN" SG_ 2566568702 HybDCInletContactor1St 13181;
BA_ "SigType" SG_ 2566568702 HybDCChargingBusV 1;
BA_ "SPN" SG_ 2566568702 HybDCChargingBusV 13180;
BA_ "SigType" SG_ 2566568702 HybDCContactorInputV 1;
BA_ "SPN" SG_ 2566568702 HybDCContactorInputV 13179;
BA_ "SigType" SG_ 2566568446 HybDCInletContactor1Cmd 5;
BA_ "SPN" SG_ 2566568446 HybDCInletContactor1Cmd 13178;
BA_ "SPN" SG_ 2566568190 RespCode 21089;
BA_ "SigType" SG_ 2566568190 ProcessingSt 4;
BA_ "SPN" SG_ 2566568190 ProcessingSt 21088;
BA_ "SPN" SG_ 2566568190 IsolStatus 21087;
BA_ "SPN" SG_ 2566568190 Status 13177;
BA_ "SigType" SG_ 2566568190 PLAchieved 4;
BA_ "SPN" SG_ 2566568190 PLAchieved 13176;
BA_ "SigType" SG_ 2566568190 CurLmtAchieved 4;
BA_ "SPN" SG_ 2566568190 CurLmtAchieved 13175;
BA_ "SigType" SG_ 2566568190 VLmtAchieved 4;
BA_ "SPN" SG_ 2566568190 VLmtAchieved 13174;
BA_ "SigType" SG_ 2566568190 PresentDCChargingCur 1;
BA_ "SPN" SG_ 2566568190 PresentDCChargingCur 13173;
BA_ "SigType" SG_ 2566568190 PresentDCChargingV 1;
BA_ "SPN" SG_ 2566568190 PresentDCChargingV 13172;
BA_ "SPN" SG_ 2566568190 ChargingSt 13171;
BA_ "SigType" SG_ 2566567934 TargetChargingCur 1;
BA_ "SPN" SG_ 2566567934 TargetChargingCur 13170;
BA_ "SigType" SG_ 2566567934 TargetChargingV 1;
BA_ "SPN" SG_ 2566567934 TargetChargingV 13169;
BA_ "SigType" SG_ 2566567934 SequenceCounter 11;
BA_ "SPN" SG_ 2566567934 SequenceCounter 13168;
BA_ "SigType" SG_ 2566567934 CRC 12;
BA_ "SPN" SG_ 2566567934 CRC 13167;
BA_ "SigType" SG_ 2566567678 CurRegulationTolerance 1;
BA_ "SPN" SG_ 2566567678 CurRegulationTolerance 13166;
BA_ "SigType" SG_ 2566567678 PeakCurRipple 1;
BA_ "SPN" SG_ 2566567678 PeakCurRipple 13165;
BA_ "SigType" SG_ 2566567678 DCChargingCurMin 1;
BA_ "SPN" SG_ 2566567678 DCChargingCurMin 13164;
BA_ "SigType" SG_ 2566567678 DCChargingVMin 1;
BA_ "SPN" SG_ 2566567678 DCChargingVMin 13163;
BA_ "SPN" SG_ 2566567422 SupportedEnergyTransferTypes 13162;
BA_ "SigType" SG_ 2566567422 DCChargingPwrMax 1;
BA_ "SPN" SG_ 2566567422 DCChargingPwrMax 13161;
BA_ "SigType" SG_ 2566567422 DCChargingCurMax 1;
BA_ "SPN" SG_ 2566567422 DCChargingCurMax 13160;
BA_ "SigType" SG_ 2566567422 DCChargingVMax 1;
BA_ "SPN" SG_ 2566567422 DCChargingVMax 13159;
BA_ "SPN" SG_ 2566567166 HybReqEnergyTransferType 13158;
BA_ "SigType" SG_ 2566567166 HybDCChargingPwrMax 1;
BA_ "SPN" SG_ 2566567166 HybDCChargingPwrMax 13157;
BA_ "SigType" SG_ 2566567166 HybDCChargingCurMax 1;
BA_ "SPN" SG_ 2566567166 HybDCChargingCurMax 13156;
BA_ "SigType" SG_ 2566567166 HybDCChargingVMax 1;
BA_ "SPN" SG_ 2566567166 HybDCChargingVMax 13155;
BA_ "SigType" SG_ 2633675518 TotalEnergyOut 1;
BA_ "SPN" SG_ 2633675518 TotalEnergyOut 14168;
BA_ "SigType" SG_ 2633675518 TotalEnergyInput 1;
BA_ "SPN" SG_ 2633675518 TotalEnergyInput 14167;
BA_ "SigType" SG_ 2633675518 TotalAccumulatedCharge 1;
BA_ "SPN" SG_ 2633675518 TotalAccumulatedCharge 14166;
BA_ "SigType" SG_ 2633675518 TotalEnergyThroughput 1;
BA_ "SPN" SG_ 2633675518 TotalEnergyThroughput 14165;
BA_ "SigType" SG_ 2633675518 ContactorOpenUnderLoadCount 1;
BA_ "SPN" SG_ 2633675518 ContactorOpenUnderLoadCount 14164;
BA_ "SigType" SG_ 2633675518 StOfHealth 1;
BA_ "SPN" SG_ 2633675518 StOfHealth 14163;
BA_ "SPN" SG_ 2566566398 NomRatedCapacity 15255;
BA_ "SigType" SG_ 2566566398 CellMinVLmt 1;
BA_ "SPN" SG_ 2566566398 CellMinVLmt 14179;
BA_ "SigType" SG_ 2566566398 CellMaxVLmt 1;
BA_ "SPN" SG_ 2566566398 CellMaxVLmt 14178;
BA_ "SigType" SG_ 2566566398 RecommendedMinOperatingTemp 1;
BA_ "SPN" SG_ 2566566398 RecommendedMinOperatingTemp 14177;
BA_ "SigType" SG_ 2566566398 RecommendedMaxOperatingTemp 1;
BA_ "SPN" SG_ 2566566398 RecommendedMaxOperatingTemp 14176;
BA_ "SigType" SG_ 2566566398 RecommendedMaxStOfCharge 1;
BA_ "SPN" SG_ 2566566398 RecommendedMaxStOfCharge 14175;
BA_ "SigType" SG_ 2566566398 RecommendedMinStOfCharge 1;
BA_ "SPN" SG_ 2566566398 RecommendedMinStOfCharge 14174;
BA_ "SigType" SG_ 2566566398 RecommendedMaxOperatingV 1;
BA_ "SPN" SG_ 2566566398 RecommendedMaxOperatingV 14173;
BA_ "SigType" SG_ 2566566398 RecommendedMinOperatingV 1;
BA_ "SPN" SG_ 2566566398 RecommendedMinOperatingV 14172;
BA_ "SigType" SG_ 2566566398 NomV 1;
BA_ "SPN" SG_ 2566566398 NomV 14171;
BA_ "SigType" SG_ 2633675006 TotalEnergyOut 1;
BA_ "SPN" SG_ 2633675006 TotalEnergyOut 14311;
BA_ "SigType" SG_ 2633675006 TotalEnergyInput 1;
BA_ "SPN" SG_ 2633675006 TotalEnergyInput 14310;
BA_ "SigType" SG_ 2633675006 TotalAccumulatedCharge 1;
BA_ "SPN" SG_ 2633675006 TotalAccumulatedCharge 14309;
BA_ "SigType" SG_ 2633675006 TotalEnergyThroughput 1;
BA_ "SPN" SG_ 2633675006 TotalEnergyThroughput 14308;
BA_ "SigType" SG_ 2633675006 ContactorOpenUnderLoadCount 1;
BA_ "SPN" SG_ 2633675006 ContactorOpenUnderLoadCount 14307;
BA_ "SigType" SG_ 2633675006 StOfHealth 1;
BA_ "SPN" SG_ 2633675006 StOfHealth 14306;
BA_ "SPN" SG_ 2566565886 NomRatedCapacity 15254;
BA_ "SigType" SG_ 2566565886 CellMinVLmt 1;
BA_ "SPN" SG_ 2566565886 CellMinVLmt 14322;
BA_ "SigType" SG_ 2566565886 CellMaxVLmt 1;
BA_ "SPN" SG_ 2566565886 CellMaxVLmt 14321;
BA_ "SigType" SG_ 2566565886 RecommendedMinOperatingTemp 1;
BA_ "SPN" SG_ 2566565886 RecommendedMinOperatingTemp 14320;
BA_ "SigType" SG_ 2566565886 RecommendedMaxOperatingTemp 1;
BA_ "SPN" SG_ 2566565886 RecommendedMaxOperatingTemp 14319;
BA_ "SigType" SG_ 2566565886 RecommendedMaxStOfCharge 1;
BA_ "SPN" SG_ 2566565886 RecommendedMaxStOfCharge 14318;
BA_ "SigType" SG_ 2566565886 RecommendedMinStOfCharge 1;
BA_ "SPN" SG_ 2566565886 RecommendedMinStOfCharge 14317;
BA_ "SigType" SG_ 2566565886 RecommendedMaxOperatingV 1;
BA_ "SPN" SG_ 2566565886 RecommendedMaxOperatingV 14316;
BA_ "SigType" SG_ 2566565886 RecommendedMinOperatingV 1;
BA_ "SPN" SG_ 2566565886 RecommendedMinOperatingV 14315;
BA_ "SigType" SG_ 2566565886 NomV 1;
BA_ "SPN" SG_ 2566565886 NomV 14314;
BA_ "SigType" SG_ 2633674494 TotalEnergyOut 1;
BA_ "SPN" SG_ 2633674494 TotalEnergyOut 14454;
BA_ "SigType" SG_ 2633674494 TotalEnergyInput 1;
BA_ "SPN" SG_ 2633674494 TotalEnergyInput 14453;
BA_ "SigType" SG_ 2633674494 TotalAccumulatedCharge 1;
BA_ "SPN" SG_ 2633674494 TotalAccumulatedCharge 14452;
BA_ "SigType" SG_ 2633674494 TotalEnergyThroughput 1;
BA_ "SPN" SG_ 2633674494 TotalEnergyThroughput 14451;
BA_ "SigType" SG_ 2633674494 ContactorOpenUnderLoadCount 1;
BA_ "SPN" SG_ 2633674494 ContactorOpenUnderLoadCount 14450;
BA_ "SigType" SG_ 2633674494 StOfHealth 1;
BA_ "SPN" SG_ 2633674494 StOfHealth 14449;
BA_ "SPN" SG_ 2566565374 NomRatedCapacity 15253;
BA_ "SigType" SG_ 2566565374 CellMinVLmt 1;
BA_ "SPN" SG_ 2566565374 CellMinVLmt 14465;
BA_ "SigType" SG_ 2566565374 CellMaxVLmt 1;
BA_ "SPN" SG_ 2566565374 CellMaxVLmt 14464;
BA_ "SigType" SG_ 2566565374 RecommendedMinOperatingTemp 1;
BA_ "SPN" SG_ 2566565374 RecommendedMinOperatingTemp 14463;
BA_ "SigType" SG_ 2566565374 RecommendedMaxOperatingTemp 1;
BA_ "SPN" SG_ 2566565374 RecommendedMaxOperatingTemp 14462;
BA_ "SigType" SG_ 2566565374 RecommendedMaxStOfCharge 1;
BA_ "SPN" SG_ 2566565374 RecommendedMaxStOfCharge 14461;
BA_ "SigType" SG_ 2566565374 RecommendedMinStOfCharge 1;
BA_ "SPN" SG_ 2566565374 RecommendedMinStOfCharge 14460;
BA_ "SigType" SG_ 2566565374 RecommendedMaxOperatingV 1;
BA_ "SPN" SG_ 2566565374 RecommendedMaxOperatingV 14459;
BA_ "SigType" SG_ 2566565374 RecommendedMinOperatingV 1;
BA_ "SPN" SG_ 2566565374 RecommendedMinOperatingV 14458;
BA_ "SigType" SG_ 2566565374 NomV 1;
BA_ "SPN" SG_ 2566565374 NomV 14457;
BA_ "SigType" SG_ 2633673982 TotalEnergyOut 1;
BA_ "SPN" SG_ 2633673982 TotalEnergyOut 14597;
BA_ "SigType" SG_ 2633673982 TotalEnergyInput 1;
BA_ "SPN" SG_ 2633673982 TotalEnergyInput 14596;
BA_ "SigType" SG_ 2633673982 TotalAccumulatedCharge 1;
BA_ "SPN" SG_ 2633673982 TotalAccumulatedCharge 14595;
BA_ "SigType" SG_ 2633673982 TotalEnergyThroughput 1;
BA_ "SPN" SG_ 2633673982 TotalEnergyThroughput 14594;
BA_ "SigType" SG_ 2633673982 ContactorOpenUnderLoadCount 1;
BA_ "SPN" SG_ 2633673982 ContactorOpenUnderLoadCount 14593;
BA_ "SigType" SG_ 2633673982 StOfHealth 1;
BA_ "SPN" SG_ 2633673982 StOfHealth 14592;
BA_ "SPN" SG_ 2566564862 NomRatedCapacity 15252;
BA_ "SigType" SG_ 2566564862 CellMinVLmt 1;
BA_ "SPN" SG_ 2566564862 CellMinVLmt 14608;
BA_ "SigType" SG_ 2566564862 CellMaxVLmt 1;
BA_ "SPN" SG_ 2566564862 CellMaxVLmt 14607;
BA_ "SigType" SG_ 2566564862 RecommendedMinOperatingTemp 1;
BA_ "SPN" SG_ 2566564862 RecommendedMinOperatingTemp 14606;
BA_ "SigType" SG_ 2566564862 RecommendedMaxOperatingTemp 1;
BA_ "SPN" SG_ 2566564862 RecommendedMaxOperatingTemp 14605;
BA_ "SigType" SG_ 2566564862 RecommendedMaxStOfCharge 1;
BA_ "SPN" SG_ 2566564862 RecommendedMaxStOfCharge 14604;
BA_ "SigType" SG_ 2566564862 RecommendedMinStOfCharge 1;
BA_ "SPN" SG_ 2566564862 RecommendedMinStOfCharge 14603;
BA_ "SigType" SG_ 2566564862 RecommendedMaxOperatingV 1;
BA_ "SPN" SG_ 2566564862 RecommendedMaxOperatingV 14602;
BA_ "SigType" SG_ 2566564862 RecommendedMinOperatingV 1;
BA_ "SPN" SG_ 2566564862 RecommendedMinOperatingV 14601;
BA_ "SigType" SG_ 2566564862 NomV 1;
BA_ "SPN" SG_ 2566564862 NomV 14600;
BA_ "SigType" SG_ 2364690430 ActualChargeRate 1;
BA_ "SPN" SG_ 2364690430 ActualChargeRate 14591;
BA_ "SigType" SG_ 2364690430 LvlNegToChassisGroundV 1;
BA_ "SPN" SG_ 2364690430 LvlNegToChassisGroundV 14590;
BA_ "SigType" SG_ 2364690430 BusVNegToChassisGroundV 1;
BA_ "SPN" SG_ 2364690430 BusVNegToChassisGroundV 14589;
BA_ "SigType" SG_ 2364690174 HVBusPassiveIsolTestResults 1;
BA_ "SPN" SG_ 2364690174 HVBusPassiveIsolTestResults 14588;
BA_ "SigType" SG_ 2364690174 HVBusActiveIsolTestResults 1;
BA_ "SPN" SG_ 2364690174 HVBusActiveIsolTestResults 14587;
BA_ "SigType" SG_ 2364690174 LowestCellStOfChargeCellNum 1;
BA_ "SPN" SG_ 2364690174 LowestCellStOfChargeCellNum 14586;
BA_ "SigType" SG_ 2364690174 LowestCellStOfChargeModuleNum 1;
BA_ "SPN" SG_ 2364690174 LowestCellStOfChargeModuleNum 14585;
BA_ "SigType" SG_ 2364690174 HighestCellStOfChargeCellNum 1;
BA_ "SPN" SG_ 2364690174 HighestCellStOfChargeCellNum 14584;
BA_ "SigType" SG_ 2364690174 HighestCellStOfChargeModuleNum 1;
BA_ "SPN" SG_ 2364690174 HighestCellStOfChargeModuleNum 14583;
BA_ "SigType" SG_ 2364689918 Data9CRC 12;
BA_ "SPN" SG_ 2364689918 Data9CRC 23003;
BA_ "SigType" SG_ 2364689918 Data9Counter 11;
BA_ "SPN" SG_ 2364689918 Data9Counter 23002;
BA_ "SigType" SG_ 2364689918 Data9EmbeddedIntegritySupport 5;
BA_ "SPN" SG_ 2364689918 Data9EmbeddedIntegritySupport 23001;
BA_ "SigType" SG_ 2364689918 HVESS10ThermalEventDetected 4;
BA_ "SPN" SG_ 2364689918 HVESS10ThermalEventDetected 21297;
BA_ "SigType" SG_ 2364689918 LowestCellTempCellNum 1;
BA_ "SPN" SG_ 2364689918 LowestCellTempCellNum 14582;
BA_ "SigType" SG_ 2364689918 LowestCellTempModuleNum 1;
BA_ "SPN" SG_ 2364689918 LowestCellTempModuleNum 14581;
BA_ "SigType" SG_ 2364689918 HighestCellTempCellNum 1;
BA_ "SPN" SG_ 2364689918 HighestCellTempCellNum 14580;
BA_ "SigType" SG_ 2364689918 HighestCellTempModuleNum 1;
BA_ "SPN" SG_ 2364689918 HighestCellTempModuleNum 14579;
BA_ "SigType" SG_ 2364689662 AvgCellV 1;
BA_ "SPN" SG_ 2364689662 AvgCellV 14578;
BA_ "SigType" SG_ 2364689662 LowestCellVCellNum 1;
BA_ "SPN" SG_ 2364689662 LowestCellVCellNum 14577;
BA_ "SigType" SG_ 2364689662 LowestCellVModuleNum 1;
BA_ "SPN" SG_ 2364689662 LowestCellVModuleNum 14576;
BA_ "SigType" SG_ 2364689662 HighestCellVCellNum 1;
BA_ "SPN" SG_ 2364689662 HighestCellVCellNum 14575;
BA_ "SigType" SG_ 2364689662 HighestCellVModuleNum 1;
BA_ "SPN" SG_ 2364689662 HighestCellVModuleNum 14574;
BA_ "SigType" SG_ 2364689406 TMSCoolantLvl 4;
BA_ "SPN" SG_ 2364689406 TMSCoolantLvl 14573;
BA_ "SPN" SG_ 2364689406 TMSMode 14572;
BA_ "SigType" SG_ 2364689406 TMSHVILStatus 4;
BA_ "SPN" SG_ 2364689406 TMSHVILStatus 14571;
BA_ "SigType" SG_ 2364689406 TMSHtrStatus 5;
BA_ "SPN" SG_ 2364689406 TMSHtrStatus 14570;
BA_ "SigType" SG_ 2364689406 TMSRelHumidty 1;
BA_ "SPN" SG_ 2364689406 TMSRelHumidty 14569;
BA_ "SigType" SG_ 2364689406 TMSCompressorSpd 1;
BA_ "SPN" SG_ 2364689406 TMSCompressorSpd 14568;
BA_ "SigType" SG_ 2364689406 TMSHVInputPwr 1;
BA_ "SPN" SG_ 2364689406 TMSHVInputPwr 14567;
BA_ "SigType" SG_ 2364689406 TMSSLIInputPwr 1;
BA_ "SPN" SG_ 2364689406 TMSSLIInputPwr 14566;
BA_ "SigType" SG_ 2364689150 Module32OperationalStatus 5;
BA_ "SPN" SG_ 2364689150 Module32OperationalStatus 14565;
BA_ "SigType" SG_ 2364689150 Module31OperationalStatus 5;
BA_ "SPN" SG_ 2364689150 Module31OperationalStatus 14564;
BA_ "SigType" SG_ 2364689150 Module30OperationalStatus 5;
BA_ "SPN" SG_ 2364689150 Module30OperationalStatus 14563;
BA_ "SigType" SG_ 2364689150 Module29OperationalStatus 5;
BA_ "SPN" SG_ 2364689150 Module29OperationalStatus 14562;
BA_ "SigType" SG_ 2364689150 Module28OperationalStatus 5;
BA_ "SPN" SG_ 2364689150 Module28OperationalStatus 14561;
BA_ "SigType" SG_ 2364689150 Module27OperationalStatus 5;
BA_ "SPN" SG_ 2364689150 Module27OperationalStatus 14560;
BA_ "SigType" SG_ 2364689150 Module26OperationalStatus 5;
BA_ "SPN" SG_ 2364689150 Module26OperationalStatus 14559;
BA_ "SigType" SG_ 2364689150 Module25OperationalStatus 5;
BA_ "SPN" SG_ 2364689150 Module25OperationalStatus 14558;
BA_ "SigType" SG_ 2364689150 Module24OperationalStatus 5;
BA_ "SPN" SG_ 2364689150 Module24OperationalStatus 14557;
BA_ "SigType" SG_ 2364689150 Module23OperationalStatus 5;
BA_ "SPN" SG_ 2364689150 Module23OperationalStatus 14556;
BA_ "SigType" SG_ 2364689150 Module22OperationalStatus 5;
BA_ "SPN" SG_ 2364689150 Module22OperationalStatus 14555;
BA_ "SigType" SG_ 2364689150 Module21OperationalStatus 5;
BA_ "SPN" SG_ 2364689150 Module21OperationalStatus 14554;
BA_ "SigType" SG_ 2364689150 Module20OperationalStatus 5;
BA_ "SPN" SG_ 2364689150 Module20OperationalStatus 14553;
BA_ "SigType" SG_ 2364689150 Module19OperationalStatus 5;
BA_ "SPN" SG_ 2364689150 Module19OperationalStatus 14552;
BA_ "SigType" SG_ 2364689150 Module18OperationalStatus 5;
BA_ "SPN" SG_ 2364689150 Module18OperationalStatus 14551;
BA_ "SigType" SG_ 2364689150 Module17OperationalStatus 5;
BA_ "SPN" SG_ 2364689150 Module17OperationalStatus 14550;
BA_ "SigType" SG_ 2364689150 Module16OperationalStatus 5;
BA_ "SPN" SG_ 2364689150 Module16OperationalStatus 14549;
BA_ "SigType" SG_ 2364689150 Module15OperationalStatus 5;
BA_ "SPN" SG_ 2364689150 Module15OperationalStatus 14548;
BA_ "SigType" SG_ 2364689150 Module14OperationalStatus 5;
BA_ "SPN" SG_ 2364689150 Module14OperationalStatus 14547;
BA_ "SigType" SG_ 2364689150 Module13OperationalStatus 5;
BA_ "SPN" SG_ 2364689150 Module13OperationalStatus 14546;
BA_ "SigType" SG_ 2364689150 Module12OperationalStatus 5;
BA_ "SPN" SG_ 2364689150 Module12OperationalStatus 14545;
BA_ "SigType" SG_ 2364689150 Module11OperationalStatus 5;
BA_ "SPN" SG_ 2364689150 Module11OperationalStatus 14544;
BA_ "SigType" SG_ 2364689150 Module10OperationalStatus 5;
BA_ "SPN" SG_ 2364689150 Module10OperationalStatus 14543;
BA_ "SigType" SG_ 2364689150 Module9OperationalStatus 5;
BA_ "SPN" SG_ 2364689150 Module9OperationalStatus 14542;
BA_ "SigType" SG_ 2364689150 Module8OperationalStatus 5;
BA_ "SPN" SG_ 2364689150 Module8OperationalStatus 14541;
BA_ "SigType" SG_ 2364689150 Module7OperationalStatus 5;
BA_ "SPN" SG_ 2364689150 Module7OperationalStatus 14540;
BA_ "SigType" SG_ 2364689150 Module6OperationalStatus 5;
BA_ "SPN" SG_ 2364689150 Module6OperationalStatus 14539;
BA_ "SigType" SG_ 2364689150 Module5OperationalStatus 5;
BA_ "SPN" SG_ 2364689150 Module5OperationalStatus 14538;
BA_ "SigType" SG_ 2364689150 Module4OperationalStatus 5;
BA_ "SPN" SG_ 2364689150 Module4OperationalStatus 14537;
BA_ "SigType" SG_ 2364689150 Module3OperationalStatus 5;
BA_ "SPN" SG_ 2364689150 Module3OperationalStatus 14536;
BA_ "SigType" SG_ 2364689150 Module2OperationalStatus 5;
BA_ "SPN" SG_ 2364689150 Module2OperationalStatus 14535;
BA_ "SigType" SG_ 2364689150 Module1OperationalStatus 5;
BA_ "SPN" SG_ 2364689150 Module1OperationalStatus 14534;
BA_ "SigType" SG_ 2364688894 MaxChargeVLmt 1;
BA_ "SPN" SG_ 2364688894 MaxChargeVLmt 14533;
BA_ "SPN" SG_ 2364688894 ChargeEnergyCapacity 14532;
BA_ "SPN" SG_ 2364688894 DisEnergyCapacity 14531;
VAL_ 2349858558 ThermalMnmgtMaintenanceReq 3 "Don't care/take no action" 2 "Reserved" 1 "HVESS Thermal Management Maintenance Mode is requested" 0 "HVESS Thermal Management Maintenance Mode is not requested" ;
VAL_ 2349858558 HVBusLowSideResistorConnectReq 3 "Don't care/take no action" 2 "Reserved" 1 "Connection Requested" 0 "Connection not Requested" ;
VAL_ 2349858558 HVBusHiSideResistorConnectReq 3 "Don't care/take no action" 2 "Reserved" 1 "Connection Requested" 0 "Connection not Requested" ;
VAL_ 2349858558 OpConsent 3 "Don't care/Take no action" 2 "Error" 1 "Consent given" 0 "Consent revoked" ;
VAL_ 2349858558 EnableInternalChargerCmd 3 "Don't care/Take no action" 2 "Reserved" 1 "Enable charging" 0 "Disable charging" ;
VAL_ 2349858558 CellBalancingCmd 3 "Don't care/Take no action" 2 "Reserved" 1 "Cell Balancing requested" 0 "Cell Balancing not requested" ;
VAL_ 2349858558 HVBusPassiveIsolTestCmd 3 "Don't care/Take no action" 2 "Reserved" 1 "Passive Isolation Test request" 0 "Passive Isolation Test not requested" ;
VAL_ 2349858558 HVBusActiveIsolTestCmd 3 "Don't care/Take no action" 2 "Reserved" 1 "Active Isolation Test request" 0 "Active Isolation Test not requested" ;
VAL_ 2349858558 PwrDownCmd 3 "Don't care/Take no action" 2 "Execute emergency power-down" 1 "Execute normal power-down" 0 "Power-down not requested" ;
VAL_ 2349858558 HVBusConnectCmd 3 "Don't care/Take no action" 2 "Emergency contactor closure request" 1 "Close Contactor" 0 "Open Contactor" ;
VAL_ 2148466430 InvertedPF 129 "orig: 126 / 0x7E" 255 "orig: 0 / 0x0" 254 "orig: 1 / 0x1" 253 "orig: 2 / 0x2" 252 "orig: 3 / 0x3" 251 "orig: 4 / 0x4" 250 "orig: 5 / 0x5" 249 "orig: 6 / 0x6" 248 "orig: 7 / 0x7" 247 "orig: 8 / 0x8" 246 "orig: 9 / 0x9" 245 "orig: 10 / 0xA" 244 "orig: 11 / 0xB" 243 "orig: 12 / 0xC" 242 "orig: 13 / 0xD" 241 "orig: 14 / 0xE" 240 "orig: 15 / 0xF" 239 "orig: 16 / 0x10" 238 "orig: 17 / 0x11" 237 "orig: 17 / 0x12" 236 "orig: 19 / 0x13" 235 "orig: 20 / 0x14" 234 "orig: 21 / 0x15" 233 "orig: 22 / 0x16" 232 "orig: 23 / 0x17" 231 "orig: 24 / 0x18" 230 "orig: 25 / 0x19" 229 "orig: 26 / 0x1A" 228 "orig: 27 / 0x1B" 227 "orig: 28 / 0x1C" 226 "orig: 29 / 0x1D" 225 "orig: 30 / 0x1E" 224 "orig: 31 / 0x1F" 223 "orig: 32 / 0x20" 222 "orig: 33 / 0x21" 221 "orig: 34 / 0x22" 220 "orig: 35 / 0x23" 219 "orig: 36 / 0x24" 218 "orig: 37 / 0x25" 217 "orig: 38 / 0x26" 216 "orig: 39 / 0x27" 215 "orig: 40 / 0x28" 214 "orig: 41 / 0x29" 213 "orig: 42 / 0x2A" 212 "orig: 43 / 0x2B" 211 "orig: 44 / 0x2C" 210 "orig: 45 / 0x2D" 209 "orig: 46 / 0x2E" 208 "orig: 47 / 0x2F" 207 "orig: 48 / 0x30" 206 "orig: 49 / 0x31" 205 "orig: 50 / 0x32" 204 "orig: 51 / 0x33" 203 "orig: 52 / 0x34" 202 "orig: 53 / 0x35" 201 "orig: 54 / 0x36" 200 "orig: 55 / 0x37" 199 "orig: 56 / 0x38" 198 "orig: 57 / 0x39" 197 "orig: 58 / 0x3A" 196 "orig: 59 / 0x3B" 195 "orig: 60 / 0x3C" 194 "orig: 61 / 0x3D" 193 "orig: 62 / 0x3E" 192 "orig: 63 / 0x3F" 191 "orig: 64 / 0x40" 190 "orig: 65 / 0x41" 189 "orig: 66 / 0x42" 188 "orig: 67 / 0x43" 187 "orig: 68 / 0x44" 186 "orig: 69 / 0x45" 185 "orig: 70 / 0x46" 184 "orig: 71 / 0x47" 183 "orig: 72 / 0x48" 182 "orig: 73 / 0x49" 181 "orig: 74 / 0x4A" 180 "orig: 75 / 0x4B" 179 "orig: 76 / 0x4C" 178 "orig: 77 / 0x4D" 177 "orig: 78 / 0x4E" 176 "orig: 79 / 0x4F" 175 "orig: 80 / 0x50" 174 "orig: 81 / 0x51" 173 "orig: 82 / 0x52" 172 "orig: 83 / 0x53" 171 "orig: 84 / 0x54" 170 "orig: 85 / 0x55" 169 "orig: 86 / 0x56" 168 "orig: 87 / 0x57" 167 "orig: 88 / 0x58" 166 "orig: 89 / 0x59" 165 "orig: 90 / 0x5A" 164 "orig: 91 / 0x5B" 163 "orig: 92 / 0x5C" 162 "orig: 93 / 0x5D" 161 "orig: 94 / 0x5E" 160 "orig: 95 / 0x5F" 159 "orig: 96 / 0x60" 158 "orig: 97 / 0x61" 157 "orig: 98 / 0x62" 156 "orig: 99 / 0x63" 155 "orig: 100 / 0x64" 154 "orig: 101 / 0x65" 153 "orig: 102 / 0x66" 152 "orig: 103 / 0x67" 151 "orig: 104 / 0x68" 150 "orig: 105 / 0x69" 149 "orig: 106 / 0x6A" 148 "orig: 107 / 0x6B" 147 "orig: 108 / 0x6C" 146 "orig: 109 / 0x6D" 145 "orig: 110 / 0x6E" 144 "orig: 111 / 0x6F" 143 "orig: 112 / 0x70" 142 "orig: 113 / 0x71" 141 "orig: 114 / 0x72" 140 "orig: 115 / 0x73" 139 "orig: 116 / 0x74" 138 "orig: 117 / 0x75" 137 "orig: 118 / 0x76" 136 "orig: 119 / 0x77" 135 "orig: 120 / 0x78" 134 "orig: 121 / 0x79" 133 "orig: 122 / 0x7A" 132 "orig: 123 / 0x7B" 131 "orig: 124 / 0x7C" 130 "orig: 125 / 0x7D" 128 "orig: 127 / 0x7F" 127 "orig: 128 / 0x80" 126 "orig: 129 / 0x81" 125 "orig: 130 / 0x82" 124 "orig: 131 / 0x83" 123 "orig: 132 / 0x84" 122 "orig: 133 / 0x85" 121 "orig: 134 / 0x86" 120 "orig: 135 / 0x87" 119 "orig: 136 / 0x88" 118 "orig: 137 / 0x89" 117 "orig: 138 / 0x8A" 116 "orig: 139 / 0x8B" 115 "orig: 140 / 0x8C" 114 "orig: 141 / 0x8D" 113 "orig: 142 / 0x8E" 112 "orig: 143 / 0x8F" 111 "orig: 144 / 0x90" 110 "orig: 145 / 0x91" 109 "orig: 146 / 0x92" 108 "orig: 147 / 0x93" 107 "orig: 148 / 0x94" 106 "orig: 149 / 0x95" 105 "orig: 150 / 0x96" 104 "orig: 151 / 0x97" 103 "orig: 152 / 0x98" 102 "orig: 153 / 0x99" 101 "orig: 154 / 0x9A" 100 "orig: 155 / 0x9B" 99 "orig: 156 / 0x9C" 98 "orig: 157 / 0x9D" 97 "orig: 158 / 0x9E" 96 "orig: 159 / 0x9F" 95 "orig: 160 / 0xA0" 94 "orig: 161 / 0xA1" 93 "orig: 162 / 0xA2" 92 "orig: 163 / 0xA3" 91 "orig: 164 / 0xA4" 90 "orig: 165 / 0xA5" 89 "orig: 166 / 0xA6" 88 "orig: 167 / 0xA7" 87 "orig: 168 / 0xA8" 86 "orig: 169 / 0xA9" 85 "orig: 170 / 0xAA" 84 "orig: 171 / 0xAB" 83 "orig: 172 / 0xAC" 82 "orig: 173 / 0xAD" 81 "orig: 174 / 0xAE" 80 "orig: 175 / 0xAF" 79 "orig: 176 / 0xB0" 78 "orig: 177 / 0xB1" 77 "orig: 178 / 0xB2" 76 "orig: 179 / 0xB3" 75 "orig: 180 / 0xB4" 74 "orig: 181 / 0xB5" 73 "orig: 182 / 0xB6" 72 "orig: 183 / 0xB7" 71 "orig: 184 / 0xB8" 70 "orig: 185 / 0xB9" 69 "orig: 186 / 0xBA" 68 "orig: 187 / 0xBB" 67 "orig: 188 / 0xBC" 66 "orig: 189 / 0xBD" 65 "orig: 190 / 0xBE" 64 "orig: 191 / 0xBF" 63 "orig: 192 / 0xC0" 62 "orig: 193 / 0xC1" 61 "orig: 194 / 0xC2" 60 "orig: 195 / 0xC3" 59 "orig: 196 / 0xC4" 58 "orig: 197 / 0xC5" 57 "orig: 198 / 0xC6" 56 "orig: 199 / 0xC7" 55 "orig: 200 / 0xC8" 54 "orig: 201 / 0xC9" 53 "orig: 202 / 0xCA" 52 "orig: 203 / 0xCB" 51 "orig: 204 / 0xCC" 50 "orig: 205 / 0xCD" 49 "orig: 206 / 0xCE" 48 "orig: 207 / 0xCF" 47 "orig: 208 / 0xD0" 46 "orig: 209 / 0xD1" 45 "orig: 210 / 0xD2" 44 "orig: 211 / 0xD3" 43 "orig: 212 / 0xD4" 42 "orig: 213 / 0xD5" 41 "orig: 214 / 0xD6" 40 "orig: 215 / 0xD7" 39 "orig: 216 / 0xD8" 38 "orig: 217 / 0xD9" 37 "orig: 218 / 0xDA" 36 "orig: 219 / 0xDB" 35 "orig: 220 / 0xDC" 34 "orig: 221 / 0xDD" 33 "orig: 222 / 0xDE" 32 "orig: 223 / 0xDF" 31 "orig: 224 / 0xE0" 30 "orig: 225 / 0xE1" 29 "orig: 226 / 0xE2" 28 "orig: 227 / 0xE3" 27 "orig: 228 / 0xE4" 26 "orig: 229 / 0xE5" 25 "orig: 230 / 0xE6" 24 "orig: 231 / 0xE7" 23 "orig: 232 / 0xE8" 22 "orig: 233 / 0xE9" 21 "orig: 234 / 0xEA" 20 "orig: 235 / 0xEB" 19 "orig: 236 / 0xEC" 18 "orig: 237 / 0xED" 17 "orig: 238 / 0xEE" 16 "orig: 239 / 0xEF" 15 "orig: 240 / 0xF0" 14 "orig: 241 / 0xF1" 13 "orig: 242 / 0xF2" 12 "orig: 243 / 0xF3" 11 "orig: 244 / 0xF4" 10 "orig: 245 / 0xF5" 9 "orig: 246 / 0xF6" 8 "orig: 247 / 0xF7" 7 "orig: 248 / 0xF8" 6 "orig: 249 / 0xF9" 5 "orig: 250 / 0xFA" 4 "orig: 251 / 0xFB" 3 "orig: 252 / 0xFC" 2 "orig: 253 / 0xFD" 1 "orig: 254 / 0xFE" 0 "orig: 255 / 0xFF" ;
VAL_ 2148466430 InvertedPS 129 "orig: 126 / 0x7E" 255 "orig: 0 / 0x0" 254 "orig: 1 / 0x1" 253 "orig: 2 / 0x2" 252 "orig: 3 / 0x3" 251 "orig: 4 / 0x4" 250 "orig: 5 / 0x5" 249 "orig: 6 / 0x6" 248 "orig: 7 / 0x7" 247 "orig: 8 / 0x8" 246 "orig: 9 / 0x9" 245 "orig: 10 / 0xA" 244 "orig: 11 / 0xB" 243 "orig: 12 / 0xC" 242 "orig: 13 / 0xD" 241 "orig: 14 / 0xE" 240 "orig: 15 / 0xF" 239 "orig: 16 / 0x10" 238 "orig: 17 / 0x11" 237 "orig: 17 / 0x12" 236 "orig: 19 / 0x13" 235 "orig: 20 / 0x14" 234 "orig: 21 / 0x15" 233 "orig: 22 / 0x16" 232 "orig: 23 / 0x17" 231 "orig: 24 / 0x18" 230 "orig: 25 / 0x19" 229 "orig: 26 / 0x1A" 228 "orig: 27 / 0x1B" 227 "orig: 28 / 0x1C" 226 "orig: 29 / 0x1D" 225 "orig: 30 / 0x1E" 224 "orig: 31 / 0x1F" 223 "orig: 32 / 0x20" 222 "orig: 33 / 0x21" 221 "orig: 34 / 0x22" 220 "orig: 35 / 0x23" 219 "orig: 36 / 0x24" 218 "orig: 37 / 0x25" 217 "orig: 38 / 0x26" 216 "orig: 39 / 0x27" 215 "orig: 40 / 0x28" 214 "orig: 41 / 0x29" 213 "orig: 42 / 0x2A" 212 "orig: 43 / 0x2B" 211 "orig: 44 / 0x2C" 210 "orig: 45 / 0x2D" 209 "orig: 46 / 0x2E" 208 "orig: 47 / 0x2F" 207 "orig: 48 / 0x30" 206 "orig: 49 / 0x31" 205 "orig: 50 / 0x32" 204 "orig: 51 / 0x33" 203 "orig: 52 / 0x34" 202 "orig: 53 / 0x35" 201 "orig: 54 / 0x36" 200 "orig: 55 / 0x37" 199 "orig: 56 / 0x38" 198 "orig: 57 / 0x39" 197 "orig: 58 / 0x3A" 196 "orig: 59 / 0x3B" 195 "orig: 60 / 0x3C" 194 "orig: 61 / 0x3D" 193 "orig: 62 / 0x3E" 192 "orig: 63 / 0x3F" 191 "orig: 64 / 0x40" 190 "orig: 65 / 0x41" 189 "orig: 66 / 0x42" 188 "orig: 67 / 0x43" 187 "orig: 68 / 0x44" 186 "orig: 69 / 0x45" 185 "orig: 70 / 0x46" 184 "orig: 71 / 0x47" 183 "orig: 72 / 0x48" 182 "orig: 73 / 0x49" 181 "orig: 74 / 0x4A" 180 "orig: 75 / 0x4B" 179 "orig: 76 / 0x4C" 178 "orig: 77 / 0x4D" 177 "orig: 78 / 0x4E" 176 "orig: 79 / 0x4F" 175 "orig: 80 / 0x50" 174 "orig: 81 / 0x51" 173 "orig: 82 / 0x52" 172 "orig: 83 / 0x53" 171 "orig: 84 / 0x54" 170 "orig: 85 / 0x55" 169 "orig: 86 / 0x56" 168 "orig: 87 / 0x57" 167 "orig: 88 / 0x58" 166 "orig: 89 / 0x59" 165 "orig: 90 / 0x5A" 164 "orig: 91 / 0x5B" 163 "orig: 92 / 0x5C" 162 "orig: 93 / 0x5D" 161 "orig: 94 / 0x5E" 160 "orig: 95 / 0x5F" 159 "orig: 96 / 0x60" 158 "orig: 97 / 0x61" 157 "orig: 98 / 0x62" 156 "orig: 99 / 0x63" 155 "orig: 100 / 0x64" 154 "orig: 101 / 0x65" 153 "orig: 102 / 0x66" 152 "orig: 103 / 0x67" 151 "orig: 104 / 0x68" 150 "orig: 105 / 0x69" 149 "orig: 106 / 0x6A" 148 "orig: 107 / 0x6B" 147 "orig: 108 / 0x6C" 146 "orig: 109 / 0x6D" 145 "orig: 110 / 0x6E" 144 "orig: 111 / 0x6F" 143 "orig: 112 / 0x70" 142 "orig: 113 / 0x71" 141 "orig: 114 / 0x72" 140 "orig: 115 / 0x73" 139 "orig: 116 / 0x74" 138 "orig: 117 / 0x75" 137 "orig: 118 / 0x76" 136 "orig: 119 / 0x77" 135 "orig: 120 / 0x78" 134 "orig: 121 / 0x79" 133 "orig: 122 / 0x7A" 132 "orig: 123 / 0x7B" 131 "orig: 124 / 0x7C" 130 "orig: 125 / 0x7D" 128 "orig: 127 / 0x7F" 127 "orig: 128 / 0x80" 126 "orig: 129 / 0x81" 125 "orig: 130 / 0x82" 124 "orig: 131 / 0x83" 123 "orig: 132 / 0x84" 122 "orig: 133 / 0x85" 121 "orig: 134 / 0x86" 120 "orig: 135 / 0x87" 119 "orig: 136 / 0x88" 118 "orig: 137 / 0x89" 117 "orig: 138 / 0x8A" 116 "orig: 139 / 0x8B" 115 "orig: 140 / 0x8C" 114 "orig: 141 / 0x8D" 113 "orig: 142 / 0x8E" 112 "orig: 143 / 0x8F" 111 "orig: 144 / 0x90" 110 "orig: 145 / 0x91" 109 "orig: 146 / 0x92" 108 "orig: 147 / 0x93" 107 "orig: 148 / 0x94" 106 "orig: 149 / 0x95" 105 "orig: 150 / 0x96" 104 "orig: 151 / 0x97" 103 "orig: 152 / 0x98" 102 "orig: 153 / 0x99" 101 "orig: 154 / 0x9A" 100 "orig: 155 / 0x9B" 99 "orig: 156 / 0x9C" 98 "orig: 157 / 0x9D" 97 "orig: 158 / 0x9E" 96 "orig: 159 / 0x9F" 95 "orig: 160 / 0xA0" 94 "orig: 161 / 0xA1" 93 "orig: 162 / 0xA2" 92 "orig: 163 / 0xA3" 91 "orig: 164 / 0xA4" 90 "orig: 165 / 0xA5" 89 "orig: 166 / 0xA6" 88 "orig: 167 / 0xA7" 87 "orig: 168 / 0xA8" 86 "orig: 169 / 0xA9" 85 "orig: 170 / 0xAA" 84 "orig: 171 / 0xAB" 83 "orig: 172 / 0xAC" 82 "orig: 173 / 0xAD" 81 "orig: 174 / 0xAE" 80 "orig: 175 / 0xAF" 79 "orig: 176 / 0xB0" 78 "orig: 177 / 0xB1" 77 "orig: 178 / 0xB2" 76 "orig: 179 / 0xB3" 75 "orig: 180 / 0xB4" 74 "orig: 181 / 0xB5" 73 "orig: 182 / 0xB6" 72 "orig: 183 / 0xB7" 71 "orig: 184 / 0xB8" 70 "orig: 185 / 0xB9" 69 "orig: 186 / 0xBA" 68 "orig: 187 / 0xBB" 67 "orig: 188 / 0xBC" 66 "orig: 189 / 0xBD" 65 "orig: 190 / 0xBE" 64 "orig: 191 / 0xBF" 63 "orig: 192 / 0xC0" 62 "orig: 193 / 0xC1" 61 "orig: 194 / 0xC2" 60 "orig: 195 / 0xC3" 59 "orig: 196 / 0xC4" 58 "orig: 197 / 0xC5" 57 "orig: 198 / 0xC6" 56 "orig: 199 / 0xC7" 55 "orig: 200 / 0xC8" 54 "orig: 201 / 0xC9" 53 "orig: 202 / 0xCA" 52 "orig: 203 / 0xCB" 51 "orig: 204 / 0xCC" 50 "orig: 205 / 0xCD" 49 "orig: 206 / 0xCE" 48 "orig: 207 / 0xCF" 47 "orig: 208 / 0xD0" 46 "orig: 209 / 0xD1" 45 "orig: 210 / 0xD2" 44 "orig: 211 / 0xD3" 43 "orig: 212 / 0xD4" 42 "orig: 213 / 0xD5" 41 "orig: 214 / 0xD6" 40 "orig: 215 / 0xD7" 39 "orig: 216 / 0xD8" 38 "orig: 217 / 0xD9" 37 "orig: 218 / 0xDA" 36 "orig: 219 / 0xDB" 35 "orig: 220 / 0xDC" 34 "orig: 221 / 0xDD" 33 "orig: 222 / 0xDE" 32 "orig: 223 / 0xDF" 31 "orig: 224 / 0xE0" 30 "orig: 225 / 0xE1" 29 "orig: 226 / 0xE2" 28 "orig: 227 / 0xE3" 27 "orig: 228 / 0xE4" 26 "orig: 229 / 0xE5" 25 "orig: 230 / 0xE6" 24 "orig: 231 / 0xE7" 23 "orig: 232 / 0xE8" 22 "orig: 233 / 0xE9" 21 "orig: 234 / 0xEA" 20 "orig: 235 / 0xEB" 19 "orig: 236 / 0xEC" 18 "orig: 237 / 0xED" 17 "orig: 238 / 0xEE" 16 "orig: 239 / 0xEF" 15 "orig: 240 / 0xF0" 14 "orig: 241 / 0xF1" 13 "orig: 242 / 0xF2" 12 "orig: 243 / 0xF3" 11 "orig: 244 / 0xF4" 10 "orig: 245 / 0xF5" 9 "orig: 246 / 0xF6" 8 "orig: 247 / 0xF7" 7 "orig: 248 / 0xF8" 6 "orig: 249 / 0xF9" 5 "orig: 250 / 0xFA" 4 "orig: 251 / 0xFB" 3 "orig: 252 / 0xFC" 2 "orig: 253 / 0xFD" 1 "orig: 254 / 0xFE" 0 "orig: 255 / 0xFF" ;
VAL_ 2148466430 InvertedSA 129 "orig: 126 / 0x7E" 255 "orig: 0 / 0x0" 254 "orig: 1 / 0x1" 253 "orig: 2 / 0x2" 252 "orig: 3 / 0x3" 251 "orig: 4 / 0x4" 250 "orig: 5 / 0x5" 249 "orig: 6 / 0x6" 248 "orig: 7 / 0x7" 247 "orig: 8 / 0x8" 246 "orig: 9 / 0x9" 245 "orig: 10 / 0xA" 244 "orig: 11 / 0xB" 243 "orig: 12 / 0xC" 242 "orig: 13 / 0xD" 241 "orig: 14 / 0xE" 240 "orig: 15 / 0xF" 239 "orig: 16 / 0x10" 238 "orig: 17 / 0x11" 237 "orig: 17 / 0x12" 236 "orig: 19 / 0x13" 235 "orig: 20 / 0x14" 234 "orig: 21 / 0x15" 233 "orig: 22 / 0x16" 232 "orig: 23 / 0x17" 231 "orig: 24 / 0x18" 230 "orig: 25 / 0x19" 229 "orig: 26 / 0x1A" 228 "orig: 27 / 0x1B" 227 "orig: 28 / 0x1C" 226 "orig: 29 / 0x1D" 225 "orig: 30 / 0x1E" 224 "orig: 31 / 0x1F" 223 "orig: 32 / 0x20" 222 "orig: 33 / 0x21" 221 "orig: 34 / 0x22" 220 "orig: 35 / 0x23" 219 "orig: 36 / 0x24" 218 "orig: 37 / 0x25" 217 "orig: 38 / 0x26" 216 "orig: 39 / 0x27" 215 "orig: 40 / 0x28" 214 "orig: 41 / 0x29" 213 "orig: 42 / 0x2A" 212 "orig: 43 / 0x2B" 211 "orig: 44 / 0x2C" 210 "orig: 45 / 0x2D" 209 "orig: 46 / 0x2E" 208 "orig: 47 / 0x2F" 207 "orig: 48 / 0x30" 206 "orig: 49 / 0x31" 205 "orig: 50 / 0x32" 204 "orig: 51 / 0x33" 203 "orig: 52 / 0x34" 202 "orig: 53 / 0x35" 201 "orig: 54 / 0x36" 200 "orig: 55 / 0x37" 199 "orig: 56 / 0x38" 198 "orig: 57 / 0x39" 197 "orig: 58 / 0x3A" 196 "orig: 59 / 0x3B" 195 "orig: 60 / 0x3C" 194 "orig: 61 / 0x3D" 193 "orig: 62 / 0x3E" 192 "orig: 63 / 0x3F" 191 "orig: 64 / 0x40" 190 "orig: 65 / 0x41" 189 "orig: 66 / 0x42" 188 "orig: 67 / 0x43" 187 "orig: 68 / 0x44" 186 "orig: 69 / 0x45" 185 "orig: 70 / 0x46" 184 "orig: 71 / 0x47" 183 "orig: 72 / 0x48" 182 "orig: 73 / 0x49" 181 "orig: 74 / 0x4A" 180 "orig: 75 / 0x4B" 179 "orig: 76 / 0x4C" 178 "orig: 77 / 0x4D" 177 "orig: 78 / 0x4E" 176 "orig: 79 / 0x4F" 175 "orig: 80 / 0x50" 174 "orig: 81 / 0x51" 173 "orig: 82 / 0x52" 172 "orig: 83 / 0x53" 171 "orig: 84 / 0x54" 170 "orig: 85 / 0x55" 169 "orig: 86 / 0x56" 168 "orig: 87 / 0x57" 167 "orig: 88 / 0x58" 166 "orig: 89 / 0x59" 165 "orig: 90 / 0x5A" 164 "orig: 91 / 0x5B" 163 "orig: 92 / 0x5C" 162 "orig: 93 / 0x5D" 161 "orig: 94 / 0x5E" 160 "orig: 95 / 0x5F" 159 "orig: 96 / 0x60" 158 "orig: 97 / 0x61" 157 "orig: 98 / 0x62" 156 "orig: 99 / 0x63" 155 "orig: 100 / 0x64" 154 "orig: 101 / 0x65" 153 "orig: 102 / 0x66" 152 "orig: 103 / 0x67" 151 "orig: 104 / 0x68" 150 "orig: 105 / 0x69" 149 "orig: 106 / 0x6A" 148 "orig: 107 / 0x6B" 147 "orig: 108 / 0x6C" 146 "orig: 109 / 0x6D" 145 "orig: 110 / 0x6E" 144 "orig: 111 / 0x6F" 143 "orig: 112 / 0x70" 142 "orig: 113 / 0x71" 141 "orig: 114 / 0x72" 140 "orig: 115 / 0x73" 139 "orig: 116 / 0x74" 138 "orig: 117 / 0x75" 137 "orig: 118 / 0x76" 136 "orig: 119 / 0x77" 135 "orig: 120 / 0x78" 134 "orig: 121 / 0x79" 133 "orig: 122 / 0x7A" 132 "orig: 123 / 0x7B" 131 "orig: 124 / 0x7C" 130 "orig: 125 / 0x7D" 128 "orig: 127 / 0x7F" 127 "orig: 128 / 0x80" 126 "orig: 129 / 0x81" 125 "orig: 130 / 0x82" 124 "orig: 131 / 0x83" 123 "orig: 132 / 0x84" 122 "orig: 133 / 0x85" 121 "orig: 134 / 0x86" 120 "orig: 135 / 0x87" 119 "orig: 136 / 0x88" 118 "orig: 137 / 0x89" 117 "orig: 138 / 0x8A" 116 "orig: 139 / 0x8B" 115 "orig: 140 / 0x8C" 114 "orig: 141 / 0x8D" 113 "orig: 142 / 0x8E" 112 "orig: 143 / 0x8F" 111 "orig: 144 / 0x90" 110 "orig: 145 / 0x91" 109 "orig: 146 / 0x92" 108 "orig: 147 / 0x93" 107 "orig: 148 / 0x94" 106 "orig: 149 / 0x95" 105 "orig: 150 / 0x96" 104 "orig: 151 / 0x97" 103 "orig: 152 / 0x98" 102 "orig: 153 / 0x99" 101 "orig: 154 / 0x9A" 100 "orig: 155 / 0x9B" 99 "orig: 156 / 0x9C" 98 "orig: 157 / 0x9D" 97 "orig: 158 / 0x9E" 96 "orig: 159 / 0x9F" 95 "orig: 160 / 0xA0" 94 "orig: 161 / 0xA1" 93 "orig: 162 / 0xA2" 92 "orig: 163 / 0xA3" 91 "orig: 164 / 0xA4" 90 "orig: 165 / 0xA5" 89 "orig: 166 / 0xA6" 88 "orig: 167 / 0xA7" 87 "orig: 168 / 0xA8" 86 "orig: 169 / 0xA9" 85 "orig: 170 / 0xAA" 84 "orig: 171 / 0xAB" 83 "orig: 172 / 0xAC" 82 "orig: 173 / 0xAD" 81 "orig: 174 / 0xAE" 80 "orig: 175 / 0xAF" 79 "orig: 176 / 0xB0" 78 "orig: 177 / 0xB1" 77 "orig: 178 / 0xB2" 76 "orig: 179 / 0xB3" 75 "orig: 180 / 0xB4" 74 "orig: 181 / 0xB5" 73 "orig: 182 / 0xB6" 72 "orig: 183 / 0xB7" 71 "orig: 184 / 0xB8" 70 "orig: 185 / 0xB9" 69 "orig: 186 / 0xBA" 68 "orig: 187 / 0xBB" 67 "orig: 188 / 0xBC" 66 "orig: 189 / 0xBD" 65 "orig: 190 / 0xBE" 64 "orig: 191 / 0xBF" 63 "orig: 192 / 0xC0" 62 "orig: 193 / 0xC1" 61 "orig: 194 / 0xC2" 60 "orig: 195 / 0xC3" 59 "orig: 196 / 0xC4" 58 "orig: 197 / 0xC5" 57 "orig: 198 / 0xC6" 56 "orig: 199 / 0xC7" 55 "orig: 200 / 0xC8" 54 "orig: 201 / 0xC9" 53 "orig: 202 / 0xCA" 52 "orig: 203 / 0xCB" 51 "orig: 204 / 0xCC" 50 "orig: 205 / 0xCD" 49 "orig: 206 / 0xCE" 48 "orig: 207 / 0xCF" 47 "orig: 208 / 0xD0" 46 "orig: 209 / 0xD1" 45 "orig: 210 / 0xD2" 44 "orig: 211 / 0xD3" 43 "orig: 212 / 0xD4" 42 "orig: 213 / 0xD5" 41 "orig: 214 / 0xD6" 40 "orig: 215 / 0xD7" 39 "orig: 216 / 0xD8" 38 "orig: 217 / 0xD9" 37 "orig: 218 / 0xDA" 36 "orig: 219 / 0xDB" 35 "orig: 220 / 0xDC" 34 "orig: 221 / 0xDD" 33 "orig: 222 / 0xDE" 32 "orig: 223 / 0xDF" 31 "orig: 224 / 0xE0" 30 "orig: 225 / 0xE1" 29 "orig: 226 / 0xE2" 28 "orig: 227 / 0xE3" 27 "orig: 228 / 0xE4" 26 "orig: 229 / 0xE5" 25 "orig: 230 / 0xE6" 24 "orig: 231 / 0xE7" 23 "orig: 232 / 0xE8" 22 "orig: 233 / 0xE9" 21 "orig: 234 / 0xEA" 20 "orig: 235 / 0xEB" 19 "orig: 236 / 0xEC" 18 "orig: 237 / 0xED" 17 "orig: 238 / 0xEE" 16 "orig: 239 / 0xEF" 15 "orig: 240 / 0xF0" 14 "orig: 241 / 0xF1" 13 "orig: 242 / 0xF2" 12 "orig: 243 / 0xF3" 11 "orig: 244 / 0xF4" 10 "orig: 245 / 0xF5" 9 "orig: 246 / 0xF6" 8 "orig: 247 / 0xF7" 7 "orig: 248 / 0xF8" 6 "orig: 249 / 0xF9" 5 "orig: 250 / 0xFA" 4 "orig: 251 / 0xFB" 3 "orig: 252 / 0xFC" 2 "orig: 253 / 0xFD" 1 "orig: 254 / 0xFE" 0 "orig: 255 / 0xFF" ;
VAL_ 2148466430 InvertedEDP 1 "orig: 0x0" 0 "orig: 0x1" ;
VAL_ 2148466430 InvertedDP 1 "orig: 0x0" 0 "orig: 0x1" ;
VAL_ 2365254910 StdDeviationOfLaneInfoError 15 "SignalNotAvailable" 14 "Error" 11 "SmallerOrEqual5cm" 10 "SmallerOrEqual7.5cm" 9 "SmallerOrEqual10cm" 8 "SmallerOrEqual25cm" 7 "SmallerOrEqual50cm" 6 "SmallerOrEqual75cm" 5 "SmallerOrEqual1m" 4 "SmallerOrEqual2.5m" 3 "SmallerOrEqual5m" 2 "SmallerOrEqual7.5m" 1 "SmallerOrEqual10m" 0 "UnspecificOrSmallerThan10m" ;
VAL_ 2365254910 ODStatusIndicator 15 "ODStatusNotAvailable" 14 "Error" 4 "MultipleTrailers" 3 "ODReady" 2 "ODDegraded" 1 "ODTemporarilyNotAvailable" 0 "ODPermanentlyNotAvailable" ;
VAL_ 2365254654 ODStatusIndicator 15 "ODStatusNotAvailable" 14 "Error" 4 "MultipleTrailers" 3 "ODReady" 2 "ODDegraded" 1 "ODTemporarilyNotAvailable" 0 "ODPermanentlyNotAvailable" ;
VAL_ 2365254398 StdDeviationOfLaneInfoError 15 "SignalNotAvailable" 14 "Error" 11 "SmallerOrEqual5cm" 10 "SmallerOrEqual7.5cm" 9 "SmallerOrEqual10cm" 8 "SmallerOrEqual25cm" 7 "SmallerOrEqual50cm" 6 "SmallerOrEqual75cm" 5 "SmallerOrEqual1m" 4 "SmallerOrEqual2.5m" 3 "SmallerOrEqual5m" 2 "SmallerOrEqual7.5m" 1 "SmallerOrEqual10m" 0 "UnspecificOrSmallerThan10m" ;
VAL_ 2365254398 ODStatusIndicator 15 "ODStatusNotAvailable" 14 "Error" 4 "MultipleTrailers" 3 "ODReady" 2 "ODDegraded" 1 "ODTemporarilyNotAvailable" 0 "ODPermanentlyNotAvailable" ;
VAL_ 2365254142 ODStatusIndicator 15 "ODStatusNotAvailable" 14 "Error" 4 "MultipleTrailers" 3 "ODReady" 2 "ODDegraded" 1 "ODTemporarilyNotAvailable" 0 "ODPermanentlyNotAvailable" ;
VAL_ 2365253886 ODStatusIndicator 15 "ODStatusNotAvailable" 14 "Error" 4 "MultipleTrailers" 3 "ODReady" 2 "ODDegraded" 1 "ODTemporarilyNotAvailable" 0 "ODPermanentlyNotAvailable" ;
VAL_ 2231035902 ObjectClassification 15 "SignalNotAvailable" 11 "Nature" 10 "Pole" 9 "Construction" 8 "UnknownStationary" 4 "Human" 3 "Cyclist" 2 "CommercialVehicle" 1 "Vehicle" 0 "UnknownMoving" ;
VAL_ 2231035902 ObjectLength 3 "UnknownLength" 2 "BiggerThan7m" 1 "BiggerThan3mSmallerOrEqual7m" 0 "SmallerOrEqual3m" ;
VAL_ 2231035902 ObjectWidth 3 "UnknownWidth" 2 "BiggerThan3m" 1 "BiggerThan1mSmallerOrEqual3m" 0 "SmallerOrEqual1m" ;
VAL_ 2231035902 ODStdDeviationOfLonAndLatDist 15 "SignalNotAvailable" 14 "Error" 11 "SmallerOrEqual5cm" 10 "SmallerOrEqual7.5cm" 9 "SmallerOrEqual10cm" 8 "SmallerOrEqual25cm" 7 "SmallerOrEqual50cm" 6 "SmallerOrEqual75cm" 5 "SmallerOrEqual1m" 4 "SmallerOrEqual2.5m" 3 "SmallerOrEqual5m" 2 "SmallerOrEqual7.5m" 1 "SmallerOrEqual10m" 0 "UnspecificOrSmallerThan10m" ;
VAL_ 2231035902 ODStatusIndicator 15 "ODStatusNotAvailable" 14 "Error" 4 "MultipleTrailers" 3 "ODReady" 2 "ODDegraded" 1 "ODTemporarilyNotAvailable" 0 "ODPermanentlyNotAvailable" ;
VAL_ 2231035646 ODStdDeviationOfLonAndLatDist 15 "SignalNotAvailable" 14 "Error" 11 "SmallerOrEqual5cm" 10 "SmallerOrEqual7.5cm" 9 "SmallerOrEqual10cm" 8 "SmallerOrEqual25cm" 7 "SmallerOrEqual50cm" 6 "SmallerOrEqual75cm" 5 "SmallerOrEqual1m" 4 "SmallerOrEqual2.5m" 3 "SmallerOrEqual5m" 2 "SmallerOrEqual7.5m" 1 "SmallerOrEqual10m" 0 "UnspecificOrSmallerThan10m" ;
VAL_ 2231035646 ODStatusIndicator 15 "ODStatusNotAvailable" 14 "Error" 4 "MultipleTrailers" 3 "ODReady" 2 "ODDegraded" 1 "ODTemporarilyNotAvailable" 0 "ODPermanentlyNotAvailable" ;
VAL_ 2231035390 ObjectClassification 15 "SignalNotAvailable" 11 "Nature" 10 "Pole" 9 "Construction" 8 "UnknownStationary" 4 "Human" 3 "Cyclist" 2 "CommercialVehicle" 1 "Vehicle" 0 "UnknownMoving" ;
VAL_ 2231035390 ObjectLength 3 "UnknownLength" 2 "BiggerThan7m" 1 "BiggerThan3mSmallerOrEqual7m" 0 "SmallerOrEqual3m" ;
VAL_ 2231035390 ObjectWidth 3 "UnknownWidth" 2 "BiggerThan3m" 1 "BiggerThan1mSmallerOrEqual3m" 0 "SmallerOrEqual1m" ;
VAL_ 2231035390 ODStdDeviationOfLonAndLatDist 15 "SignalNotAvailable" 14 "Error" 11 "SmallerOrEqual5cm" 10 "SmallerOrEqual7.5cm" 9 "SmallerOrEqual10cm" 8 "SmallerOrEqual25cm" 7 "SmallerOrEqual50cm" 6 "SmallerOrEqual75cm" 5 "SmallerOrEqual1m" 4 "SmallerOrEqual2.5m" 3 "SmallerOrEqual5m" 2 "SmallerOrEqual7.5m" 1 "SmallerOrEqual10m" 0 "UnspecificOrSmallerThan10m" ;
VAL_ 2231035390 ODStatusIndicator 15 "ODStatusNotAvailable" 14 "Error" 4 "MultipleTrailers" 3 "ODReady" 2 "ODDegraded" 1 "ODTemporarilyNotAvailable" 0 "ODPermanentlyNotAvailable" ;
VAL_ 2231034878 ObjectClassification 15 "SignalNotAvailable" 11 "Nature" 10 "Pole" 9 "Construction" 8 "UnknownStationary" 4 "Human" 3 "Cyclist" 2 "CommercialVehicle" 1 "Vehicle" 0 "UnknownMoving" ;
VAL_ 2231034878 ObjectLength 3 "UnknownLength" 2 "BiggerThan7m" 1 "BiggerThan3mSmallerOrEqual7m" 0 "SmallerOrEqual3m" ;
VAL_ 2231034878 ObjectWidth 3 "UnknownWidth" 2 "BiggerThan3m" 1 "BiggerThan1mSmallerOrEqual3m" 0 "SmallerOrEqual1m" ;
VAL_ 2231034878 ODStdDeviationOfLonAndLatDist 15 "SignalNotAvailable" 14 "Error" 11 "SmallerOrEqual5cm" 10 "SmallerOrEqual7.5cm" 9 "SmallerOrEqual10cm" 8 "SmallerOrEqual25cm" 7 "SmallerOrEqual50cm" 6 "SmallerOrEqual75cm" 5 "SmallerOrEqual1m" 4 "SmallerOrEqual2.5m" 3 "SmallerOrEqual5m" 2 "SmallerOrEqual7.5m" 1 "SmallerOrEqual10m" 0 "UnspecificOrSmallerThan10m" ;
VAL_ 2231034878 ODStatusIndicator 15 "ODStatusNotAvailable" 14 "Error" 4 "MultipleTrailers" 3 "ODReady" 2 "ODDegraded" 1 "ODTemporarilyNotAvailable" 0 "ODPermanentlyNotAvailable" ;
VAL_ 2231035134 ODStdDeviationOfLonAndLatDist 15 "SignalNotAvailable" 14 "Error" 11 "SmallerOrEqual5cm" 10 "SmallerOrEqual7.5cm" 9 "SmallerOrEqual10cm" 8 "SmallerOrEqual25cm" 7 "SmallerOrEqual50cm" 6 "SmallerOrEqual75cm" 5 "SmallerOrEqual1m" 4 "SmallerOrEqual2.5m" 3 "SmallerOrEqual5m" 2 "SmallerOrEqual7.5m" 1 "SmallerOrEqual10m" 0 "UnspecificOrSmallerThan10m" ;
VAL_ 2231035134 ODStatusIndicator 15 "ODStatusNotAvailable" 14 "Error" 4 "MultipleTrailers" 3 "ODReady" 2 "ODDegraded" 1 "ODTemporarilyNotAvailable" 0 "ODPermanentlyNotAvailable" ;
VAL_ 2231034622 ODStdDeviationOfLonAndLatDist 15 "SignalNotAvailable" 14 "Error" 11 "SmallerOrEqual5cm" 10 "SmallerOrEqual7.5cm" 9 "SmallerOrEqual10cm" 8 "SmallerOrEqual25cm" 7 "SmallerOrEqual50cm" 6 "SmallerOrEqual75cm" 5 "SmallerOrEqual1m" 4 "SmallerOrEqual2.5m" 3 "SmallerOrEqual5m" 2 "SmallerOrEqual7.5m" 1 "SmallerOrEqual10m" 0 "UnspecificOrSmallerThan10m" ;
VAL_ 2231034622 ODStatusIndicator 15 "ODStatusNotAvailable" 14 "Error" 4 "MultipleTrailers" 3 "ODReady" 2 "ODDegraded" 1 "ODTemporarilyNotAvailable" 0 "ODPermanentlyNotAvailable" ;
VAL_ 2231034366 ObjectClassification 15 "SignalNotAvailable" 11 "Nature" 10 "Pole" 9 "Construction" 8 "UnknownStationary" 4 "Human" 3 "Cyclist" 2 "CommercialVehicle" 1 "Vehicle" 0 "UnknownMoving" ;
VAL_ 2231034366 ObjectLength 3 "UnknownLength" 2 "BiggerThan7m" 1 "BiggerThan3mSmallerOrEqual7m" 0 "SmallerOrEqual3m" ;
VAL_ 2231034366 ObjectWidth 3 "UnknownWidth" 2 "BiggerThan3m" 1 "BiggerThan1mSmallerOrEqual3m" 0 "SmallerOrEqual1m" ;
VAL_ 2231034366 ODStdDeviationOfLonAndLatDist 15 "SignalNotAvailable" 14 "Error" 11 "SmallerOrEqual5cm" 10 "SmallerOrEqual7.5cm" 9 "SmallerOrEqual10cm" 8 "SmallerOrEqual25cm" 7 "SmallerOrEqual50cm" 6 "SmallerOrEqual75cm" 5 "SmallerOrEqual1m" 4 "SmallerOrEqual2.5m" 3 "SmallerOrEqual5m" 2 "SmallerOrEqual7.5m" 1 "SmallerOrEqual10m" 0 "UnspecificOrSmallerThan10m" ;
VAL_ 2231034366 ODStatusIndicator 15 "ODStatusNotAvailable" 14 "Error" 4 "MultipleTrailers" 3 "ODReady" 2 "ODDegraded" 1 "ODTemporarilyNotAvailable" 0 "ODPermanentlyNotAvailable" ;
VAL_ 2231034110 ODStdDeviationOfLonAndLatDist 15 "SignalNotAvailable" 14 "Error" 11 "SmallerOrEqual5cm" 10 "SmallerOrEqual7.5cm" 9 "SmallerOrEqual10cm" 8 "SmallerOrEqual25cm" 7 "SmallerOrEqual50cm" 6 "SmallerOrEqual75cm" 5 "SmallerOrEqual1m" 4 "SmallerOrEqual2.5m" 3 "SmallerOrEqual5m" 2 "SmallerOrEqual7.5m" 1 "SmallerOrEqual10m" 0 "UnspecificOrSmallerThan10m" ;
VAL_ 2231034110 ODStatusIndicator 15 "ODStatusNotAvailable" 14 "Error" 4 "MultipleTrailers" 3 "ODReady" 2 "ODDegraded" 1 "ODTemporarilyNotAvailable" 0 "ODPermanentlyNotAvailable" ;
VAL_ 2231033854 ObjectClassification 15 "SignalNotAvailable" 11 "Nature" 10 "Pole" 9 "Construction" 8 "UnknownStationary" 4 "Human" 3 "Cyclist" 2 "CommercialVehicle" 1 "Vehicle" 0 "UnknownMoving" ;
VAL_ 2231033854 ObjectLength 3 "UnknownLength" 2 "BiggerThan7m" 1 "BiggerThan3mSmallerOrEqual7m" 0 "SmallerOrEqual3m" ;
VAL_ 2231033854 ObjectWidth 3 "UnknownWidth" 2 "BiggerThan3m" 1 "BiggerThan1mSmallerOrEqual3m" 0 "SmallerOrEqual1m" ;
VAL_ 2231033854 ODStdDeviationOfLonAndLatDist 15 "SignalNotAvailable" 14 "Error" 11 "SmallerOrEqual5cm" 10 "SmallerOrEqual7.5cm" 9 "SmallerOrEqual10cm" 8 "SmallerOrEqual25cm" 7 "SmallerOrEqual50cm" 6 "SmallerOrEqual75cm" 5 "SmallerOrEqual1m" 4 "SmallerOrEqual2.5m" 3 "SmallerOrEqual5m" 2 "SmallerOrEqual7.5m" 1 "SmallerOrEqual10m" 0 "UnspecificOrSmallerThan10m" ;
VAL_ 2231033854 ODStatusIndicator 15 "ODStatusNotAvailable" 14 "Error" 4 "MultipleTrailers" 3 "ODReady" 2 "ODDegraded" 1 "ODTemporarilyNotAvailable" 0 "ODPermanentlyNotAvailable" ;
VAL_ 2231033598 ODStdDeviationOfLonAndLatDist 15 "SignalNotAvailable" 14 "Error" 11 "SmallerOrEqual5cm" 10 "SmallerOrEqual7.5cm" 9 "SmallerOrEqual10cm" 8 "SmallerOrEqual25cm" 7 "SmallerOrEqual50cm" 6 "SmallerOrEqual75cm" 5 "SmallerOrEqual1m" 4 "SmallerOrEqual2.5m" 3 "SmallerOrEqual5m" 2 "SmallerOrEqual7.5m" 1 "SmallerOrEqual10m" 0 "UnspecificOrSmallerThan10m" ;
VAL_ 2231033598 ODStatusIndicator 15 "ODStatusNotAvailable" 14 "Error" 4 "MultipleTrailers" 3 "ODReady" 2 "ODDegraded" 1 "ODTemporarilyNotAvailable" 0 "ODPermanentlyNotAvailable" ;
VAL_ 2231033342 ObjectClassification 15 "SignalNotAvailable" 11 "Nature" 10 "Pole" 9 "Construction" 8 "UnknownStationary" 4 "Human" 3 "Cyclist" 2 "CommercialVehicle" 1 "Vehicle" 0 "UnknownMoving" ;
VAL_ 2231033342 ObjectLength 3 "UnknownLength" 2 "BiggerThan7m" 1 "BiggerThan3mSmallerOrEqual7m" 0 "SmallerOrEqual3m" ;
VAL_ 2231033342 ObjectWidth 3 "UnknownWidth" 2 "BiggerThan3m" 1 "BiggerThan1mSmallerOrEqual3m" 0 "SmallerOrEqual1m" ;
VAL_ 2231033342 ODStdDeviationOfLonAndLatDist 15 "SignalNotAvailable" 14 "Error" 11 "SmallerOrEqual5cm" 10 "SmallerOrEqual7.5cm" 9 "SmallerOrEqual10cm" 8 "SmallerOrEqual25cm" 7 "SmallerOrEqual50cm" 6 "SmallerOrEqual75cm" 5 "SmallerOrEqual1m" 4 "SmallerOrEqual2.5m" 3 "SmallerOrEqual5m" 2 "SmallerOrEqual7.5m" 1 "SmallerOrEqual10m" 0 "UnspecificOrSmallerThan10m" ;
VAL_ 2231033342 ODStatusIndicator 15 "ODStatusNotAvailable" 14 "Error" 4 "MultipleTrailers" 3 "ODReady" 2 "ODDegraded" 1 "ODTemporarilyNotAvailable" 0 "ODPermanentlyNotAvailable" ;
VAL_ 2231033086 ODStdDeviationOfLonAndLatDist 15 "SignalNotAvailable" 14 "Error" 11 "SmallerOrEqual5cm" 10 "SmallerOrEqual7.5cm" 9 "SmallerOrEqual10cm" 8 "SmallerOrEqual25cm" 7 "SmallerOrEqual50cm" 6 "SmallerOrEqual75cm" 5 "SmallerOrEqual1m" 4 "SmallerOrEqual2.5m" 3 "SmallerOrEqual5m" 2 "SmallerOrEqual7.5m" 1 "SmallerOrEqual10m" 0 "UnspecificOrSmallerThan10m" ;
VAL_ 2231033086 ODStatusIndicator 15 "ODStatusNotAvailable" 14 "Error" 4 "MultipleTrailers" 3 "ODReady" 2 "ODDegraded" 1 "ODTemporarilyNotAvailable" 0 "ODPermanentlyNotAvailable" ;
VAL_ 2231032830 ObjectClassification 15 "SignalNotAvailable" 11 "Nature" 10 "Pole" 9 "Construction" 8 "UnknownStationary" 4 "Human" 3 "Cyclist" 2 "CommercialVehicle" 1 "Vehicle" 0 "UnknownMoving" ;
VAL_ 2231032830 ObjectLength 3 "UnknownLength" 2 "BiggerThan7m" 1 "BiggerThan3mSmallerOrEqual7m" 0 "SmallerOrEqual3m" ;
VAL_ 2231032830 ObjectWidth 3 "UnknownWidth" 2 "BiggerThan3m" 1 "BiggerThan1mSmallerOrEqual3m" 0 "SmallerOrEqual1m" ;
VAL_ 2231032830 ODStdDeviationOfLonAndLatDist 15 "SignalNotAvailable" 14 "Error" 11 "SmallerOrEqual5cm" 10 "SmallerOrEqual7.5cm" 9 "SmallerOrEqual10cm" 8 "SmallerOrEqual25cm" 7 "SmallerOrEqual50cm" 6 "SmallerOrEqual75cm" 5 "SmallerOrEqual1m" 4 "SmallerOrEqual2.5m" 3 "SmallerOrEqual5m" 2 "SmallerOrEqual7.5m" 1 "SmallerOrEqual10m" 0 "UnspecificOrSmallerThan10m" ;
VAL_ 2231032830 ODStatusIndicator 15 "ODStatusNotAvailable" 14 "Error" 4 "MultipleTrailers" 3 "ODReady" 2 "ODDegraded" 1 "ODTemporarilyNotAvailable" 0 "ODPermanentlyNotAvailable" ;
VAL_ 2231032574 ODStdDeviationOfLonAndLatDist 15 "SignalNotAvailable" 14 "Error" 11 "SmallerOrEqual5cm" 10 "SmallerOrEqual7.5cm" 9 "SmallerOrEqual10cm" 8 "SmallerOrEqual25cm" 7 "SmallerOrEqual50cm" 6 "SmallerOrEqual75cm" 5 "SmallerOrEqual1m" 4 "SmallerOrEqual2.5m" 3 "SmallerOrEqual5m" 2 "SmallerOrEqual7.5m" 1 "SmallerOrEqual10m" 0 "UnspecificOrSmallerThan10m" ;
VAL_ 2231032574 ODStatusIndicator 15 "ODStatusNotAvailable" 14 "Error" 4 "MultipleTrailers" 3 "ODReady" 2 "ODDegraded" 1 "ODTemporarilyNotAvailable" 0 "ODPermanentlyNotAvailable" ;
VAL_ 2231032318 ObjectClassification 15 "SignalNotAvailable" 11 "Nature" 10 "Pole" 9 "Construction" 8 "UnknownStationary" 4 "Human" 3 "Cyclist" 2 "CommercialVehicle" 1 "Vehicle" 0 "UnknownMoving" ;
VAL_ 2231032318 ObjectLength 3 "UnknownLength" 2 "BiggerThan7m" 1 "BiggerThan3mSmallerOrEqual7m" 0 "SmallerOrEqual3m" ;
VAL_ 2231032318 ObjectWidth 3 "UnknownWidth" 2 "BiggerThan3m" 1 "BiggerThan1mSmallerOrEqual3m" 0 "SmallerOrEqual1m" ;
VAL_ 2231032318 ODStdDeviationOfLonAndLatDist 15 "SignalNotAvailable" 14 "Error" 11 "SmallerOrEqual5cm" 10 "SmallerOrEqual7.5cm" 9 "SmallerOrEqual10cm" 8 "SmallerOrEqual25cm" 7 "SmallerOrEqual50cm" 6 "SmallerOrEqual75cm" 5 "SmallerOrEqual1m" 4 "SmallerOrEqual2.5m" 3 "SmallerOrEqual5m" 2 "SmallerOrEqual7.5m" 1 "SmallerOrEqual10m" 0 "UnspecificOrSmallerThan10m" ;
VAL_ 2231032318 ODStatusIndicator 15 "ODStatusNotAvailable" 14 "Error" 4 "MultipleTrailers" 3 "ODReady" 2 "ODDegraded" 1 "ODTemporarilyNotAvailable" 0 "ODPermanentlyNotAvailable" ;
VAL_ 2231032062 ODStdDeviationOfLonAndLatDist 15 "SignalNotAvailable" 14 "Error" 11 "SmallerOrEqual5cm" 10 "SmallerOrEqual7.5cm" 9 "SmallerOrEqual10cm" 8 "SmallerOrEqual25cm" 7 "SmallerOrEqual50cm" 6 "SmallerOrEqual75cm" 5 "SmallerOrEqual1m" 4 "SmallerOrEqual2.5m" 3 "SmallerOrEqual5m" 2 "SmallerOrEqual7.5m" 1 "SmallerOrEqual10m" 0 "UnspecificOrSmallerThan10m" ;
VAL_ 2231032062 ODStatusIndicator 15 "ODStatusNotAvailable" 14 "Error" 4 "MultipleTrailers" 3 "ODReady" 2 "ODDegraded" 1 "ODTemporarilyNotAvailable" 0 "ODPermanentlyNotAvailable" ;
VAL_ 2566575870 CommunicationsPhysicalLayer 15 "Not available" 14 "Error" 13 "Manufacturer specific comms type 2" 12 "Manufacturer specific comms type 1" 11 "reserved for future use" 10 "reserved for future use" 9 "reserved for future use" 8 "reserved for future use" 7 "reserved for future use" 6 "reserved for future use" 5 "Wireless" 4 "CAN" 3 "PLC comms" 2 "LIN Bus" 1 "Control Pilot PWM" 0 "Protocol yet to be determined" ;
VAL_ 2566575870 ConnType 15 "Not available" 14 "Error" 13 "Manufacturer specific type 2" 12 "Manufacturer specific type 1" 11 "reserved for future use" 10 "reserved for future use" 9 "reserved for future use" 8 "reserved for future use" 7 "reserved for future use" 6 "reserved for future use" 5 "Pantograph" 4 "Wireless charging" 3 "DC" 2 "Multi-Phase AC" 1 "Single Phase AC" 0 "EVSE not connected or EVSE type still to be determined" ;
VAL_ 2566575870 InletSt 15 "Not Available" 14 "Error" 13 "Disconnection Request" 12 "Validating" 11 "reserved" 10 "reserved" 9 "reserved" 8 "reserved" 7 "reserved" 6 "reserved" 5 "reserved" 4 "Connected as energy drain" 3 "Connected as energy source" 2 "Connected as energy drain or source" 1 "Perform Connection Verification" 0 "No Connection" ;
VAL_ 2566575870 InletContactorSt 3 "Not available" 2 "Error" 1 "Contactor Closed" 0 "Contactor Open" ;
VAL_ 2566575870 ConnectorLockPermission 3 "Not available" 2 "reserved" 1 "Lock control allowed" 0 "Lock control prohibited" ;
VAL_ 2566575870 ConnectorLockSt 7 "Not available" 6 "Error" 5 "No locking mechanism is available on this vehicle" 4 "Reserved" 3 "Reserved" 2 "In transition to/from Locked" 1 "Locked" 0 "Unlocked" ;
VAL_ 2566575870 ManualOvrd 3 "Not available" 2 "Error" 1 "Manual override active" 0 "Manual override not active" ;
VAL_ 2566575870 ConnectorReleaseLatch 3 "Not available" 2 "Unknown" 1 "Latch engaged" 0 "Latch released" ;
VAL_ 2566575102 EmbeddedIntegritySupport 3 "ADSC2 CRC and Counter are not supported by the sender" 2 "Reserved" 1 "ADSC1 protection is supported using J1939-76 SHM" 0 "ADSC1 embedded CRC and Counter are supported by the sender" ;
VAL_ 2566575102 VSCtrlConsent 3 "Not available" 2 "Error" 1 "Consent" 0 "No consent" ;
VAL_ 2566575102 TSC1CtrlPurpP7InhCmd 3 "Not available" 2 "Reserved" 1 "Sending TSC1 Control Purpose P7 is inhibited" 0 "Sending TSC1 Control Purpose P7 is allowed" ;
VAL_ 2499465470 MirrorPrimary_SecondarySelection 7 "Not available" 6 "Error" 5 "Reserved" 4 "Reserved" 3 "Reserved" 2 "Secondary Mirror Set Selected" 1 "Primary Mirror Set Selected" 0 "No Mirror Selected" ;
VAL_ 2499465470 Mirror2Left_RightSelection 7 "Not available" 6 "Error" 5 "Reserved" 4 "Reserved" 3 "Reserved" 2 "Mirror 2 Right Selected" 1 "Mirror 2 Left Selected" 0 "No Mirror Selected" ;
VAL_ 2499465470 Mirror1Left_RightSelection 7 "Not available" 6 "Error" 5 "Reserved" 4 "Reserved" 3 "Reserved" 2 "Mirror 1 Right Selected" 1 "Mirror 1 Left Selected" 0 "No Mirror Selected" ;
VAL_ 2566574078 CompatibilityCode 15 "Not available" 14 "No EVSE connected" 13 "Other" 12 "Reserved" 11 "Reserved" 10 "Reserved" 9 "Reserved" 8 "Reserved" 7 "Reserved" 6 "Reserved" 5 "Reserved" 4 "Reserved" 3 "Reserved" 2 "Ventilation" 1 "Digital Communications" 0 "EVSE is compatible" ;
VAL_ 2566574078 CtrlPilotSubSt 15 "Not available" 14 "Error" 13 "Pending" 12 "Reserved" 11 "Reserved" 10 "Reserved" 9 "Reserved" 8 "Reserved" 7 "Reserved" 6 "Reserved" 5 "Reserved" 4 "Reserved" 3 "Reserved" 2 "LIN communications detected on Control Pilot." 1 "Sub-state 2" 0 "Sub-state 1" ;
VAL_ 2566574078 CtrlPilotSt 15 "Not available" 14 "Error" 13 "Pending" 12 "Reserved" 11 "Reserved" 10 "Reserved" 9 "Reserved" 8 "Reserved" 7 "Reserved" 6 "Reserved" 5 "State F" 4 "State E" 3 "State D" 2 "State C" 1 "State B" 0 "State A" ;
VAL_ 2566573822 TransPTOGearboxStatus 15 "Not Available" 14 "Error" 13 "Shift in process" 12 "Reserved" 11 "Reserved" 10 "Reserved" 9 "Reserved" 8 "Reserved" 7 "Reserved" 6 "Reserved" 5 "Reserved" 4 "4th range" 3 "3rd range" 2 "2nd range" 1 "1st range" 0 "Neutral" ;
VAL_ 2566572286 DamageThresholdSt 7 "Not Available" 6 "Error" 5 "Reserved" 4 "Reserved" 3 "Transmission has reached a most severe or 'Red Stop Lamp' damage threshold" 2 "Transmission has reached a moderately severe or 'Amber Warning Lamp' damage threshold" 1 "Transmission has reached a low severity or 'Protect Lamp' damage threshold" 0 "Transmission has not reached a damage threshold" ;
VAL_ 2566572286 GearShiftCapability 7 "Not Available" 6 "Error" 5 "Transmission has disengaged the driveline" 4 "Transmission may not be able to shift" 3 "Transmission may not be able to up-shift" 2 "Transmission may not be able to down-shift" 1 "Transmission does not have all gears available" 0 "Transmission has full gear shift capability" ;
VAL_ 2566572286 LaunchCapability 7 "Not Available" 6 "Error" 5 "Transmission cannot launch in either direction" 4 "Transmission may not be able to launch in either direction" 3 "Transmission cannot launch in the forward direction" 2 "Transmission cannot launch in the reverse direction" 1 "Startup conditions" 0 "Transmission has full launch capability" ;
VAL_ 2566572286 Clutch1OverheatInd 3 "Not available" 2 "Clutch overheat indicator is flashing" 1 "Clutch overheat indicator is on continuously" 0 "Clutch overheat indicator is off" ;
VAL_ 2499462910 RoadSpdAccelerateSw 3 "Not available" 2 "Error" 1 "Retarder road speed activator in position 'accelerate'" 0 "Retarder road speed activator not in the position 'accelerate'" ;
VAL_ 2499462910 RoadSpdDecelerateSw 3 "Not available" 2 "Error" 1 "Retarder road speed activator in position 'decelerate'" 0 "Retarder road speed activator not in the position 'decelerate'" ;
VAL_ 2566571262 NomSupplyFreq 255 "Not available" 254 "Error" 2 "60 Hz" 0 "50 Hz" ;
VAL_ 2566569214 TransOilPressLowLamp 3 "Not available" 2 "Error" 1 "Lamp activated" 0 "Lamp deactivated" ;
VAL_ 2566569214 TransOilTempHiLamp 3 "Not available" 2 "Error" 1 "Lamp activated" 0 "Lamp deactivated" ;
VAL_ 2566568958 TransOilPressLowLamp 3 "Not available" 2 "Reserved" 1 "Lamp On" 0 "Lamp Off" ;
VAL_ 2566568958 TransOilTempHiLamp 3 "Not available" 2 "Reserved" 1 "Lamp On" 0 "Lamp Off" ;
VAL_ 2566568702 HybDCInletContactor1St 3 "Not available" 2 "Error- Contactor fault detected" 1 "Contactor Closed" 0 "Contactor Open" ;
VAL_ 2566568446 HybDCInletContactor1Cmd 3 "Don't Care / Take no action" 2 "Reserved" 1 "Close Contactor" 0 "Open Contactor" ;
VAL_ 2566568190 RespCode 255 "Not Available" 25 "FAILED Certificate Revoked" 24 "FAILED Certificate Not Allowed at this EVSE" 23 "FAILED Contactor Error" 22 "FAILED Wrong Energy Transfer Type" 21 "FAILED Metering Signature Not Valid" 20 "FAILED EVSE Present Voltage Too Low" 19 "FAILED Charging Profile Invalid" 18 "FAILED Tariff Selection Invalid" 17 "FAILED Power Delivery Not Applied" 16 "FAILED Wrong Charge Parameter" 15 "FAILED Contract Canceled" 14 "FAILED Challenge Invalid" 13 "FAILED Cert Chain Error" 12 "FAILED No Certificate Available" 11 "FAILED Signature Error" 10 "FAILED Certificate Expired" 9 "FAILED Payment Selection Invalid" 8 "FAILED Service Selection Invalid" 7 "FAILED Unknown Session" 6 "FAILED Service ID Invalid" 5 "FAILED Sequence Error" 4 "FAILED" 3 "OK Certificate Expires Soon" 2 "OK Old Session Joined" 1 "OK New Session Established" 0 "OK" ;
VAL_ 2566568190 ProcessingSt 3 "Not available" 2 "Ongoing, Waiting for Customer Interaction" 1 "Ongoing" 0 "Finished" ;
VAL_ 2566568190 IsolStatus 15 "Not available" 14 "Invalid" 13 "Reserved" 12 "Reserved" 11 "Reserved" 10 "Reserved" 9 "Reserved" 8 "Reserved" 7 "Reserved" 6 "Reserved" 5 "Reserved" 4 "Reserved" 3 "Reserved" 2 "Fault" 1 "Warning" 0 "Valid" ;
VAL_ 2566568190 Status 15 "Not available" 14 "No EVSE Connected" 13 "Reserved" 12 "Reserved" 11 "Reserved" 10 "Reserved" 9 "Reserved" 8 "Reserved" 7 "Reserved" 6 "Malfunction" 5 "Emergency Shutdown" 4 "Isolation Monitoring Active" 3 "Utility Interrupt Event" 2 "EVSE Shutdown" 1 "EVSE Ready" 0 "EVSE Not Ready" ;
VAL_ 2566568190 PLAchieved 3 "Not available" 2 "reserved" 1 "Limit achieved" 0 "Not limited or no EVSE connected" ;
VAL_ 2566568190 CurLmtAchieved 3 "Not available" 2 "reserved" 1 "Limit achieved" 0 "Not limited or no EVSE connected" ;
VAL_ 2566568190 VLmtAchieved 3 "Not available" 2 "reserved" 1 "Limit achieved" 0 "Not limited or no EVSE connected" ;
VAL_ 2566568190 ChargingSt 15 "Not available" 14 "EVSE fault" 13 "Battery Failure" 12 "Terminating" 11 "Pre-charge" 10 "Initializing" 9 "Cable Check" 8 "Charge Parameter Discovery" 7 "Welding Check" 6 "Power Delivery, Shutdown)" 5 "Authorizing" 4 "Power Delivery, Start-up)" 3 "Reserved" 2 "Standby" 1 "Charging" 0 "Idle" ;
VAL_ 2566567422 SupportedEnergyTransferTypes 15 "Data not available" 14 "Error" 13 "No EVSE connected" 12 "Reserved" 11 "Reserved" 10 "Reserved" 9 "Reserved" 8 "Reserved" 7 "Reserved" 6 "Reserved" 5 "Reserved" 4 "Reserved" 3 "AC-three-phase-core" 2 "AC-Single-phase-core" 1 "DC-Core" 0 "DC-Extended" ;
VAL_ 2566567166 HybReqEnergyTransferType 15 "Reserved" 14 "Reserved" 13 "Reserved" 12 "Reserved" 11 "Reserved" 10 "Reserved" 9 "Reserved" 8 "Reserved" 7 "Reserved" 6 "Reserved" 5 "Reserved" 4 "Reserved" 3 "Reserved" 2 "Reserved" 1 "DC-Core" 0 "DC-Extended" ;
VAL_ 2364689918 Data9EmbeddedIntegritySupport 3 "CRC and Counter are not supported by the sender" 2 "Reserved" 1 "Protection is supported using J1939-76 SHM" 0 "Embedded CRC and Counter are supported by the sender" ;
VAL_ 2364689918 HVESS10ThermalEventDetected 3 "Not available" 2 "Error" 1 "Thermal Event Detected" 0 "No Thermal Event Detected" ;
VAL_ 2364689406 TMSCoolantLvl 3 "Not Available" 2 "Error" 1 "Coolant Level is sufficient" 0 "Coolant Level is not sufficient" ;
VAL_ 2364689406 TMSMode 15 "Not Available" 14 "Faulted" 13 "Reserved" 12 "Reserved" 11 "Reserved" 10 "Reserved" 9 "Reserved" 8 "Reserved" 7 "Reserved" 6 "Reserved" 5 "Maintaining" 4 "Drying" 3 "Heating" 2 "Cooling" 1 "Circulating" 0 "Off" ;
VAL_ 2364689406 TMSHVILStatus 3 "Not Available" 2 "Error" 1 "HVIL Open" 0 "HVIL Closed" ;
VAL_ 2364689406 TMSHtrStatus 3 "Not Available" 2 "Error" 1 "Heater On" 0 "Heater Off" ;
VAL_ 2364689150 Module32OperationalStatus 3 "Not Available" 2 "Error" 1 "Operational" 0 "Not Operational" ;
VAL_ 2364689150 Module31OperationalStatus 3 "Not Available" 2 "Error" 1 "Operational" 0 "Not Operational" ;
VAL_ 2364689150 Module30OperationalStatus 3 "Not Available" 2 "Error" 1 "Operational" 0 "Not Operational" ;
VAL_ 2364689150 Module29OperationalStatus 3 "Not Available" 2 "Error" 1 "Operational" 0 "Not Operational" ;
VAL_ 2364689150 Module28OperationalStatus 3 "Not Available" 2 "Error" 1 "Operational" 0 "Not Operational" ;
VAL_ 2364689150 Module27OperationalStatus 3 "Not Available" 2 "Error" 1 "Operational" 0 "Not Operational" ;
VAL_ 2364689150 Module26OperationalStatus 3 "Not Available" 2 "Error" 1 "Operational" 0 "Not Operational" ;
VAL_ 2364689150 Module25OperationalStatus 3 "Not Available" 2 "Error" 1 "Operational" 0 "Not Operational" ;
VAL_ 2364689150 Module24OperationalStatus 3 "Not Available" 2 "Error" 1 "Operational" 0 "Not Operational" ;
VAL_ 2364689150 Module23OperationalStatus 3 "Not Available" 2 "Error" 1 "Operational" 0 "Not Operational" ;
VAL_ 2364689150 Module22OperationalStatus 3 "Not Available" 2 "Error" 1 "Operational" 0 "Not Operational" ;
VAL_ 2364689150 Module21OperationalStatus 3 "Not Available" 2 "Error" 1 "Operational" 0 "Not Operational" ;
VAL_ 2364689150 Module20OperationalStatus 3 "Not Available" 2 "Error" 1 "Operational" 0 "Not Operational" ;
VAL_ 2364689150 Module19OperationalStatus 3 "Not Available" 2 "Error" 1 "Operational" 0 "Not Operational" ;
VAL_ 2364689150 Module18OperationalStatus 3 "Not Available" 2 "Error" 1 "Operational" 0 "Not Operational" ;
VAL_ 2364689150 Module17OperationalStatus 3 "Not Available" 2 "Error" 1 "Operational" 0 "Not Operational" ;
VAL_ 2364689150 Module16OperationalStatus 3 "Not Available" 2 "Error" 1 "Operational" 0 "Not Operational" ;
VAL_ 2364689150 Module15OperationalStatus 3 "Not Available" 2 "Error" 1 "Operational" 0 "Not Operational" ;
VAL_ 2364689150 Module14OperationalStatus 3 "Not Available" 2 "Error" 1 "Operational" 0 "Not Operational" ;
VAL_ 2364689150 Module13OperationalStatus 3 "Not Available" 2 "Error" 1 "Operational" 0 "Not Operational" ;
VAL_ 2364689150 Module12OperationalStatus 3 "Not Available" 2 "Error" 1 "Operational" 0 "Not Operational" ;
VAL_ 2364689150 Module11OperationalStatus 3 "Not Available" 2 "Error" 1 "Operational" 0 "Not Operational" ;
VAL_ 2364689150 Module10OperationalStatus 3 "Not Available" 2 "Error" 1 "Operational" 0 "Not Operational" ;
VAL_ 2364689150 Module9OperationalStatus 3 "Not Available" 2 "Error" 1 "Operational" 0 "Not Operational" ;
VAL_ 2364689150 Module8OperationalStatus 3 "Not Available" 2 "Error" 1 "Operational" 0 "Not Operational" ;
VAL_ 2364689150 Module7OperationalStatus 3 "Not Available" 2 "Error" 1 "Operational" 0 "Not Operational" ;
VAL_ 2364689150 Module6OperationalStatus 3 "Not Available" 2 "Error" 1 "Operational" 0 "Not Operational" ;
VAL_ 2364689150 Module5OperationalStatus 3 "Not Available" 2 "Error" 1 "Operational" 0 "Not Operational" ;
VAL_ 2364689150 Module4OperationalStatus 3 "Not Available" 2 "Error" 1 "Operational" 0 "Not Operational" ;
VAL_ 2364689150 Module3OperationalStatus 3 "Not Available" 2 "Error" 1 "Operational" 0 "Not Operational" ;
VAL_ 2364689150 Module2OperationalStatus 3 "Not Available" 2 "Error" 1 "Operational" 0 "Not Operational" ;
VAL_ 2364689150 Module1OperationalStatus 3 "Not Available" 2 "Error" 1 "Operational" 0 "Not Operational" ;
